VERSION "created by canmatrix"

NS_ :

BS_:

BU_: IMU_MMP2 MAP DMS VIC GWS MGW ADAS FVC CR_RL CR_RR CR_FL CR_FR FR_FC AVAP

BO_ 1141 EPS_0x475: 8 MGW
 SG_ EPS_ModSts : 10|2@0+ (1,0) [0|3] ""  ADAS

BO_ 453 EPS2ADAS_0x1C5: 12 MGW
 SG_ ADAS_1C5_CheckSum : 7|8@0+ (1,0) [0|255] ""  ADAS
 SG_ ADAS_1C5_AliveCounter : 11|4@0+ (1,0) [0|15] ""  ADAS
 SG_ EPS_ActRoadWheelAngValue : 23|16@0+ (0.005,-45) [-45|45] "degree"  ADAS
 SG_ EPS_ActRPCTrq : 39|11@0+ (0.02,-20.48) [-20.48|20.46] "Nm"  ADAS
 SG_ EPS_LatDrvLvl12SrvAvl : 44|2@0+ (1,0) [0|3] ""  ADAS
 SG_ EPS_IntRPCMaxTrq : 42|11@0+ (0.02,-20.48) [-20.48|20.46] "Nm"  ADAS
 SG_ EPS_IntRPCMinTrq : 63|11@0+ (0.02,-20.48) [-20.48|20.46] "Nm"  ADAS
 SG_ EPS_LatMCHptcWrnSrvAvl : 68|2@0+ (1,0) [0|3] ""  ADAS
 SG_ EPS_ActRoadWheelAngState : 66|2@0+ (1,0) [0|3] ""  ADAS
 SG_ EPS_LatMCRoadWheelAngActive : 64|1@0+ (1,0) [0|1] ""  ADAS

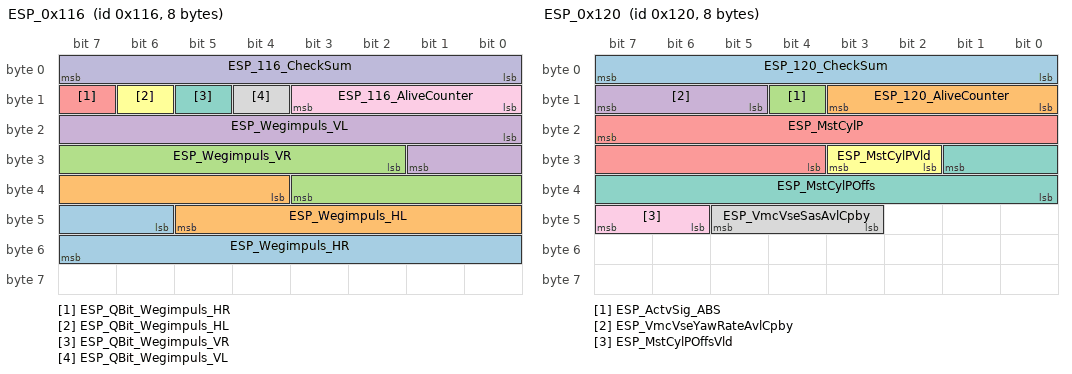
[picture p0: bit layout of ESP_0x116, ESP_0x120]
BO_ 278 ESP_0x116: 8 MGW
 SG_ ESP_Wegimpuls_HR : 46|10@1+ (1,0) [0|1000] ""  ADAS
 SG_ ESP_Wegimpuls_HL : 36|10@1+ (1,0) [0|1000] ""  ADAS
 SG_ ESP_Wegimpuls_VR : 26|10@1+ (1,0) [0|1000] ""  ADAS
 SG_ ESP_Wegimpuls_VL : 16|10@1+ (1,0) [0|1000] ""  ADAS
 SG_ ESP_QBit_Wegimpuls_HR : 15|1@1+ (1,0) [0|1] ""  ADAS
 SG_ ESP_QBit_Wegimpuls_HL : 14|1@1+ (1,0) [0|1] ""  ADAS
 SG_ ESP_QBit_Wegimpuls_VR : 13|1@1+ (1,0) [0|1] ""  ADAS
 SG_ ESP_QBit_Wegimpuls_VL : 12|1@1+ (1,0) [0|1] ""  ADAS
 SG_ ESP_116_AliveCounter : 8|4@1+ (1,0) [0|15] ""  ADAS
 SG_ ESP_116_CheckSum : 0|8@1+ (1,0) [0|255] ""  ADAS

BO_ 288 ESP_0x120: 8 MGW
 SG_ ESP_120_CheckSum : 7|8@0+ (1,0) [0|255] ""  ADAS,FVC,CR_RL,CR_RR,CR_FL,CR_FR,FR_FC
 SG_ ESP_120_AliveCounter : 11|4@0+ (1,0) [0|15] ""  ADAS,FVC,CR_RL,CR_RR,CR_FL,CR_FR,FR_FC
 SG_ ESP_ActvSig_ABS : 12|1@0+ (1,0) [0|1] ""  ADAS,FVC,CR_RL,CR_RR,CR_FL,CR_FR,FR_FC
 SG_ ESP_VmcVseYawRateAvlCpby : 15|3@0+ (1,0) [0|7] ""  ADAS,FR_FC
 SG_ ESP_MstCylP : 23|12@0+ (0.1,-30) [-30|276.6] "bar"  ADAS,FVC,CR_RL,CR_RR,CR_FL,CR_FR,FR_FC
 SG_ ESP_MstCylPVld : 27|2@0+ (1,0) [0|3] ""  ADAS,FVC,CR_RL,CR_RR,CR_FL,CR_FR,FR_FC
 SG_ ESP_MstCylPOffs : 25|10@0+ (0.1,-15) [-15|15] "bar"  ADAS,FVC,CR_RL,CR_RR,CR_FL,CR_FR,FR_FC
 SG_ ESP_VmcVseSasAvlCpby : 45|3@0+ (1,0) [0|7] ""  ADAS,FR_FC
 SG_ ESP_MstCylPOffsVld : 47|2@0+ (1,0) [0|3] ""  ADAS,FVC,CR_RL,CR_RR,CR_FL,CR_FR,FR_FC

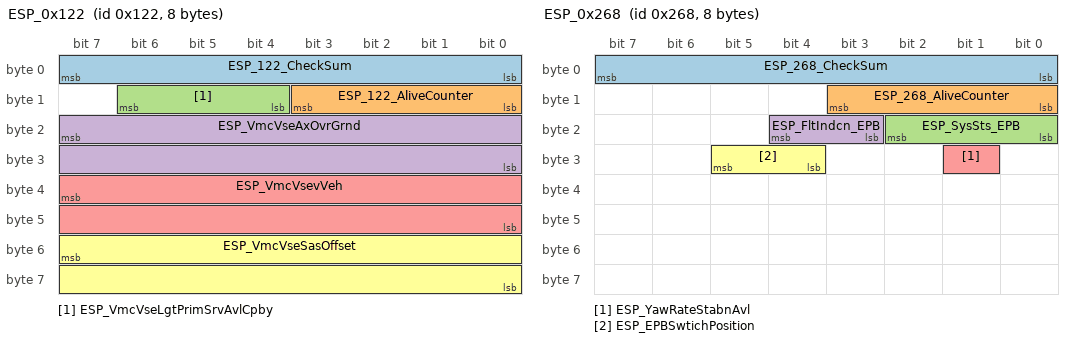
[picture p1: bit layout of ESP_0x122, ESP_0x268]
BO_ 290 ESP_0x122: 8 MGW
 SG_ ESP_122_CheckSum : 7|8@0+ (1,0) [0|255] ""  ADAS,FR_FC
 SG_ ESP_122_AliveCounter : 11|4@0+ (1,0) [0|15] ""  ADAS,FR_FC
 SG_ ESP_VmcVseLgtPrimSrvAvlCpby : 14|3@0+ (1,0) [0|7] ""  ADAS,FR_FC
 SG_ ESP_VmcVseAxOvrGrnd : 23|16@0+ (0.00125,-40.96) [-40.96|40.9575] "m/s2"  ADAS,FR_FC
 SG_ ESP_VmcVsevVeh : 39|16@0+ (0.01,-100) [-100|400] "kph"  ADAS,FR_FC
 SG_ ESP_VmcVseSasOffset : 55|16@0+ (0.1,-780) [-780|780] "°"  ADAS,FR_FC

BO_ 440 ESP_0x1B8: 8 MGW
 SG_ ESP_RoadSlop : 50|11@0+ (0.01,-10) [-10|10] "m/s2"  ADAS,FR_FC

BO_ 609 ESP_0x261: 8 MGW
 SG_ ESP_261_CheckSum : 7|8@0+ (1,0) [0|255] ""  ADAS,FVC,CR_RL,CR_RR,CR_FL,CR_FR,FR_FC
 SG_ ESP_261_AliveCounter : 11|4@0+ (1,0) [0|15] ""  ADAS,FVC,CR_RL,CR_RR,CR_FL,CR_FR,FR_FC
 SG_ ESP_ActvSig : 16|1@0+ (1,0) [0|1] ""  ADAS,FVC,CR_RL,CR_RR,CR_FL,CR_FR,FR_FC
 SG_ ESP_ActvSig_TCS : 17|1@0+ (1,0) [0|1] ""  ADAS,CR_RL,CR_RR,CR_FL,CR_FR,FR_FC
 SG_ ESP_ActvSig_EBD : 19|1@0+ (1,0) [0|1] ""  ADAS,CR_RL,CR_RR,CR_FL,CR_FR,FR_FC
 SG_ ESP_ActvSig_DTC : 20|1@0+ (1,0) [0|1] ""  ADAS,CR_RL,CR_RR,CR_FL,CR_FR,FR_FC
 SG_ ESP_Actvndcn_CDD : 24|1@0+ (1,0) [0|1] ""  ADAS
 SG_ ESP_FltIndcn_CDD : 25|1@0+ (1,0) [0|1] ""  ADAS
 SG_ ESP_ActvIndcn_ABA : 26|1@0+ (1,0) [0|1] ""  ADAS,FR_FC
 SG_ ESP_FltIndcn_ABA : 27|1@0+ (1,0) [0|1] ""  ADAS,FR_FC
 SG_ ESP_ActvIndcn_ABP : 28|1@0+ (1,0) [0|1] ""  ADAS,FR_FC
 SG_ ESP_FltIndcn_ABP : 29|1@0+ (1,0) [0|1] ""  ADAS,FR_FC
 SG_ ESP_ActvIndcn_AEB : 30|1@0+ (1,0) [0|1] ""  ADAS,CR_RL,CR_RR,FR_FC
 SG_ ESP_FltIndcn_AEB : 31|1@0+ (1,0) [0|1] ""  ADAS,CR_RL,CR_RR,FR_FC
 SG_ ESP_ActvIndcn_AWB : 32|1@0+ (1,0) [0|1] ""  ADAS,FR_FC
 SG_ ESP_FltIndcn_AWB : 33|1@0+ (1,0) [0|1] ""  ADAS,FR_FC
 SG_ ESP_VehStandstillIndcn : 35|2@0+ (1,0) [0|3] ""  ADAS,CR_RL,CR_RR,CR_FL,CR_FR,FR_FC
 SG_ ESP_BrkOverTIndcn : 36|1@0+ (1,0) [0|1] ""  ADAS,FR_FC

BO_ 616 ESP_0x268: 8 MGW
 SG_ ESP_268_CheckSum : 7|8@0+ (1,0) [0|255] ""  ADAS,FR_FC
 SG_ ESP_268_AliveCounter : 11|4@0+ (1,0) [0|15] ""  ADAS,FR_FC
 SG_ ESP_SysSts_EPB : 18|3@0+ (1,0) [0|7] ""  ADAS
 SG_ ESP_FltIndcn_EPB : 20|2@0+ (1,0) [0|3] ""  ADAS
 SG_ ESP_YawRateStabnAvl : 25|1@0+ (1,0) [0|1] ""  ADAS,FR_FC
 SG_ ESP_EPBSwtichPosition : 29|2@0+ (1,0) [0|3] ""  ADAS

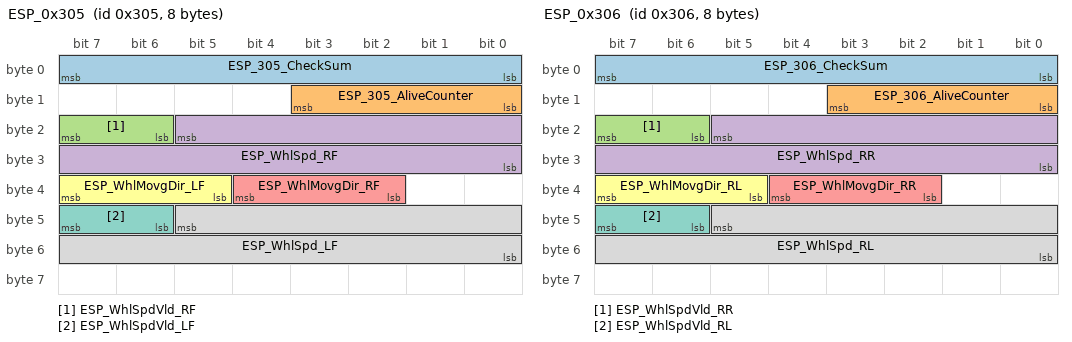
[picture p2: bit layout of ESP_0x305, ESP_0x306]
BO_ 773 ESP_0x305: 8 MGW
 SG_ ESP_305_CheckSum : 7|8@0+ (1,0) [0|255] ""  ADAS,FVC,CR_RL,CR_RR,CR_FL,CR_FR,FR_FC
 SG_ ESP_305_AliveCounter : 11|4@0+ (1,0) [0|15] ""  ADAS,FVC,CR_RL,CR_RR,CR_FL,CR_FR,FR_FC
 SG_ ESP_WhlSpdVld_RF : 23|2@0+ (1,0) [0|3] ""  ADAS,FVC,CR_RL,CR_RR,CR_FL,CR_FR,FR_FC
 SG_ ESP_WhlSpd_RF : 21|14@0+ (0.0625,0) [0|300] "km/h"  ADAS,FVC,CR_RL,CR_RR,CR_FL,CR_FR,FR_FC
 SG_ ESP_WhlMovgDir_RF : 36|3@0+ (1,0) [0|7] ""  ADAS,FVC,CR_RL,CR_RR,CR_FL,CR_FR,FR_FC
 SG_ ESP_WhlMovgDir_LF : 39|3@0+ (1,0) [0|7] ""  ADAS,FVC,CR_RL,CR_RR,CR_FL,CR_FR,FR_FC
 SG_ ESP_WhlSpdVld_LF : 47|2@0+ (1,0) [0|3] ""  ADAS,FVC,CR_RL,CR_RR,CR_FL,CR_FR,FR_FC
 SG_ ESP_WhlSpd_LF : 45|14@0+ (0.0625,0) [0|300] "km/h"  ADAS,FVC,CR_RL,CR_RR,CR_FL,CR_FR,FR_FC

BO_ 774 ESP_0x306: 8 MGW
 SG_ ESP_306_CheckSum : 7|8@0+ (1,0) [0|255] ""  ADAS,FVC,CR_RL,CR_RR,CR_FL,CR_FR,FR_FC
 SG_ ESP_306_AliveCounter : 11|4@0+ (1,0) [0|15] ""  ADAS,FVC,CR_RL,CR_RR,CR_FL,CR_FR,FR_FC
 SG_ ESP_WhlSpdVld_RR : 23|2@0+ (1,0) [0|3] ""  ADAS,FVC,CR_RL,CR_RR,CR_FL,CR_FR,FR_FC
 SG_ ESP_WhlSpd_RR : 21|14@0+ (0.0625,0) [0|300] "km/h"  ADAS,FVC,CR_RL,CR_RR,CR_FL,CR_FR,FR_FC
 SG_ ESP_WhlMovgDir_RR : 36|3@0+ (1,0) [0|7] ""  ADAS,FVC,CR_RL,CR_RR,CR_FL,CR_FR,FR_FC
 SG_ ESP_WhlMovgDir_RL : 39|3@0+ (1,0) [0|7] ""  ADAS,FVC,CR_RL,CR_RR,CR_FL,CR_FR,FR_FC
 SG_ ESP_WhlSpdVld_RL : 47|2@0+ (1,0) [0|3] ""  ADAS,FVC,CR_RL,CR_RR,CR_FL,CR_FR,FR_FC
 SG_ ESP_WhlSpd_RL : 45|14@0+ (0.0625,0) [0|300] "km/h"  ADAS,FVC,CR_RL,CR_RR,CR_FL,CR_FR,FR_FC

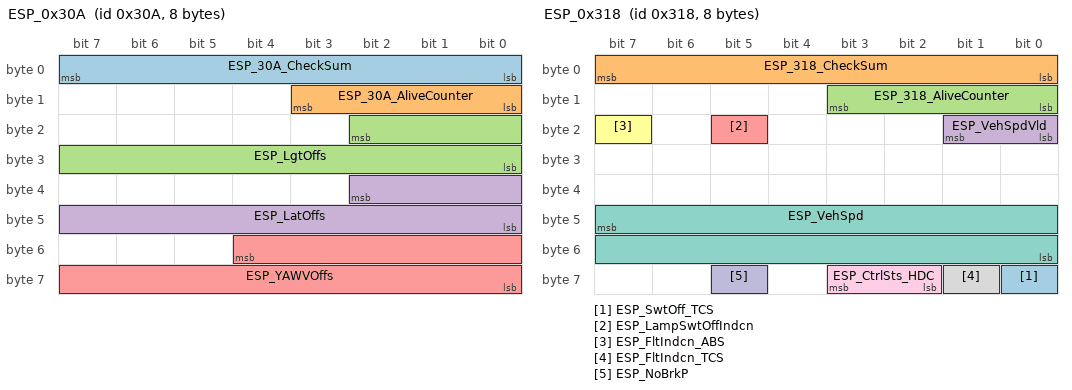
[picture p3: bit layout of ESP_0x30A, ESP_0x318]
BO_ 778 ESP_0x30A: 8 MGW
 SG_ ESP_30A_CheckSum : 7|8@0+ (1,0) [0|255] ""  ADAS,FVC,CR_RL,CR_RR,CR_FL,CR_FR,FR_FC
 SG_ ESP_30A_AliveCounter : 11|4@0+ (1,0) [0|15] ""  ADAS,FVC,CR_RL,CR_RR,CR_FL,CR_FR,FR_FC
 SG_ ESP_LgtOffs : 18|11@0+ (0.0027127,-2.15928) [-2.15928|2.15928] "g"  ADAS,FVC,FR_FC
 SG_ ESP_LatOffs : 34|11@0+ (0.0027127,-2.15928) [-2.15928|2.15928] "g"  ADAS,FVC,FR_FC
 SG_ ESP_YAWVOffs : 52|13@0+ (0.056,-120) [-120|120] "°/s"  ADAS,FVC,FR_FC

BO_ 792 ESP_0x318: 8 MGW
 SG_ ESP_SwtOff_TCS : 56|1@0+ (1,0) [0|1] "" Vector__XXX
 SG_ ESP_318_CheckSum : 7|8@0+ (1,0) [0|255] ""  ADAS,FVC,CR_RL,CR_RR,CR_FL,CR_FR,FR_FC
 SG_ ESP_318_AliveCounter : 11|4@0+ (1,0) [0|15] ""  ADAS,FVC,CR_RL,CR_RR,CR_FL,CR_FR,FR_FC
 SG_ ESP_VehSpdVld : 17|2@0+ (1,0) [0|3] ""  ADAS,FVC,CR_RL,CR_RR,CR_FL,CR_FR,FR_FC
 SG_ ESP_LampSwtOffIndcn : 21|1@0+ (1,0) [0|1] ""  ADAS,CR_RL,CR_RR,CR_FL,CR_FR,FR_FC
 SG_ ESP_FltIndcn_ABS : 23|1@0+ (1,0) [0|1] ""  ADAS,FVC,CR_RL,CR_RR,CR_FL,CR_FR,FR_FC
 SG_ ESP_VehSpd : 47|16@0+ (0.1,0) [0|300] "km/h"  ADAS,FVC,CR_RL,CR_RR,CR_FL,CR_FR,FR_FC
 SG_ ESP_FltIndcn_TCS : 57|1@0+ (1,0) [0|1] ""  ADAS,FVC,CR_RL,CR_RR,CR_FL,CR_FR,FR_FC
 SG_ ESP_CtrlSts_HDC : 59|2@0+ (1,0) [0|3] ""  ADAS,CR_RL,CR_RR,CR_FL,CR_FR,FR_FC
 SG_ ESP_NoBrkP : 61|1@0+ (1,0) [0|1] ""  ADAS,CR_RL,CR_RR,CR_FL,CR_FR,FR_FC

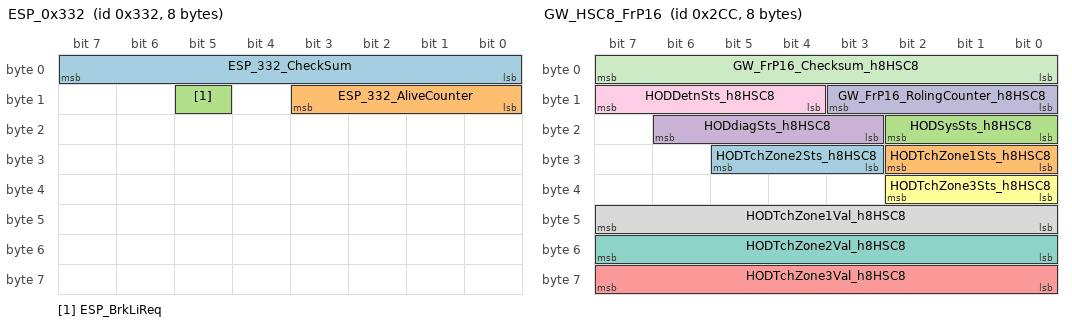
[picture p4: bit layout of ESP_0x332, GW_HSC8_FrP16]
BO_ 818 ESP_0x332: 8 MGW
 SG_ ESP_332_CheckSum : 7|8@0+ (1,0) [0|255] ""  ADAS,FR_FC
 SG_ ESP_332_AliveCounter : 11|4@0+ (1,0) [0|15] ""  ADAS,FR_FC
 SG_ ESP_BrkLiReq : 13|1@0+ (1,0) [0|1] ""  ADAS,FR_FC

BO_ 716 GW_HSC8_FrP16: 8 MGW
 SG_ HODTchZone2Sts_h8HSC8 : 27|3@1+ (1,0) [0|7] ""  ADAS
 SG_ HODTchZone1Sts_h8HSC8 : 24|3@1+ (1,0) [0|7] ""  ADAS
 SG_ HODSysSts_h8HSC8 : 16|3@1+ (1,0) [0|7] ""  ADAS
 SG_ HODdiagSts_h8HSC8 : 19|4@1+ (1,0) [0|15] ""  ADAS
 SG_ HODTchZone3Val_h8HSC8 : 56|8@1+ (1,0) [0|255] ""  ADAS
 SG_ HODTchZone3Sts_h8HSC8 : 32|3@1+ (1,0) [0|7] ""  ADAS
 SG_ HODTchZone2Val_h8HSC8 : 48|8@1+ (1,0) [0|255] ""  ADAS
 SG_ HODTchZone1Val_h8HSC8 : 40|8@1+ (1,0) [0|255] ""  ADAS
 SG_ HODDetnSts_h8HSC8 : 12|4@1+ (1,0) [0|15] ""  ADAS
 SG_ GW_FrP16_RolingCounter_h8HSC8 : 8|4@1+ (1,0) [0|15] ""  ADAS
 SG_ GW_FrP16_Checksum_h8HSC8 : 0|8@1+ (1,0) [0|255] ""  ADAS

BO_ 1554 HandoverIndication: 1 MGW
 SG_ HandoverIndication : 0|2@1+ (1,0) [0|3] ""  ADAS

BO_ 1218 HDM_Centerline_1: 64 MAP
 SG_ centerline_1_CRC : 0|16@1+ (1,0) [0|65535] ""  ADAS
 SG_ centerline_1_AliveCtr : 16|8@1+ (1,0) [0|255] ""  ADAS
 SG_ CenterPoint_dx_00 : 24|12@1+ (0.05,0) [0|204.75] "m"  ADAS
 SG_ CenterPoint_dy_00 : 36|12@1+ (0.05,-102.4) [-102.4|102.35] "m"  ADAS
 SG_ CenterPoint_dx_01 : 48|12@1+ (0.05,0) [0|204.75] "m"  ADAS
 SG_ CenterPoint_dy_01 : 60|12@1+ (0.05,-102.4) [-102.4|102.35] "m"  ADAS
 SG_ CenterPoint_dx_02 : 72|12@1+ (0.05,0) [0|204.75] "m"  ADAS
 SG_ CenterPoint_dy_02 : 84|12@1+ (0.05,-102.4) [-102.4|102.35] "m"  ADAS
 SG_ CenterPoint_dx_03 : 96|12@1+ (0.05,0) [0|204.75] "m"  ADAS
 SG_ CenterPoint_dy_03 : 108|12@1+ (0.05,-102.4) [-102.4|102.35] "m"  ADAS
 SG_ CenterPoint_dx_04 : 120|12@1+ (0.05,0) [0|204.75] "m"  ADAS
 SG_ CenterPoint_dy_04 : 132|12@1+ (0.05,-102.4) [-102.4|102.35] "m"  ADAS
 SG_ CenterPoint_dx_05 : 144|12@1+ (0.05,0) [0|204.75] "m"  ADAS
 SG_ CenterPoint_dy_05 : 156|12@1+ (0.05,-102.4) [-102.4|102.35] "m"  ADAS
 SG_ CenterPoint_dx_06 : 168|12@1+ (0.05,0) [0|204.75] "m"  ADAS
 SG_ CenterPoint_dy_06 : 180|12@1+ (0.05,-102.4) [-102.4|102.35] "m"  ADAS
 SG_ CenterPoint_dx_07 : 192|12@1+ (0.05,0) [0|204.75] "m"  ADAS
 SG_ CenterPoint_dy_07 : 204|12@1+ (0.05,-102.4) [-102.4|102.35] "m"  ADAS
 SG_ CenterPoint_dx_08 : 216|12@1+ (0.05,0) [0|204.75] "m"  ADAS
 SG_ CenterPoint_dy_08 : 228|12@1+ (0.05,-102.4) [-102.4|102.35] "m"  ADAS
 SG_ CenterPoint_dx_09 : 240|12@1+ (0.05,0) [0|204.75] "m"  ADAS
 SG_ CenterPoint_dy_09 : 252|12@1+ (0.05,-102.4) [-102.4|102.35] "m"  ADAS
 SG_ CenterPoint_dx_10 : 264|12@1+ (0.05,0) [0|204.75] "m"  ADAS
 SG_ CenterPoint_dy_10 : 276|12@1+ (0.05,-102.4) [-102.4|102.35] "m"  ADAS
 SG_ CenterPoint_dx_11 : 288|12@1+ (0.05,0) [0|204.75] "m"  ADAS
 SG_ CenterPoint_dy_11 : 300|12@1+ (0.05,-102.4) [-102.4|102.35] "m"  ADAS
 SG_ CenterPoint_dx_12 : 312|12@1+ (0.05,0) [0|204.75] "m"  ADAS
 SG_ CenterPoint_dy_12 : 324|12@1+ (0.05,-102.4) [-102.4|102.35] "m"  ADAS
 SG_ CenterPoint_dx_13 : 336|12@1+ (0.05,0) [0|204.75] "m"  ADAS
 SG_ CenterPoint_dy_13 : 348|12@1+ (0.05,-102.4) [-102.4|102.35] "m"  ADAS
 SG_ CenterPoint_dx_14 : 360|12@1+ (0.05,0) [0|204.75] "m"  ADAS
 SG_ CenterPoint_dy_14 : 372|12@1+ (0.05,-102.4) [-102.4|102.35] "m"  ADAS
 SG_ CenterPoint_dx_15 : 384|12@1+ (0.05,0) [0|204.75] "m"  ADAS
 SG_ CenterPoint_dy_15 : 396|12@1+ (0.05,-102.4) [-102.4|102.35] "m"  ADAS
 SG_ CenterPoint_dx_16 : 408|12@1+ (0.05,0) [0|204.75] "m"  ADAS
 SG_ CenterPoint_dy_16 : 420|12@1+ (0.05,-102.4) [-102.4|102.35] "m"  ADAS
 SG_ CenterPoint_dx_17 : 432|12@1+ (0.05,0) [0|204.75] "m"  ADAS
 SG_ CenterPoint_dy_17 : 444|12@1+ (0.05,-102.4) [-102.4|102.35] "m"  ADAS
 SG_ CenterPoint_dx_18 : 456|12@1+ (0.05,0) [0|204.75] "m"  ADAS
 SG_ CenterPoint_dy_18 : 468|12@1+ (0.05,-102.4) [-102.4|102.35] "m"  ADAS
 SG_ CenterPoint_dx_19 : 480|12@1+ (0.05,0) [0|204.75] "m"  ADAS
 SG_ CenterPoint_dy_19 : 492|12@1+ (0.05,-102.4) [-102.4|102.35] "m"  ADAS
 SG_ centerline_1_BlockCtr : 504|4@1+ (1,0) [0|15] ""  ADAS

BO_ 1219 HDM_Centerline_2: 64 MAP
 SG_ centerline_2_CRC : 0|16@1+ (1,0) [0|65535] ""  ADAS
 SG_ centerline_2_AliveCtr : 16|8@1+ (1,0) [0|255] ""  ADAS
 SG_ CenterPoint_dx_20 : 24|12@1+ (0.05,0) [0|204.75] "m"  ADAS
 SG_ CenterPoint_dy_20 : 36|12@1+ (0.05,-102.4) [-102.4|102.35] "m"  ADAS
 SG_ CenterPoint_dx_21 : 48|12@1+ (0.05,0) [0|204.75] "m"  ADAS
 SG_ CenterPoint_dy_21 : 60|12@1+ (0.05,-102.4) [-102.4|102.35] "m"  ADAS
 SG_ CenterPoint_dx_22 : 72|12@1+ (0.05,0) [0|204.75] "m"  ADAS
 SG_ CenterPoint_dy_22 : 84|12@1+ (0.05,-102.4) [-102.4|102.35] "m"  ADAS
 SG_ CenterPoint_dx_23 : 96|12@1+ (0.05,0) [0|204.75] "m"  ADAS
 SG_ CenterPoint_dy_23 : 108|12@1+ (0.05,-102.4) [-102.4|102.35] "m"  ADAS
 SG_ CenterPoint_dx_24 : 120|12@1+ (0.05,0) [0|204.75] "m"  ADAS
 SG_ CenterPoint_dy_24 : 132|12@1+ (0.05,-102.4) [-102.4|102.35] "m"  ADAS
 SG_ CenterPoint_dx_25 : 144|12@1+ (0.05,0) [0|204.75] "m"  ADAS
 SG_ CenterPoint_dy_25 : 156|12@1+ (0.05,-102.4) [-102.4|102.35] "m"  ADAS
 SG_ CenterPoint_dx_26 : 168|12@1+ (0.05,0) [0|204.75] "m"  ADAS
 SG_ CenterPoint_dy_26 : 180|12@1+ (0.05,-102.4) [-102.4|102.35] "m"  ADAS
 SG_ CenterPoint_dx_27 : 192|12@1+ (0.05,0) [0|204.75] "m"  ADAS
 SG_ CenterPoint_dy_27 : 204|12@1+ (0.05,-102.4) [-102.4|102.35] "m"  ADAS
 SG_ CenterPoint_dx_28 : 216|12@1+ (0.05,0) [0|204.75] "m"  ADAS
 SG_ CenterPoint_dy_28 : 228|12@1+ (0.05,-102.4) [-102.4|102.35] "m"  ADAS
 SG_ CenterPoint_dx_29 : 240|12@1+ (0.05,0) [0|204.75] "m"  ADAS
 SG_ CenterPoint_dy_29 : 252|12@1+ (0.05,-102.4) [-102.4|102.35] "m"  ADAS
 SG_ CenterPoint_dx_30 : 264|12@1+ (0.05,0) [0|204.75] "m"  ADAS
 SG_ CenterPoint_dy_30 : 276|12@1+ (0.05,-102.4) [-102.4|102.35] "m"  ADAS
 SG_ CenterPoint_dx_31 : 288|12@1+ (0.05,0) [0|204.75] "m"  ADAS
 SG_ CenterPoint_dy_31 : 300|12@1+ (0.05,-102.4) [-102.4|102.35] "m"  ADAS
 SG_ CenterPoint_dx_32 : 312|12@1+ (0.05,0) [0|204.75] "m"  ADAS
 SG_ CenterPoint_dy_32 : 324|12@1+ (0.05,-102.4) [-102.4|102.35] "m"  ADAS
 SG_ CenterPoint_dx_33 : 336|12@1+ (0.05,0) [0|204.75] "m"  ADAS
 SG_ CenterPoint_dy_33 : 348|12@1+ (0.05,-102.4) [-102.4|102.35] "m"  ADAS
 SG_ CenterPoint_dx_34 : 360|12@1+ (0.05,0) [0|204.75] "m"  ADAS
 SG_ CenterPoint_dy_34 : 372|12@1+ (0.05,-102.4) [-102.4|102.35] "m"  ADAS
 SG_ centerline_LaneWidth : 384|9@1+ (1,0) [0|511] "cm"  ADAS
 SG_ localization_lat_StdDev : 393|12@1+ (0.01,0) [0|40.95] "m"  ADAS
 SG_ localization_long_StdDev : 405|12@1+ (0.01,0) [0|40.95] "m"  ADAS
 SG_ localization_heading_StdDev : 417|11@1+ (0.1,0) [0|204.7] "degree"  ADAS
 SG_ map_position_deviation : 428|12@1+ (1,0) [0|4095] "cm"  ADAS
 SG_ map_position_accuracy : 440|12@1+ (1,0) [0|4095] "cm"  ADAS
 SG_ Timestamp : 452|20@1+ (0.00065536,0) [0|687.194112] "s"  ADAS
 SG_ centerline_2_BlockCtr : 472|4@1+ (1,0) [0|15] ""  ADAS

BO_ 1221 HDM_Central_Line_HighR: 64 MAP
 SG_ centerline_HR_CRC : 0|16@1+ (1,0) [0|65535] ""  ADAS
 SG_ centerline_HR_AliveCtr : 16|8@1+ (1,0) [0|255] ""  ADAS
 SG_ centerline_HR_BlockCtr : 24|4@1+ (1,0) [0|15] ""  ADAS
 SG_ CenterPoint_dx_m01_HighR : 28|6@1+ (0.001,0) [0|0.049] "m"  ADAS
 SG_ CenterPoint_dy_m01_HighR : 34|6@1+ (0.001,0) [0|0.049] "m"  ADAS
 SG_ CenterPoint_dy_m02_HighR : 40|6@1+ (0.001,0) [0|0.049] "m"  ADAS
 SG_ CenterPoint_dx_m02_HighR : 46|6@1+ (0.001,0) [0|0.049] "m"  ADAS
 SG_ CenterPoint_dy_m03_HighR : 52|6@1+ (0.001,0) [0|0.049] "m"  ADAS
 SG_ CenterPoint_dx_m03_HighR : 58|6@1+ (0.001,0) [0|0.049] "m"  ADAS
 SG_ CenterPoint_dy_m04_HighR : 64|6@1+ (0.001,0) [0|0.049] "m"  ADAS
 SG_ CenterPoint_dx_m04_HighR : 70|6@1+ (0.001,0) [0|0.049] "m"  ADAS
 SG_ CenterPoint_dy_00_HighR : 76|6@1+ (0.001,0) [0|0.049] "m"  ADAS
 SG_ CenterPoint_dx_00_HighR : 82|6@1+ (0.001,0) [0|0.049] "m"  ADAS
 SG_ CenterPoint_dy_01_HighR : 88|6@1+ (0.001,0) [0|0.049] "m"  ADAS
 SG_ CenterPoint_dx_01_HighR : 94|6@1+ (0.001,0) [0|0.049] "m"  ADAS
 SG_ CenterPoint_dy_02_HighR : 100|6@1+ (0.001,0) [0|0.049] "m"  ADAS
 SG_ CenterPoint_dx_02_HighR : 106|6@1+ (0.001,0) [0|0.049] "m"  ADAS
 SG_ CenterPoint_dy_03_HighR : 112|6@1+ (0.001,0) [0|0.049] "m"  ADAS
 SG_ CenterPoint_dx_03_HighR : 118|6@1+ (0.001,0) [0|0.049] "m"  ADAS
 SG_ CenterPoint_dy_04_HighR : 124|6@1+ (0.001,0) [0|0.049] "m"  ADAS
 SG_ CenterPoint_dx_04_HighR : 130|6@1+ (0.001,0) [0|0.049] "m"  ADAS
 SG_ CenterPoint_dy_05_HighR : 136|6@1+ (0.001,0) [0|0.049] "m"  ADAS
 SG_ CenterPoint_dx_05_HighR : 142|6@1+ (0.001,0) [0|0.049] "m"  ADAS
 SG_ CenterPoint_dy_06_HighR : 148|6@1+ (0.001,0) [0|0.049] "m"  ADAS
 SG_ CenterPoint_dx_06_HighR : 154|6@1+ (0.001,0) [0|0.049] "m"  ADAS
 SG_ CenterPoint_dy_07_HighR : 160|6@1+ (0.001,0) [0|0.049] "m"  ADAS
 SG_ CenterPoint_dx_07_HighR : 166|6@1+ (0.001,0) [0|0.049] "m"  ADAS
 SG_ CenterPoint_dy_08_HighR : 172|6@1+ (0.001,0) [0|0.049] "m"  ADAS
 SG_ CenterPoint_dx_08_HighR : 178|6@1+ (0.001,0) [0|0.049] "m"  ADAS
 SG_ CenterPoint_dy_09_HighR : 184|6@1+ (0.001,0) [0|0.049] "m"  ADAS
 SG_ CenterPoint_dx_09_HighR : 190|6@1+ (0.001,0) [0|0.049] "m"  ADAS
 SG_ CenterPoint_dy_10_HighR : 196|6@1+ (0.001,0) [0|0.049] "m"  ADAS
 SG_ CenterPoint_dx_10_HighR : 202|6@1+ (0.001,0) [0|0.049] "m"  ADAS
 SG_ CenterPoint_dy_11_HighR : 208|6@1+ (0.001,0) [0|0.049] "m"  ADAS
 SG_ CenterPoint_dx_11_HighR : 214|6@1+ (0.001,0) [0|0.049] "m"  ADAS
 SG_ CenterPoint_dy_12_HighR : 220|6@1+ (0.001,0) [0|0.049] "m"  ADAS
 SG_ CenterPoint_dx_12_HighR : 226|6@1+ (0.001,0) [0|0.049] "m"  ADAS
 SG_ CenterPoint_dy_13_HighR : 232|6@1+ (0.001,0) [0|0.049] "m"  ADAS
 SG_ CenterPoint_dx_13_HighR : 238|6@1+ (0.001,0) [0|0.049] "m"  ADAS
 SG_ CenterPoint_dy_14_HighR : 244|6@1+ (0.001,0) [0|0.049] "m"  ADAS
 SG_ CenterPoint_dx_14_HighR : 250|6@1+ (0.001,0) [0|0.049] "m"  ADAS
 SG_ CenterPoint_dy_15_HighR : 256|6@1+ (0.001,0) [0|0.049] "m"  ADAS
 SG_ CenterPoint_dx_15_HighR : 262|6@1+ (0.001,0) [0|0.049] "m"  ADAS
 SG_ CenterPoint_dy_16_HighR : 268|6@1+ (0.001,0) [0|0.049] "m"  ADAS
 SG_ CenterPoint_dx_16_HighR : 274|6@1+ (0.001,0) [0|0.049] "m"  ADAS
 SG_ CenterPoint_dy_17_HighR : 280|6@1+ (0.001,0) [0|0.049] "m"  ADAS
 SG_ CenterPoint_dx_17_HighR : 286|6@1+ (0.001,0) [0|0.049] "m"  ADAS
 SG_ CenterPoint_dy_18_HighR : 292|6@1+ (0.001,0) [0|0.049] "m"  ADAS
 SG_ CenterPoint_dx_18_HighR : 298|6@1+ (0.001,0) [0|0.049] "m"  ADAS
 SG_ CenterPoint_dy_19_HighR : 304|6@1+ (0.001,0) [0|0.049] "m"  ADAS
 SG_ CenterPoint_dx_19_HighR : 310|6@1+ (0.001,0) [0|0.049] "m"  ADAS
 SG_ CenterPoint_dy_20_HighR : 316|6@1+ (0.001,0) [0|0.049] "m"  ADAS
 SG_ CenterPoint_dx_20_HighR : 322|6@1+ (0.001,0) [0|0.049] "m"  ADAS
 SG_ CenterPoint_dy_21_HighR : 328|6@1+ (0.001,0) [0|0.049] "m"  ADAS
 SG_ CenterPoint_dx_21_HighR : 334|6@1+ (0.001,0) [0|0.049] "m"  ADAS
 SG_ CenterPoint_dy_22_HighR : 340|6@1+ (0.001,0) [0|0.049] "m"  ADAS
 SG_ CenterPoint_dx_22_HighR : 346|6@1+ (0.001,0) [0|0.049] "m"  ADAS
 SG_ CenterPoint_dy_23_HighR : 352|6@1+ (0.001,0) [0|0.049] "m"  ADAS
 SG_ CenterPoint_dx_23_HighR : 358|6@1+ (0.001,0) [0|0.049] "m"  ADAS
 SG_ CenterPoint_dy_24_HighR : 364|6@1+ (0.001,0) [0|0.049] "m"  ADAS
 SG_ CenterPoint_dx_24_HighR : 370|6@1+ (0.001,0) [0|0.049] "m"  ADAS
 SG_ CenterPoint_dy_25_HighR : 376|6@1+ (0.001,0) [0|0.049] "m"  ADAS
 SG_ CenterPoint_dx_25_HighR : 382|6@1+ (0.001,0) [0|0.049] "m"  ADAS
 SG_ CenterPoint_dy_26_HighR : 388|6@1+ (0.001,0) [0|0.049] "m"  ADAS
 SG_ CenterPoint_dx_26_HighR : 394|6@1+ (0.001,0) [0|0.049] "m"  ADAS
 SG_ CenterPoint_dy_27_HighR : 400|6@1+ (0.001,0) [0|0.049] "m"  ADAS
 SG_ CenterPoint_dx_27_HighR : 406|6@1+ (0.001,0) [0|0.049] "m"  ADAS
 SG_ CenterPoint_dy_28_HighR : 412|6@1+ (0.001,0) [0|0.049] "m"  ADAS
 SG_ CenterPoint_dx_28_HighR : 418|6@1+ (0.001,0) [0|0.049] "m"  ADAS
 SG_ CenterPoint_dy_29_HighR : 424|6@1+ (0.001,0) [0|0.049] "m"  ADAS
 SG_ CenterPoint_dx_29_HighR : 430|6@1+ (0.001,0) [0|0.049] "m"  ADAS
 SG_ CenterPoint_dy_30_HighR : 436|6@1+ (0.001,0) [0|0.049] "m"  ADAS
 SG_ CenterPoint_dx_30_HighR : 442|6@1+ (0.001,0) [0|0.049] "m"  ADAS
 SG_ CenterPoint_dy_31_HighR : 448|6@1+ (0.001,0) [0|0.049] "m"  ADAS
 SG_ CenterPoint_dx_31_HighR : 454|6@1+ (0.001,0) [0|0.049] "m"  ADAS
 SG_ CenterPoint_dy_32_HighR : 460|6@1+ (0.001,0) [0|0.049] "m"  ADAS
 SG_ CenterPoint_dx_32_HighR : 466|6@1+ (0.001,0) [0|0.049] "m"  ADAS
 SG_ CenterPoint_dy_33_HighR : 472|6@1+ (0.001,0) [0|0.049] "m"  ADAS
 SG_ CenterPoint_dx_33_HighR : 478|6@1+ (0.001,0) [0|0.049] "m"  ADAS
 SG_ CenterPoint_dy_34_HighR : 484|6@1+ (0.001,0) [0|0.049] "m"  ADAS
 SG_ CenterPoint_dx_34_HighR : 490|6@1+ (0.001,0) [0|0.049] "m"  ADAS

BO_ 1220 HDM_Central_Line_M: 24 MAP
 SG_ centerline_m_CRC : 0|16@1+ (1,0) [0|65535] ""  ADAS
 SG_ centerline_m_AliveCtr : 16|8@1+ (1,0) [0|255] ""  ADAS
 SG_ centerline_m_BlockCtr : 24|4@1+ (1,0) [0|15] ""  ADAS
 SG_ CenterPoint_dx_m01 : 28|10@1+ (0.05,-50) [-50|0] "m"  ADAS
 SG_ CenterPoint_dy_m01 : 38|12@1+ (0.05,-102.4) [-102.4|102.35] "m"  ADAS
 SG_ CenterPoint_dx_m02 : 50|10@1+ (0.05,-50) [-50|0] "m"  ADAS
 SG_ CenterPoint_dy_m02 : 60|12@1+ (0.05,-102.4) [-102.4|102.35] "m"  ADAS
 SG_ CenterPoint_dx_m03 : 72|10@1+ (0.05,-50) [-50|0] "m"  ADAS
 SG_ CenterPoint_dy_m03 : 82|12@1+ (0.05,-102.4) [-102.4|102.35] "m"  ADAS
 SG_ CenterPoint_dx_m04 : 94|10@1+ (0.05,-50) [-50|0] "m"  ADAS
 SG_ CenterPoint_dy_m04 : 104|12@1+ (0.05,-102.4) [-102.4|102.35] "m"  ADAS
 SG_ MAP_TimeSync : 116|48@1+ (1,0) [0|39636172800000] "ms"  ADAS

BO_ 1217 HDM_Curv: 64 MAP
 SG_ Cv_CRC : 0|16@1+ (1,0) [0|65535] ""  ADAS
 SG_ Cv_AliveCtr : 16|8@1+ (1,0) [0|255] ""  ADAS
 SG_ Cv_Value_Seg00 : 32|10@1+ (0.0001,0) [0|0.1] "1/m"  ADAS
 SG_ Cv_Value_Seg01 : 42|10@1+ (0.0001,0) [0|0.1] "1/m"  ADAS
 SG_ Cv_Value_Seg02 : 52|10@1+ (0.0001,0) [0|0.1] "1/m"  ADAS
 SG_ Cv_Value_Seg03 : 62|10@1+ (0.0001,0) [0|0.1] "1/m"  ADAS
 SG_ Cv_Value_Seg04 : 72|10@1+ (0.0001,0) [0|0.1] "1/m"  ADAS
 SG_ Cv_Value_Seg05 : 82|10@1+ (0.0001,0) [0|0.1] "1/m"  ADAS
 SG_ Cv_Value_Seg06 : 92|10@1+ (0.0001,0) [0|0.1] "1/m"  ADAS
 SG_ Cv_Value_Seg07 : 102|10@1+ (0.0001,0) [0|0.1] "1/m"  ADAS
 SG_ Cv_Value_Seg08 : 112|10@1+ (0.0001,0) [0|0.1] "1/m"  ADAS
 SG_ Cv_Value_Seg09 : 122|10@1+ (0.0001,0) [0|0.1] "1/m"  ADAS
 SG_ Cv_Value_Seg10 : 132|10@1+ (0.0001,0) [0|0.1] "1/m"  ADAS
 SG_ Cv_Value_Seg11 : 142|10@1+ (0.0001,0) [0|0.1] "1/m"  ADAS
 SG_ Cv_Value_Seg12 : 152|10@1+ (0.0001,0) [0|0.1] "1/m"  ADAS
 SG_ Cv_Value_Seg13 : 162|10@1+ (0.0001,0) [0|0.1] "1/m"  ADAS
 SG_ Cv_Value_Seg14 : 172|10@1+ (0.0001,0) [0|0.1] "1/m"  ADAS
 SG_ Cv_Value_Seg15 : 182|10@1+ (0.0001,0) [0|0.1] "1/m"  ADAS
 SG_ Cv_Value_Seg16 : 192|10@1+ (0.0001,0) [0|0.1] "1/m"  ADAS
 SG_ Cv_Value_Seg17 : 202|10@1+ (0.0001,0) [0|0.1] "1/m"  ADAS
 SG_ Cv_Value_Seg18 : 212|10@1+ (0.0001,0) [0|0.1] "1/m"  ADAS
 SG_ Cv_Value_Seg19 : 222|10@1+ (0.0001,0) [0|0.1] "1/m"  ADAS
 SG_ Cv_Offset_Seg00 : 232|10@1+ (1,0) [0|1023] "m"  ADAS
 SG_ Cv_Offset_Seg01 : 242|10@1+ (1,0) [0|1023] "m"  ADAS
 SG_ Cv_Offset_Seg02 : 252|10@1+ (1,0) [0|1023] "m"  ADAS
 SG_ Cv_Offset_Seg03 : 262|10@1+ (1,0) [0|1023] "m"  ADAS
 SG_ Cv_Offset_Seg04 : 272|10@1+ (1,0) [0|1023] "m"  ADAS
 SG_ Cv_Offset_Seg05 : 282|10@1+ (1,0) [0|1023] "m"  ADAS
 SG_ Cv_Offset_Seg06 : 292|10@1+ (1,0) [0|1023] "m"  ADAS
 SG_ Cv_Offset_Seg07 : 302|10@1+ (1,0) [0|1023] "m"  ADAS
 SG_ Cv_Offset_Seg08 : 312|10@1+ (1,0) [0|1023] "m"  ADAS
 SG_ Cv_Offset_Seg09 : 322|10@1+ (1,0) [0|1023] "m"  ADAS
 SG_ Cv_Offset_Seg10 : 332|10@1+ (1,0) [0|1023] "m"  ADAS
 SG_ Cv_Offset_Seg11 : 342|10@1+ (1,0) [0|1023] "m"  ADAS
 SG_ Cv_Offset_Seg12 : 352|10@1+ (1,0) [0|1023] "m"  ADAS
 SG_ Cv_Offset_Seg13 : 362|10@1+ (1,0) [0|1023] "m"  ADAS
 SG_ Cv_Offset_Seg14 : 372|10@1+ (1,0) [0|1023] "m"  ADAS
 SG_ Cv_Offset_Seg15 : 382|10@1+ (1,0) [0|1023] "m"  ADAS
 SG_ Cv_Offset_Seg16 : 392|10@1+ (1,0) [0|1023] "m"  ADAS
 SG_ Cv_Offset_Seg17 : 402|10@1+ (1,0) [0|1023] "m"  ADAS
 SG_ Cv_Offset_Seg18 : 412|10@1+ (1,0) [0|1023] "m"  ADAS
 SG_ Cv_Offset_Seg19 : 422|10@1+ (1,0) [0|1023] "m"  ADAS

BO_ 1216 HDM_GF: 32 MAP
 SG_ GF_map_position_accuracy : 200|12@1+ (1,0) [0|4095] "cm"  ADAS
 SG_ GF_map_position_deviation : 188|12@1+ (1,0) [0|4095] "cm"  ADAS
 SG_ GF_CRC : 0|16@1+ (1,0) [0|65535] ""  ADAS
 SG_ GF_AliveCtr : 16|8@1+ (1,0) [0|255] ""  ADAS
 SG_ GF_Currentlane_Index : 176|8@1+ (1,0) [0|255] ""  ADAS
 SG_ GF_NumberOfLanes : 184|4@1+ (1,0) [0|15] ""  ADAS
 SG_ GF_Region_outOfODD_offset : 24|10@1+ (1,0) [0|1023] "m"  ADAS
 SG_ GF_Country_outOfODD_offset : 34|10@1+ (1,0) [0|1023] "m"  ADAS
 SG_ GF_LaneTrans_outOfODD_offset : 44|10@1+ (1,0) [0|1023] "m"  ADAS
 SG_ GF_Curvature_outOfODD_offset : 54|10@1+ (1,0) [0|1023] "m"  ADAS
 SG_ GF_LaneType_outOfODD_offset : 64|10@1+ (1,0) [0|1023] "m"  ADAS
 SG_ GF_RoadSlope_outOfODD_offset : 74|10@1+ (1,0) [0|1023] "m"  ADAS
 SG_ GF_LaneWidth_outOfODD_offset : 84|10@1+ (1,0) [0|1023] "m"  ADAS
 SG_ GF_FormOfWay_outOfODD_offset : 94|10@1+ (1,0) [0|1023] "m"  ADAS
 SG_ GF_MapExpired : 224|1@1+ (1,0) [0|1] "boolean"  ADAS
 SG_ GF_BlackListedSegment_offset : 114|10@1+ (1,0) [0|1023] "m"  ADAS
 SG_ GF_Intersection_offset : 104|10@1+ (1,0) [0|1023] "m"  ADAS
 SG_ GF_SideWind_offset : 124|10@1+ (1,0) [0|1023] "m"  ADAS
 SG_ GF_ActiveSpeedLimit : 168|8@1+ (1,0) [0|255] "km/h"  ADAS
 SG_ GF_TollGate_offset : 134|10@1+ (1,0) [0|1023] "m"  ADAS
 SG_ GF_TrafficLight_offset : 144|10@1+ (1,0) [0|1023] "m"  ADAS
 SG_ GF_Tunnel_Offset : 154|10@1+ (1,0) [0|1023] "m"  ADAS
 SG_ GF_MapStatus : 212|10@1+ (1,0) [0|1023] ""  ADAS

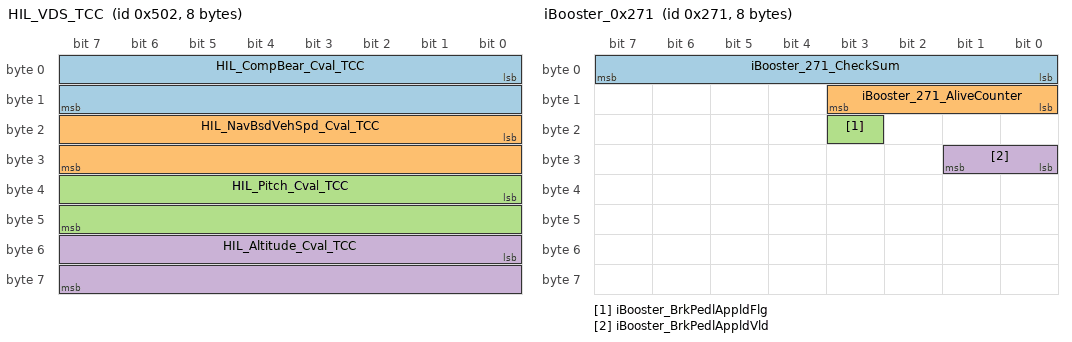
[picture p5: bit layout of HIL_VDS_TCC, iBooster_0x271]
BO_ 1282 HIL_VDS_TCC: 8 MGW
 SG_ HIL_CompBear_Cval_TCC : 0|16@1+ (0.0078125,0) [0|501.9921875] "?"  ADAS
 SG_ HIL_NavBsdVehSpd_Cval_TCC : 16|16@1+ (0.00390625,0) [0|250.99609375] "km/h"  ADAS
 SG_ HIL_Pitch_Cval_TCC : 32|16@1+ (0.0078125,-200) [-200|301.9921875] "?"  ADAS
 SG_ HIL_Altitude_Cval_TCC : 48|16@1+ (0.125,-2500) [-2500|5531.875] "m"  ADAS

BO_ 1283 HIL_VP_TCC: 8 MGW
 SG_ HIL_Latitude_Cval_TCC : 0|32@1+ (1E-007,-210) [-210|211.1081215] "?"  ADAS
 SG_ HIL_Longitude_Cval_TCC : 32|32@1+ (1E-007,-210) [-210|211.1081215] "?"  ADAS

BO_ 625 iBooster_0x271: 8 MGW
 SG_ iBooster_271_CheckSum : 7|8@0+ (1,0) [0|255] ""  ADAS,FVC,CR_RL,CR_RR,CR_FL,CR_FR,FR_FC
 SG_ iBooster_271_AliveCounter : 11|4@0+ (1,0) [0|15] ""  ADAS,FVC,CR_RL,CR_RR,CR_FL,CR_FR,FR_FC
 SG_ iBooster_BrkPedlAppldFlg : 19|1@0+ (1,0) [0|1] ""  ADAS,FVC,CR_RL,CR_RR,CR_FL,CR_FR,FR_FC
 SG_ iBooster_BrkPedlAppldVld : 25|2@0+ (1,0) [0|3] ""  ADAS,FVC,CR_RL,CR_RR,CR_FL,CR_FR,FR_FC

BO_ 592 ICC_0x250: 8 MGW
 SG_ EHU_SegFuncRoadClass : 34|3@0+ (1,0) [0|7] ""  ADAS,FVC
 SG_ EHU_SegEffSpdLmtType : 50|3@0+ (1,0) [0|7] ""  ADAS,FVC

BO_ 593 ICC_0x251: 8 MGW
 SG_ EHU_StubFuncRoadClass : 34|3@0+ (1,0) [0|7] ""  ADAS,FVC
 SG_ EHU_StubTurnAngl : 55|8@0+ (1.417,0) [0|358] "degrees"  ADAS,FVC

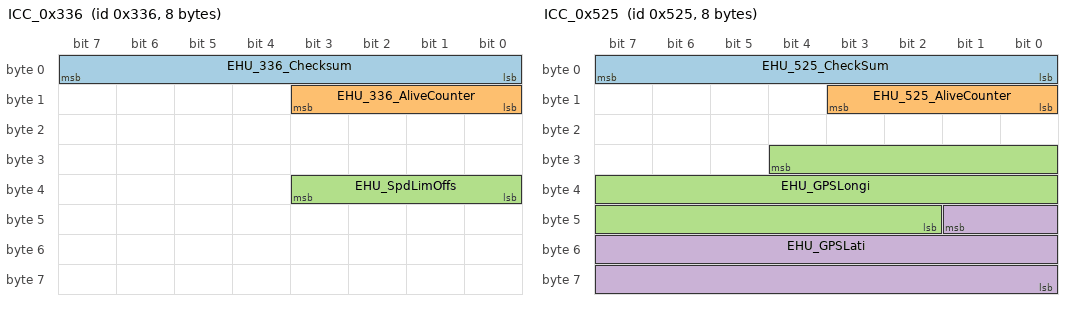
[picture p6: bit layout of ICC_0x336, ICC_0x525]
BO_ 822 ICC_0x336: 8 MGW
 SG_ EHU_336_Checksum : 7|8@0+ (1,0) [0|255] ""  ADAS,FVC
 SG_ EHU_336_AliveCounter : 11|4@0+ (1,0) [0|15] ""  ADAS,FVC
 SG_ EHU_SpdLimOffs : 35|4@0+ (1,0) [0|15] ""  ADAS,FVC

BO_ 1317 ICC_0x525: 8 MGW
 SG_ EHU_525_CheckSum : 7|8@0+ (1,0) [0|255] ""  ADAS,FR_FC
 SG_ EHU_525_AliveCounter : 11|4@0+ (1,0) [0|15] ""  ADAS,FR_FC
 SG_ EHU_GPSLongi : 28|19@0+ (0.001,-180) [-180|179.99] "°"  ADAS,FR_FC
 SG_ EHU_GPSLati : 41|18@0+ (0.001,-90) [-90|90] "°"  ADAS,FR_FC

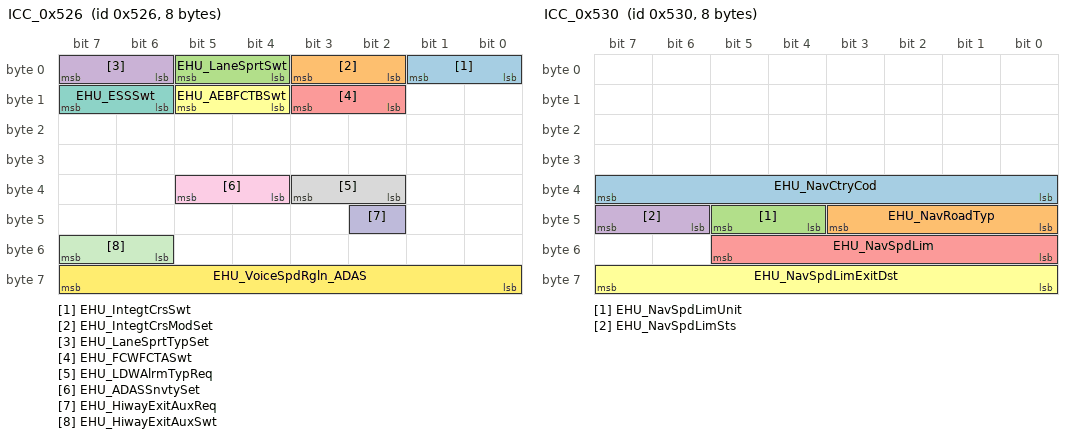
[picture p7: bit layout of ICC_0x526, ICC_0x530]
BO_ 1318 ICC_0x526: 8 MGW
 SG_ EHU_IntegtCrsSwt : 1|2@0+ (1,0) [0|3] ""  ADAS
 SG_ EHU_IntegtCrsModSet : 3|2@0+ (1,0) [0|3] ""  ADAS
 SG_ EHU_LaneSprtSwt : 5|2@0+ (1,0) [0|3] ""  ADAS
 SG_ EHU_LaneSprtTypSet : 7|2@0+ (1,0) [0|3] ""  ADAS
 SG_ EHU_FCWFCTASwt : 11|2@0+ (1,0) [0|3] ""  ADAS,CR_FL,CR_FR,FR_FC
 SG_ EHU_AEBFCTBSwt : 13|2@0+ (1,0) [0|3] ""  ADAS,CR_FL,CR_FR,FR_FC
 SG_ EHU_ESSSwt : 15|2@0+ (1,0) [0|3] ""  ADAS
 SG_ EHU_LDWAlrmTypReq : 35|2@0+ (1,0) [0|3] ""  ADAS
 SG_ EHU_ADASSnvtySet : 37|2@0+ (1,0) [0|3] ""  ADAS,FVC
 SG_ EHU_HiwayExitAuxReq : 42|1@0+ (1,0) [0|1] ""  ADAS
 SG_ EHU_HiwayExitAuxSwt : 55|2@0+ (1,0) [0|3] ""  ADAS
 SG_ EHU_VoiceSpdRgln_ADAS : 63|8@0+ (1,20) [20|275] ""  ADAS

BO_ 1319 ICC_0x527: 8 MGW
 SG_ EHU_DrvrSts : 42|3@0+ (1,0) [0|7] ""  ADAS
 SG_ EHU_DrvrOccpy : 47|2@0+ (1,0) [0|3] ""  ADAS

BO_ 1328 ICC_0x530: 8 MGW
 SG_ EHU_NavCtryCod : 39|8@0+ (1,0) [0|255] ""  ADAS,FVC
 SG_ EHU_NavRoadTyp : 43|4@0+ (1,0) [0|15] ""  ADAS,FVC
 SG_ EHU_NavSpdLimUnit : 45|2@0+ (1,0) [0|3] ""  ADAS,FVC
 SG_ EHU_NavSpdLimSts : 47|2@0+ (1,0) [0|3] ""  ADAS,FVC
 SG_ EHU_NavSpdLim : 53|6@0+ (1,0) [0|63] ""  ADAS,FVC
 SG_ EHU_NavSpdLimExitDst : 63|8@0+ (10,0) [0|2550] "m"  ADAS

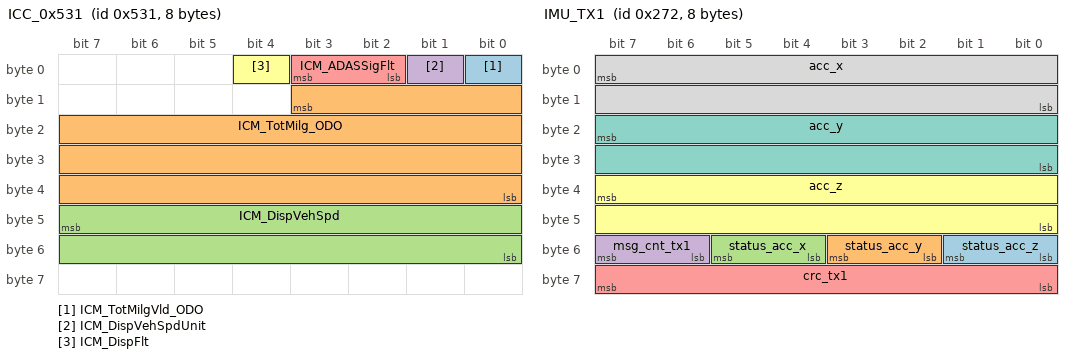
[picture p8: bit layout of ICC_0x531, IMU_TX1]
BO_ 1329 ICC_0x531: 8 MGW
 SG_ ICM_TotMilgVld_ODO : 0|1@0+ (1,0) [0|1] ""  ADAS,FVC,CR_RL,CR_RR,CR_FL,CR_FR,FR_FC
 SG_ ICM_TotMilg_ODO : 11|28@0+ (0.01,0) [0|2000000] "km"  ADAS,FVC,CR_RL,CR_RR,CR_FL,CR_FR,FR_FC
 SG_ ICM_DispVehSpd : 47|16@0+ (0.01,0) [0|655.35] "km/h"  ADAS,FVC,CR_RL,CR_RR,CR_FL,CR_FR
 SG_ ICM_DispVehSpdUnit : 1|1@0+ (1,0) [0|1] ""  ADAS,FVC,CR_RL,CR_RR,CR_FL,CR_FR
 SG_ ICM_ADASSigFlt : 3|2@0+ (1,0) [0|3] ""  ADAS,FVC,CR_RL,CR_RR,CR_FL,CR_FR,FR_FC
 SG_ ICM_DispFlt : 4|1@0+ (1,0) [0|1] ""  ADAS,FVC,CR_RL,CR_RR,CR_FL,CR_FR,FR_FC

BO_ 626 IMU_TX1: 8 IMU_MMP2
 SG_ status_acc_z : 49|2@0+ (1,0) [0|3] ""  ADAS
 SG_ status_acc_y : 51|2@0+ (1,0) [0|3] ""  ADAS
 SG_ status_acc_x : 53|2@0+ (1,0) [0|3] ""  ADAS
 SG_ msg_cnt_tx1 : 55|2@0+ (1,0) [0|3] ""  ADAS
 SG_ crc_tx1 : 63|8@0+ (1,0) [0|255] ""  ADAS
 SG_ acc_z : 39|16@0- (0.0002,0) [-6.5536|6.5536] "g"  ADAS
 SG_ acc_y : 23|16@0- (0.0002,0) [-6.5536|6.5536] "g"  ADAS
 SG_ acc_x : 7|16@0- (0.0002,0) [-6.5536|6.5534] "g"  ADAS

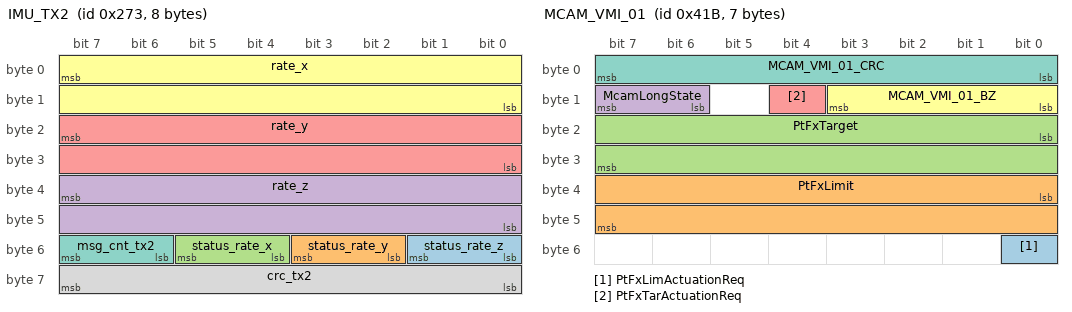
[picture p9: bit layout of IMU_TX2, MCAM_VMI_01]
BO_ 627 IMU_TX2: 8 IMU_MMP2
 SG_ status_rate_z : 49|2@0+ (1,0) [0|3] ""  ADAS
 SG_ status_rate_y : 51|2@0+ (1,0) [0|3] ""  ADAS
 SG_ status_rate_x : 53|2@0+ (1,0) [0|3] ""  ADAS
 SG_ rate_z : 39|16@0- (0.01,0) [-327.68|327.68] "°/s"  ADAS
 SG_ rate_y : 23|16@0- (0.01,0) [-327.68|327.68] "°/s"  ADAS
 SG_ rate_x : 7|16@0- (0.01,0) [-327.68|327.68] "°/s"  ADAS
 SG_ msg_cnt_tx2 : 55|2@0+ (1,0) [0|3] ""  ADAS
 SG_ crc_tx2 : 63|8@0+ (1,0) [0|255] ""  ADAS

BO_ 1051 MCAM_VMI_01: 7 ADAS
 SG_ PtFxLimActuationReq : 48|1@1+ (1,0) [0|1] ""  MGW
 SG_ PtFxLimit : 32|16@1+ (4,-125000) [-125000|125000] "N"  MGW
 SG_ PtFxTarget : 16|16@1+ (4,-125000) [-125000|125000] "N"  MGW
 SG_ McamLongState : 14|2@1+ (1,0) [0|3] "-"  MGW
 SG_ PtFxTarActuationReq : 12|1@1+ (1,0) [0|1] ""  MGW
 SG_ MCAM_VMI_01_BZ : 8|4@1+ (1,0) [0|15] ""  MGW
 SG_ MCAM_VMI_01_CRC : 0|8@1+ (1,0) [0|255] ""  MGW

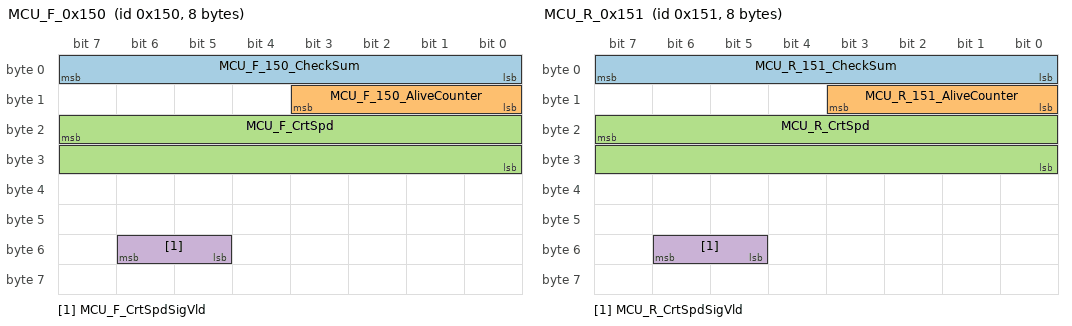
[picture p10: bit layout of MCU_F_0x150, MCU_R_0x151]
BO_ 336 MCU_F_0x150: 8 MGW
 SG_ MCU_F_150_CheckSum : 7|8@0+ (1,0) [0|255] ""  ADAS
 SG_ MCU_F_150_AliveCounter : 11|4@0+ (1,0) [0|15] ""  ADAS
 SG_ MCU_F_CrtSpd : 23|16@0+ (1,-32768) [-32768|32767] "rpm"  ADAS
 SG_ MCU_F_CrtSpdSigVld : 54|2@0+ (1,0) [0|3] ""  ADAS

BO_ 337 MCU_R_0x151: 8 MGW
 SG_ MCU_R_151_CheckSum : 7|8@0+ (1,0) [0|255] ""  ADAS
 SG_ MCU_R_151_AliveCounter : 11|4@0+ (1,0) [0|15] ""  ADAS
 SG_ MCU_R_CrtSpd : 23|16@0+ (1,-32768) [-32768|32767] "rpm"  ADAS
 SG_ MCU_R_CrtSpdSigVld : 54|2@0+ (1,0) [0|3] ""  ADAS

BO_ 1300 MFS_0x514: 8 MGW
 SG_ MFS_LeRollPress : 15|2@0+ (1,0) [0|3] ""  ADAS
 SG_ MFS_RiRollPress : 31|2@0+ (1,0) [0|3] ""  ADAS

BO_ 820 MPC_0x334: 8 MGW
 SG_ MPC_FrntCamBli : 23|2@0+ (1,0) [0|3] ""  ADAS
 SG_ MPC_FrntCamFlt : 31|2@0+ (1,0) [0|3] ""  ADAS

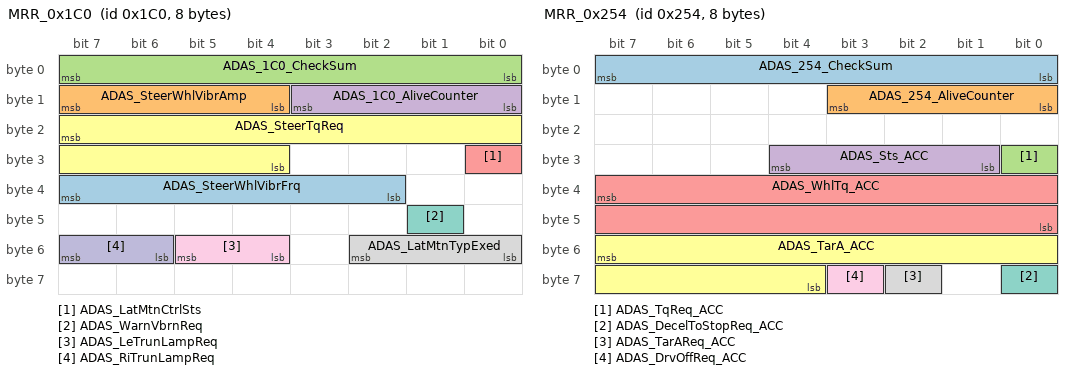
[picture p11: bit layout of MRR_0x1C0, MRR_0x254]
BO_ 448 MRR_0x1C0: 8 ADAS
 SG_ ADAS_SteerWhlVibrFrq : 39|6@0+ (0.5,0) [0|31.5] ""  MGW
 SG_ ADAS_SteerWhlVibrAmp : 15|4@0+ (0.2,0) [0|3] ""  MGW
 SG_ ADAS_1C0_CheckSum : 7|8@0+ (1,0) [0|255] ""  MGW
 SG_ ADAS_1C0_AliveCounter : 11|4@0+ (1,0) [0|14] ""  MGW
 SG_ ADAS_LatMtnCtrlSts : 24|1@0+ (1,0) [0|1] ""  MGW
 SG_ ADAS_SteerTqReq : 23|12@0+ (0.01,-8) [-8|8] "Nm"  MGW
 SG_ ADAS_WarnVbrnReq : 41|1@0+ (1,0) [0|1] ""  MGW
 SG_ ADAS_LatMtnTypExed : 50|3@0+ (1,0) [0|7] ""  MGW
 SG_ ADAS_LeTrunLampReq : 53|2@0+ (1,0) [0|3] ""  MGW
 SG_ ADAS_RiTrunLampReq : 55|2@0+ (1,0) [0|3] ""  MGW

BO_ 596 MRR_0x254: 8 ADAS
 SG_ ADAS_254_CheckSum : 7|8@0+ (1,0) [0|255] ""  MGW
 SG_ ADAS_254_AliveCounter : 11|4@0+ (1,0) [0|14] ""  MGW
 SG_ ADAS_TqReq_ACC : 24|1@0+ (1,0) [0|1] ""  MGW
 SG_ ADAS_Sts_ACC : 28|4@0+ (1,0) [0|15] ""  MGW
 SG_ ADAS_WhlTq_ACC : 39|16@0+ (1,-32768) [-32768|32767] "Nm"  MGW
 SG_ ADAS_TarA_ACC : 55|12@0+ (0.005,-7.22) [-7.22|3.015] "m/s2"  MGW
 SG_ ADAS_DecelToStopReq_ACC : 56|1@0+ (1,0) [0|1] ""  MGW
 SG_ ADAS_TarAReq_ACC : 58|1@0+ (1,0) [0|1] ""  MGW
 SG_ ADAS_DrvOffReq_ACC : 59|1@0+ (1,0) [0|1] ""  MGW

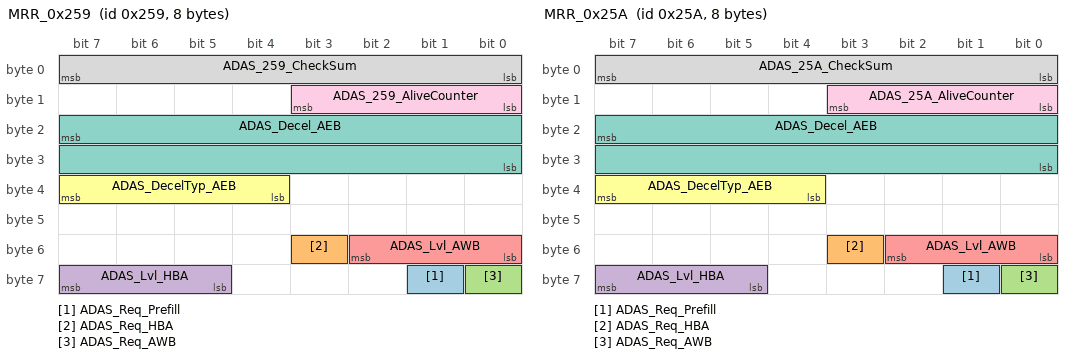
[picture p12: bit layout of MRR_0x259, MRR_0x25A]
BO_ 601 MRR_0x259: 8 ADAS
 SG_ ADAS_Req_Prefill : 57|1@0+ (1,0) [0|1] ""  MGW
 SG_ ADAS_Req_HBA : 51|1@0+ (1,0) [0|1] ""  MGW
 SG_ ADAS_Req_AWB : 56|1@0+ (1,0) [0|1] ""  MGW
 SG_ ADAS_Lvl_HBA : 63|3@0+ (1,0) [0|7] ""  MGW
 SG_ ADAS_Lvl_AWB : 50|3@0+ (1,0) [0|7] ""  MGW
 SG_ ADAS_DecelTyp_AEB : 39|4@0+ (1,0) [0|15] ""  MGW
 SG_ ADAS_Decel_AEB : 23|16@0+ (0.0004882,-16) [-16|15.994187] "m/s²"  MGW
 SG_ ADAS_259_CheckSum : 7|8@0+ (1,0) [0|255] ""  MGW
 SG_ ADAS_259_AliveCounter : 11|4@0+ (1,0) [0|15] ""  MGW

BO_ 602 MRR_0x25A: 8 ADAS
 SG_ ADAS_Req_Prefill : 57|1@0+ (1,0) [0|1] ""  GWS
 SG_ ADAS_Req_HBA : 51|1@0+ (1,0) [0|1] ""  GWS
 SG_ ADAS_Req_AWB : 56|1@0+ (1,0) [0|1] ""  GWS
 SG_ ADAS_Lvl_HBA : 63|3@0+ (1,0) [0|7] ""  GWS
 SG_ ADAS_Lvl_AWB : 50|3@0+ (1,0) [0|7] ""  GWS
 SG_ ADAS_DecelTyp_AEB : 39|4@0+ (1,0) [0|15] ""  GWS
 SG_ ADAS_Decel_AEB : 23|16@0+ (0.0004882,-16) [-16|15.994187] "m/s²"  GWS
 SG_ ADAS_25A_CheckSum : 7|8@0+ (1,0) [0|255] ""  GWS
 SG_ ADAS_25A_AliveCounter : 11|4@0+ (1,0) [0|15] ""  GWS

BO_ 603 MRR_0x25B: 2 ADAS
 SG_ ADAS_Fwd_Safety_Func : 7|16@0+ (1,0) [0|65535] ""  GWS

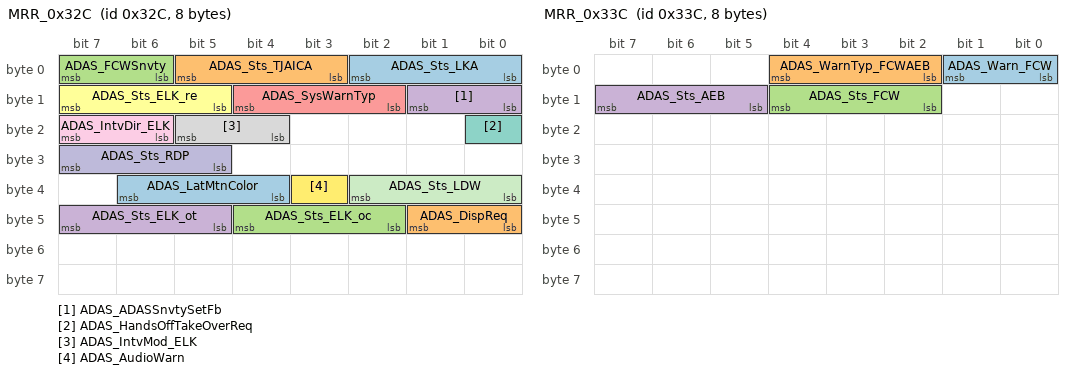
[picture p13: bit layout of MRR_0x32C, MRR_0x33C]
BO_ 812 MRR_0x32C: 8 ADAS
 SG_ ADAS_Sts_LKA : 2|3@0+ (1,0) [0|7] ""  MGW
 SG_ ADAS_Sts_TJAICA : 5|3@0+ (1,0) [0|7] ""  MGW
 SG_ ADAS_FCWSnvty : 7|2@0+ (1,0) [0|3] ""  MGW
 SG_ ADAS_ADASSnvtySetFb : 9|2@0+ (1,0) [0|3] ""  MGW
 SG_ ADAS_SysWarnTyp : 12|3@0+ (1,0) [0|7] ""  MGW
 SG_ ADAS_Sts_ELK_re : 15|3@0+ (1,0) [0|7] ""  MGW
 SG_ ADAS_HandsOffTakeOverReq : 16|1@0+ (1,0) [0|1] ""  MGW
 SG_ ADAS_IntvMod_ELK : 21|2@0+ (1,0) [0|3] ""  MGW
 SG_ ADAS_IntvDir_ELK : 23|2@0+ (1,0) [0|3] ""  MGW
 SG_ ADAS_Sts_RDP : 31|3@0+ (1,0) [0|7] ""  MGW
 SG_ ADAS_Sts_LDW : 34|3@0+ (1,0) [0|7] ""  MGW
 SG_ ADAS_AudioWarn : 35|1@0+ (1,0) [0|1] ""  MGW
 SG_ ADAS_LatMtnColor : 38|3@0+ (1,0) [0|7] ""  MGW
 SG_ ADAS_DispReq : 41|2@0+ (1,0) [0|3] ""  MGW
 SG_ ADAS_Sts_ELK_oc : 44|3@0+ (1,0) [0|7] ""  MGW
 SG_ ADAS_Sts_ELK_ot : 47|3@0+ (1,0) [0|7] ""  MGW

BO_ 828 MRR_0x33C: 8 ADAS
 SG_ ADAS_Warn_FCW : 1|2@0+ (1,0) [0|3] ""  MGW
 SG_ ADAS_WarnTyp_FCWAEB : 4|3@0+ (1,0) [0|7] ""  MGW
 SG_ ADAS_Sts_FCW : 12|3@0+ (1,0) [0|7] ""  MGW
 SG_ ADAS_Sts_AEB : 15|3@0+ (1,0) [0|7] ""  MGW

BO_ 830 MRR_0x33E: 8 FR_FC
 SG_ MRR_FrntSnsrFlt : 1|2@0+ (1,0) [0|3] ""  ADAS
 SG_ MRR_FrntSnsrBli : 3|2@0+ (1,0) [0|3] ""  ADAS

BO_ 832 MRR_0x340: 8 ADAS
 SG_ ADAS_LaneCrvt : 7|8@0+ (50,-3150) [-3150|3200] "m"  MGW
 SG_ ADAS_LeLineTyp : 9|2@0+ (1,0) [0|3] ""  MGW
 SG_ ADAS_RiLineTyp : 11|2@0+ (1,0) [0|3] ""  MGW
 SG_ ADAS_LeLineColor : 13|2@0+ (1,0) [0|3] ""  MGW
 SG_ ADAS_RiLineColor : 15|2@0+ (1,0) [0|3] ""  MGW
 SG_ ADAS_LeLineDst : 22|7@0+ (0.1,-6.2) [-6.2|6.2] "m"  MGW
 SG_ ADAS_RiLineDst : 30|7@0+ (0.1,-6.2) [-6.2|6.2] "m"  MGW
 SG_ ADAS_LeLineFlash : 33|2@0+ (1,0) [0|3] ""  MGW
 SG_ ADAS_RiLineFlash : 35|2@0+ (1,0) [0|3] ""  MGW
 SG_ ADAS_ESSSwtFb : 39|2@0+ (1,0) [0|3] ""  MGW
 SG_ ADAS_IntegtCrsSwtFb : 41|2@0+ (1,0) [0|3] ""  MGW
 SG_ ADAS_IntegtCrsModSetFb : 43|2@0+ (1,0) [0|3] ""  MGW
 SG_ ADAS_LaneSprtSwtFb : 45|2@0+ (1,0) [0|3] ""  MGW
 SG_ ADAS_LaneSprtTypSetFb : 47|2@0+ (1,0) [0|3] ""  MGW
 SG_ ADAS_FCWFCTASwtFb : 49|2@0+ (1,0) [0|3] ""  MGW
 SG_ ADAS_AEBFCTBSwtFb : 51|2@0+ (1,0) [0|3] ""  MGW
 SG_ ADAS_FltIndcr : 53|2@0+ (1,0) [0|3] ""  MGW
 SG_ ADAS_VoiceSpdRglnFb : 55|2@0+ (1,0) [0|3] ""  MGW
 SG_ ADAS_IntegtCrsFltTxt : 56|1@0+ (1,0) [0|1] ""  MGW
 SG_ ADAS_LaneSprtFltTxt : 57|1@0+ (1,0) [0|1] ""  MGW
 SG_ ADAS_FwdWarnFltTxt : 58|1@0+ (1,0) [0|1] ""  MGW
 SG_ ADAS_IntecnFltTxt : 59|1@0+ (1,0) [0|1] ""  MGW
 SG_ ADAS_ACCIconDisp : 62|3@0+ (1,0) [0|7] ""  MGW

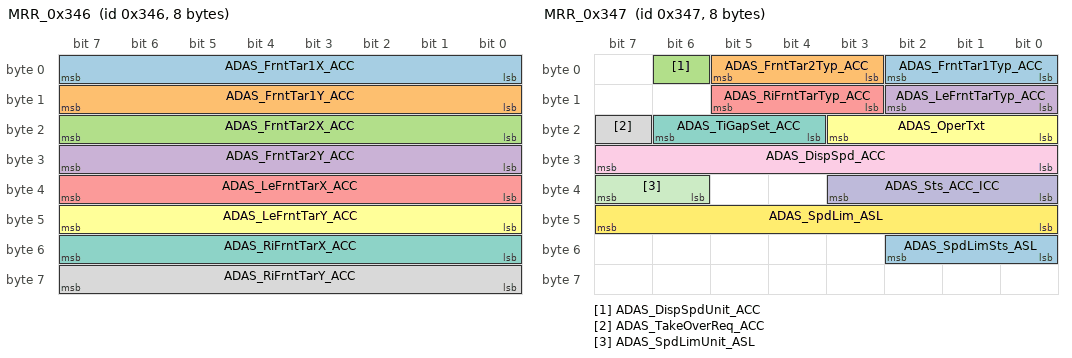
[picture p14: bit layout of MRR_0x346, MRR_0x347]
BO_ 838 MRR_0x346: 8 ADAS
 SG_ ADAS_FrntTar1X_ACC : 7|8@0+ (1,0) [0|255] ""  MGW
 SG_ ADAS_FrntTar1Y_ACC : 15|8@0+ (0.1,-12.7) [-12.7|12.8] ""  MGW
 SG_ ADAS_FrntTar2X_ACC : 23|8@0+ (1,0) [0|255] ""  MGW
 SG_ ADAS_FrntTar2Y_ACC : 31|8@0+ (0.1,-12.7) [-12.7|12.8] ""  MGW
 SG_ ADAS_LeFrntTarX_ACC : 39|8@0+ (1,0) [0|255] ""  MGW
 SG_ ADAS_LeFrntTarY_ACC : 47|8@0+ (0.1,-12.7) [-12.7|12.8] ""  MGW
 SG_ ADAS_RiFrntTarX_ACC : 55|8@0+ (1,0) [0|255] ""  MGW
 SG_ ADAS_RiFrntTarY_ACC : 63|8@0+ (0.1,-12.7) [-12.7|12.8] ""  MGW

BO_ 839 MRR_0x347: 8 ADAS
 SG_ ADAS_FrntTar1Typ_ACC : 2|3@0+ (1,0) [0|7] ""  MGW
 SG_ ADAS_FrntTar2Typ_ACC : 5|3@0+ (1,0) [0|7] ""  MGW
 SG_ ADAS_DispSpdUnit_ACC : 6|1@0+ (1,0) [0|1] ""  MGW
 SG_ ADAS_LeFrntTarTyp_ACC : 10|3@0+ (1,0) [0|7] ""  MGW
 SG_ ADAS_RiFrntTarTyp_ACC : 13|3@0+ (1,0) [0|7] ""  MGW
 SG_ ADAS_OperTxt : 19|4@0+ (1,0) [0|15] ""  MGW
 SG_ ADAS_TiGapSet_ACC : 22|3@0+ (1,0) [0|7] ""  MGW
 SG_ ADAS_TakeOverReq_ACC : 23|1@0+ (1,0) [0|1] ""  MGW
 SG_ ADAS_DispSpd_ACC : 31|8@0+ (1,0) [0|255] "km/h"  MGW
 SG_ ADAS_Sts_ACC_ICC : 35|4@0+ (1,0) [0|15] ""  MGW
 SG_ ADAS_SpdLimUnit_ASL : 39|2@0+ (1,0) [0|3] ""  MGW
 SG_ ADAS_SpdLim_ASL : 47|8@0+ (1,0) [0|255] ""  MGW
 SG_ ADAS_SpdLimSts_ASL : 50|3@0+ (1,0) [0|7] ""  MGW,FVC

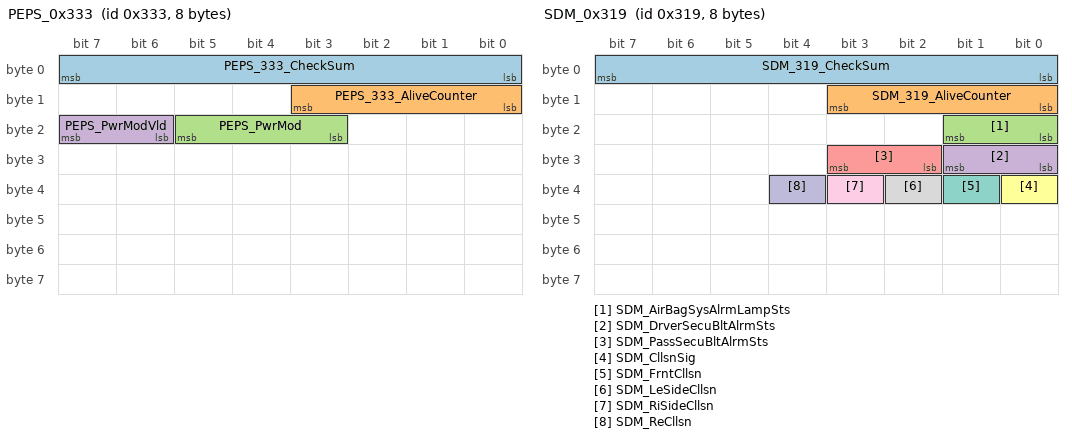
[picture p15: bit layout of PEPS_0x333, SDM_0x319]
BO_ 819 PEPS_0x333: 8 MGW
 SG_ PEPS_333_CheckSum : 7|8@0+ (1,0) [0|255] ""  ADAS,FVC,CR_RL,CR_RR,CR_FL,CR_FR,FR_FC
 SG_ PEPS_333_AliveCounter : 11|4@0+ (1,0) [0|15] ""  ADAS,FVC,CR_RL,CR_RR,CR_FL,CR_FR,FR_FC
 SG_ PEPS_PwrMod : 21|3@0+ (1,0) [0|7] ""  ADAS,FVC,CR_RL,CR_RR,CR_FL,CR_FR,FR_FC
 SG_ PEPS_PwrModVld : 23|2@0+ (1,0) [0|3] ""  ADAS,FVC,CR_RL,CR_RR,CR_FL,CR_FR,FR_FC

BO_ 1137 PLG_0x471: 8 MGW
 SG_ PLG_TrSwtStsIndcn : 36|3@0+ (1,0) [0|7] ""  ADAS

BO_ 1052 PT_VMI_01: 12 MGW
 SG_ DriverRqPtFxDominant : 12|1@1+ (1,0) [0|1] ""  ADAS
 SG_ PtFxRequested : 64|16@1+ (4,-125000) [-125000|125000] "N"  ADAS
 SG_ PtFxActual : 32|16@1+ (4,-125000) [-125000|125000] "N"  ADAS
 SG_ PtFxMax : 48|16@1+ (4,-125000) [-125000|125000] "N"  ADAS
 SG_ PtFxMin : 16|16@1+ (4,-125000) [-125000|125000] "N"  ADAS
 SG_ PT_VMI_01_BZ : 8|4@1+ (1,0) [0|15] ""  ADAS
 SG_ PT_VMI_01_CRC : 0|8@1+ (1,0) [0|255] ""  ADAS

BO_ 1764 RBFMain11: 8 MGW
 SG_ RBFMain11_isBrkFctReqPrkBrkDom : 57|1@1+ (1,0) [0|1] ""  ADAS
 SG_ RBFMain11_ParkBrakeSupportReq : 56|1@1+ (1,0) [0|1] ""  ADAS
 SG_ RBFMain11_ParkBrakeState : 53|3@1+ (1,0) [0|4] ""  ADAS
 SG_ RBFMain11_ParkBrakeAvl : 51|2@1+ (1,0) [0|2] ""  ADAS
 SG_ RBFMain11_ParkBrakeCapability : 49|2@1+ (1,0) [0|2] ""  ADAS
 SG_ RBFMain11_YawRateStabActivity : 48|1@1+ (1,0) [0|1] ""  ADAS
 SG_ RBFMain11_YawRateStabAvl : 46|2@1+ (1,0) [0|2] ""  ADAS
 SG_ RBFMain11_AccStabActivity : 45|1@1+ (1,0) [0|1] ""  ADAS
 SG_ RBFMain11_AccStabAvail : 43|2@1+ (1,0) [0|2] ""  ADAS
 SG_ RBFMain11_DecStabActivity : 41|2@1+ (1,0) [0|2] ""  ADAS
 SG_ RBFMain11_DecStabCpbltyForDrvr : 39|2@1+ (1,0) [0|3] ""  ADAS
 SG_ RBFMain11_DecStabAvlForDriver : 37|2@1+ (1,0) [0|2] ""  ADAS
 SG_ RBFMain11_DecStabCpblty : 35|2@1+ (1,0) [0|3] ""  ADAS
 SG_ RBFMain11_DecStabAvail : 33|2@1+ (1,0) [0|2] ""  ADAS
 SG_ RBFMain11_isBrkFctReqFxBrkDom : 32|1@1+ (1,0) [0|1] ""  ADAS
 SG_ RBFMain11_BrakeFxActual : 18|14@1+ (8,-125000) [-125000|0] ""  ADAS
 SG_ RBFMain11_BrakeFxAvailability : 16|2@1+ (1,0) [0|2] ""  ADAS
 SG_ RBFMain11_BrakeFxCapability : 14|2@1+ (1,0) [0|2] ""  ADAS
 SG_ RBFMain11_usedChannel : 12|2@1+ (1,0) [0|3] ""  ADAS
 SG_ RBFMain11_AliveCounter : 8|4@1+ (1,0) [0|15] ""  ADAS
 SG_ RBFMain11_Checksum : 0|8@1+ (1,0) [0|255] ""  ADAS

BO_ 1765 RBFMain12: 8 MGW
 SG_ RBFMain12_CurrentPumpRev : 51|9@1+ (20,0) [0|10000] ""  ADAS
 SG_ RBFMain12_BrkBckStgyVehStopAvl : 48|3@1+ (1,0) [0|4] ""  ADAS
 SG_ RBFMain12_BrkBckStratFxCtrlAvl : 45|3@1+ (1,0) [0|4] ""  ADAS
 SG_ RBFMain12_BrakeBckpStratState : 43|2@1+ (1,0) [0|2] ""  ADAS
 SG_ RBFMain12_BrkDiscTempStatusAvl : 41|2@1+ (1,0) [0|2] ""  ADAS
 SG_ RBFMain12_BrkDiscTempStatus : 39|2@1+ (1,0) [0|3] ""  ADAS
 SG_ RBFMain12_isDrvReqParkBrkDom : 38|1@1+ (1,0) [0|1] ""  ADAS
 SG_ RBFMain12_DriverReqParkBrake : 36|2@1+ (1,0) [0|2] ""  ADAS
 SG_ RBFMain12_DrvReqParkBrakeAvail : 34|2@1+ (1,0) [0|2] ""  ADAS
 SG_ RBFMain12_isDrvReqFxBrakeDom : 33|1@1+ (1,0) [0|1] ""  ADAS
 SG_ RBFMain12_DrvReqFxBrkDomAvail : 31|2@1+ (1,0) [0|2] ""  ADAS
 SG_ RBFMain12_isDrvPressBrkPedal : 30|1@1+ (1,0) [0|1] ""  ADAS
 SG_ RBFMain12_DrvPressBrkPedalAvl : 28|2@1+ (1,0) [0|2] ""  ADAS
 SG_ RBFMain12_DrvReqTarFxBrake : 14|14@1+ (8,-125000) [-125000|0] ""  ADAS
 SG_ RBFMain12_DrvReqTarFxBrakeAvl : 12|2@1+ (1,0) [0|2] ""  ADAS
 SG_ RBFMain12_AliveCounter : 8|4@1+ (1,0) [0|15] ""  ADAS
 SG_ RBFMain12_Checksum : 0|8@1+ (1,0) [0|255] ""  ADAS

BO_ 793 SDM_0x319: 8 MGW
 SG_ SDM_319_CheckSum : 7|8@0+ (1,0) [0|255] ""  ADAS,FR_FC
 SG_ SDM_319_AliveCounter : 11|4@0+ (1,0) [0|15] ""  ADAS,FR_FC
 SG_ SDM_AirBagSysAlrmLampSts : 17|2@0+ (1,0) [0|3] ""  ADAS
 SG_ SDM_DrverSecuBltAlrmSts : 25|2@0+ (1,0) [0|3] ""  ADAS,FR_FC
 SG_ SDM_PassSecuBltAlrmSts : 27|2@0+ (1,0) [0|3] ""  ADAS
 SG_ SDM_CllsnSig : 32|1@0+ (1,0) [0|1] ""  ADAS
 SG_ SDM_FrntCllsn : 33|1@0+ (1,0) [0|1] ""  ADAS
 SG_ SDM_LeSideCllsn : 34|1@0+ (1,0) [0|1] ""  ADAS
 SG_ SDM_RiSideCllsn : 35|1@0+ (1,0) [0|1] ""  ADAS
 SG_ SDM_ReCllsn : 36|1@0+ (1,0) [0|1] ""  ADAS

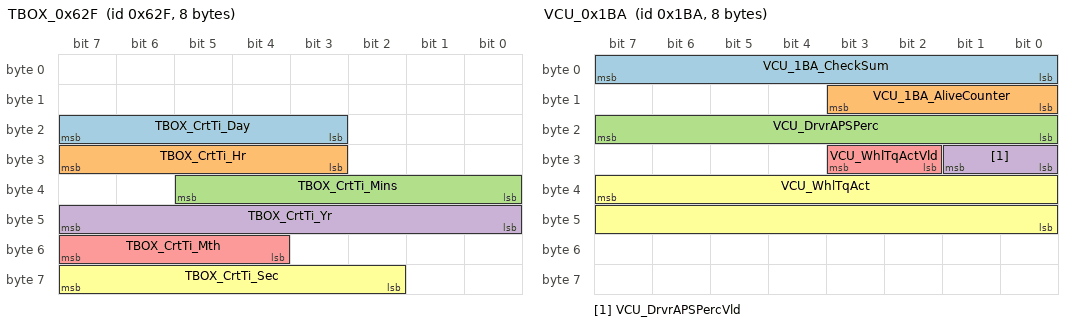
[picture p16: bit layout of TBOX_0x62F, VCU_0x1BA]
BO_ 1583 TBOX_0x62F: 8 MGW
 SG_ TBOX_CrtTi_Day : 23|5@0+ (1,1) [1|31] "day"  ADAS,FVC,CR_RL,CR_RR,CR_FL,CR_FR,FR_FC
 SG_ TBOX_CrtTi_Hr : 31|5@0+ (1,0) [0|23] "hour"  ADAS,FVC,CR_RL,CR_RR,CR_FL,CR_FR,FR_FC
 SG_ TBOX_CrtTi_Mins : 37|6@0+ (1,0) [0|59] "mintue"  ADAS,FVC,CR_RL,CR_RR,CR_FL,CR_FR,FR_FC
 SG_ TBOX_CrtTi_Yr : 47|8@0+ (1,2015) [2015|2270] "year"  ADAS,FVC,CR_RL,CR_RR,CR_FL,CR_FR,FR_FC
 SG_ TBOX_CrtTi_Mth : 55|4@0+ (1,1) [1|12] "month"  ADAS,FVC,CR_RL,CR_RR,CR_FL,CR_FR,FR_FC
 SG_ TBOX_CrtTi_Sec : 63|6@0+ (1,0) [0|59] "second"  ADAS,FVC,CR_RL,CR_RR,CR_FL,CR_FR,FR_FC

BO_ 1417 TPMS_0x589: 8 MGW
 SG_ TPMS_TirePosn : 2|3@0+ (1,0) [0|7] ""  ADAS
 SG_ TPMS_SngTirePSts : 11|2@0+ (1,0) [0|3] ""  ADAS

BO_ 442 VCU_0x1BA: 8 MGW
 SG_ VCU_1BA_CheckSum : 7|8@0+ (1,0) [0|255] ""  ADAS,CR_RL,CR_RR,CR_FL,CR_FR,FR_FC
 SG_ VCU_1BA_AliveCounter : 11|4@0+ (1,0) [0|15] ""  ADAS,CR_RL,CR_RR,CR_FL,CR_FR,FR_FC
 SG_ VCU_DrvrAPSPerc : 23|8@0+ (0.4,0) [0|100] "%"  ADAS,CR_RL,CR_RR,CR_FL,CR_FR,FR_FC
 SG_ VCU_DrvrAPSPercVld : 25|2@0+ (1,0) [0|3] ""  ADAS,CR_RL,CR_RR,CR_FL,CR_FR,FR_FC
 SG_ VCU_WhlTqActVld : 27|2@0+ (1,0) [0|3] ""  ADAS
 SG_ VCU_WhlTqAct : 39|16@0+ (1,-32768) [-32768|32767] "Nm"  ADAS

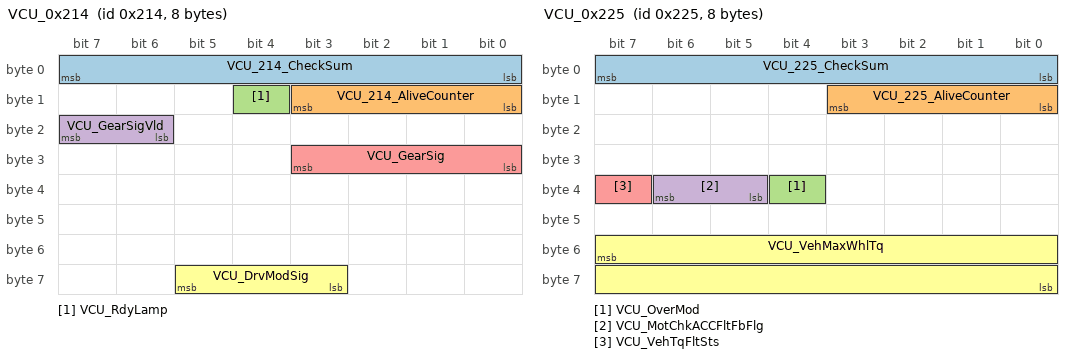
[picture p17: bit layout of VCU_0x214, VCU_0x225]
BO_ 532 VCU_0x214: 8 MGW
 SG_ VCU_214_CheckSum : 7|8@0+ (1,0) [0|255] ""  ADAS,CR_RL,CR_RR,CR_FL,CR_FR,FR_FC
 SG_ VCU_214_AliveCounter : 11|4@0+ (1,0) [0|15] ""  ADAS,CR_RL,CR_RR,CR_FL,CR_FR,FR_FC
 SG_ VCU_RdyLamp : 12|1@0+ (1,0) [0|1] ""  ADAS,CR_RL,CR_RR,CR_FL,CR_FR,FR_FC
 SG_ VCU_GearSigVld : 23|2@0+ (1,0) [0|3] ""  ADAS,CR_RL,CR_RR,CR_FL,CR_FR,FR_FC
 SG_ VCU_GearSig : 27|4@0+ (1,0) [0|15] ""  ADAS,CR_RL,CR_RR,CR_FL,CR_FR,FR_FC
 SG_ VCU_DrvModSig : 61|3@0+ (1,0) [0|7] ""  ADAS

BO_ 549 VCU_0x225: 8 MGW
 SG_ VCU_225_CheckSum : 7|8@0+ (1,0) [0|255] ""  ADAS,FR_FC
 SG_ VCU_225_AliveCounter : 11|4@0+ (1,0) [0|15] ""  ADAS,FR_FC
 SG_ VCU_OverMod : 36|1@0+ (1,0) [0|1] ""  ADAS,FR_FC
 SG_ VCU_MotChkACCFltFbFlg : 38|2@0+ (1,0) [0|3] ""  ADAS
 SG_ VCU_VehTqFltSts : 39|1@0+ (1,0) [0|1] ""  ADAS
 SG_ VCU_VehMaxWhlTq : 55|16@0+ (1,-32768) [-32768|32767] "Nm"  ADAS

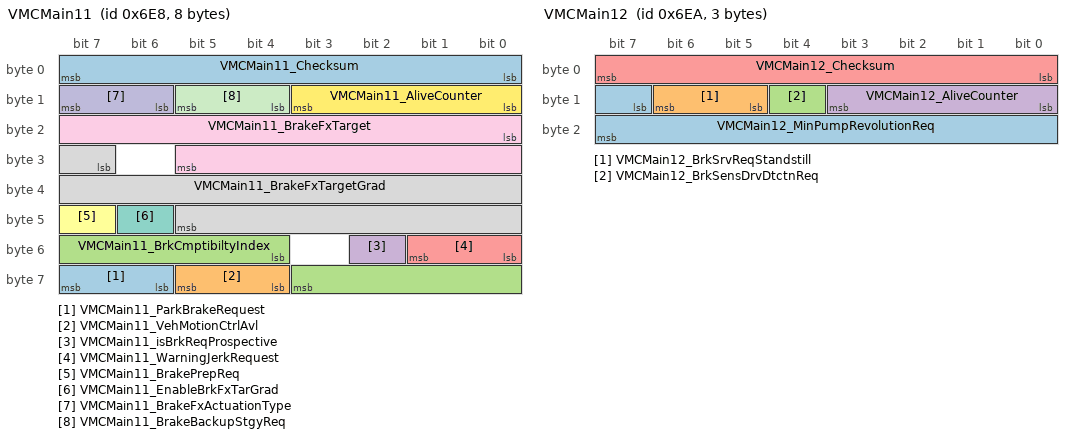
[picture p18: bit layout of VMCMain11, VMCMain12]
BO_ 1768 VMCMain11: 8 ADAS
 SG_ VMCMain11_ParkBrakeRequest : 62|2@1+ (1,0) [0|2] ""  MGW
 SG_ VMCMain11_VehMotionCtrlAvl : 60|2@1+ (1,0) [0|2] ""  MGW
 SG_ VMCMain11_BrkCmptibiltyIndex : 52|8@1+ (1,0) [0|255] ""  MGW
 SG_ VMCMain11_isBrkReqProspective : 50|1@1+ (1,0) [0|1] ""  MGW
 SG_ VMCMain11_WarningJerkRequest : 48|2@1+ (1,0) [0|3] ""  MGW
 SG_ VMCMain11_BrakePrepReq : 47|1@1+ (1,0) [0|1] ""  MGW
 SG_ VMCMain11_EnableBrkFxTarGrad : 46|1@1+ (1,0) [0|1] ""  MGW
 SG_ VMCMain11_BrakeFxTargetGrad : 31|15@1+ (12.5,-204800) [-204800|204787.5] ""  MGW
 SG_ VMCMain11_BrakeFxTarget : 16|14@1+ (8,-125000) [-125000|0] ""  MGW
 SG_ VMCMain11_BrakeFxActuationType : 14|2@1+ (1,0) [0|3] ""  MGW
 SG_ VMCMain11_BrakeBackupStgyReq : 12|2@1+ (1,0) [0|2] ""  MGW
 SG_ VMCMain11_AliveCounter : 8|4@1+ (1,0) [0|15] ""  MGW
 SG_ VMCMain11_Checksum : 0|8@1+ (1,0) [0|255] ""  MGW

BO_ 1770 VMCMain12: 3 ADAS
 SG_ VMCMain12_MinPumpRevolutionReq : 15|9@1+ (20,0) [0|10000] ""  MGW
 SG_ VMCMain12_BrkSrvReqStandstill : 13|2@1+ (1,0) [0|3] ""  MGW
 SG_ VMCMain12_BrkSensDrvDtctnReq : 12|1@1+ (1,0) [0|1] ""  MGW
 SG_ VMCMain12_AliveCounter : 8|4@1+ (1,0) [0|15] ""  MGW
 SG_ VMCMain12_Checksum : 0|8@1+ (1,0) [0|255] ""  MGW

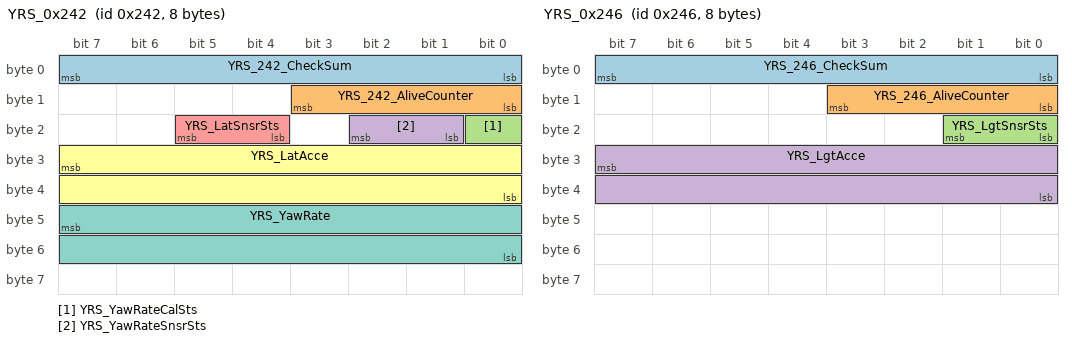
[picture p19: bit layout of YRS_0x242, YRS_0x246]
BO_ 578 YRS_0x242: 8 MGW
 SG_ YRS_242_CheckSum : 7|8@0+ (1,0) [0|255] ""  ADAS,FVC,CR_RL,CR_RR,CR_FL,CR_FR,FR_FC
 SG_ YRS_242_AliveCounter : 11|4@0+ (1,0) [0|15] ""  ADAS,FVC,CR_RL,CR_RR,CR_FL,CR_FR,FR_FC
 SG_ YRS_YawRateCalSts : 16|1@0+ (1,0) [0|1] ""  ADAS,CR_RL,CR_RR,CR_FL,CR_FR,FR_FC
 SG_ YRS_YawRateSnsrSts : 18|2@0+ (1,0) [0|3] ""  ADAS,FVC,CR_RL,CR_RR,CR_FL,CR_FR,FR_FC
 SG_ YRS_LatSnsrSts : 21|2@0+ (1,0) [0|3] ""  ADAS,FVC,CR_RL,CR_RR,CR_FL,CR_FR,FR_FC
 SG_ YRS_LatAcce : 31|16@0+ (0.001,-2) [-2|2] "g"  ADAS,FVC,CR_RL,CR_RR,CR_FL,CR_FR,FR_FC
 SG_ YRS_YawRate : 47|16@0+ (0.01,-180) [-180|180] "°/s"  ADAS,FVC,CR_RL,CR_RR,CR_FL,CR_FR,FR_FC

BO_ 582 YRS_0x246: 8 MGW
 SG_ YRS_246_CheckSum : 7|8@0+ (1,0) [0|255] ""  ADAS,FVC,CR_RL,CR_RR,CR_FL,CR_FR,FR_FC
 SG_ YRS_246_AliveCounter : 11|4@0+ (1,0) [0|15] ""  ADAS,FVC,CR_RL,CR_RR,CR_FL,CR_FR,FR_FC
 SG_ YRS_LgtSnsrSts : 17|2@0+ (1,0) [0|3] ""  ADAS,FVC,CR_RL,CR_RR,CR_FL,CR_FR,FR_FC
 SG_ YRS_LgtAcce : 31|16@0+ (0.001,-2) [-2|2] "g"  ADAS,FVC,CR_RL,CR_RR,CR_FL,CR_FR,FR_FC

CM_ SG_ 453 ADAS_1C5_CheckSum "CheckSum ADAS_1C1 - DataID 0";
CM_ SG_ 453 ADAS_1C5_AliveCounter "AliveCounter ADAS_1C5 - AUTOSAR E2E Profile 1";
CM_ SG_ 453 EPS_ActRoadWheelAngValue "Actual Road Wheel Angle";
CM_ SG_ 453 EPS_ActRPCTrq "Actual RPC torque request (TBT level)";
CM_ SG_ 453 EPS_LatDrvLvl12SrvAvl "Lateral level 12 driving service availability";
CM_ SG_ 453 EPS_IntRPCMaxTrq "Maximum internally allowed RPC torque for Level 2 (safety limit)(TBT level)";
CM_ SG_ 453 EPS_IntRPCMinTrq "Minimum internally allowed RPC torque for Level 2 (safety limit)(TBT level)";
CM_ SG_ 453 EPS_LatMCHptcWrnSrvAvl "Describes the availability of the Haptic Warning Service, availability to respond to a haptic request";
CM_ SG_ 453 EPS_ActRoadWheelAngState "State of signal ActRoadWheelAngleValue";
CM_ SG_ 453 EPS_LatMCRoadWheelAngActive "Lateral Motion Control feedback signal for the Road Wheel Angle service activation";
CM_ SG_ 288 ESP_120_CheckSum "ESP_120_CheckSum";
CM_ SG_ 288 ESP_120_AliveCounter "ESP_120_AliveCounter";
CM_ SG_ 288 ESP_ActvSig_ABS "ABS operating, When ABS is active shall the system send out a bus signal.";
CM_ SG_ 288 ESP_MstCylP "Ö÷¸×Ñ¹Á¦(Real value = raw value - offset)
Current pressure of the master cylinder pressure sensor in the ESP. Raw value without offset compensation.";
CM_ SG_ 288 ESP_MstCylPVld "Information about signal quality of pMC1.";
CM_ SG_ 288 ESP_MstCylPOffs "Master cylinder pressure offset.(Real value = raw value ¨C offset)";
CM_ SG_ 288 ESP_MstCylPOffsVld "Valid Information of the signal.";
CM_ SG_ 290 ESP_122_CheckSum "ESP_122_CheckSum";
CM_ SG_ 290 ESP_122_AliveCounter "ESP_122_AliveCounter";
CM_ SG_ 290 ESP_VmcVseLgtPrimSrvAvlCpby "(VmcVseAxOvrGrnd, VmcVsevVeh, VmcVseSlope, VmcVseStandstill)";
CM_ SG_ 609 ESP_261_CheckSum "(0x72) ESP_261_CheckSum";
CM_ SG_ 609 ESP_261_AliveCounter "ESP_261_AliveCounter";
CM_ SG_ 609 ESP_ActvSig "VDC operating, When ESP is active shall the system send out a bus signal. Not used for ABS.";
CM_ SG_ 609 ESP_ActvSig_TCS "TCS operating(including DTC operating). When TCS is active shall the system send out a bus signal. Not used for ABS.";
CM_ SG_ 609 ESP_ActvSig_EBD "indicating EBD in active control or not.";
CM_ SG_ 609 ESP_ActvSig_DTC "indicate DTC in active control or not.";
CM_ SG_ 609 ESP_Actvndcn_CDD "indicating CDD is working or not.";
CM_ SG_ 609 ESP_FltIndcn_CDD "indicating CDD is available or not.";
CM_ SG_ 609 ESP_ActvIndcn_ABA "ABA is active.";
CM_ SG_ 609 ESP_FltIndcn_ABA "the ABA function is available.";
CM_ SG_ 609 ESP_ActvIndcn_ABP "Prefill (ABP) is active.";
CM_ SG_ 609 ESP_FltIndcn_ABP "Prefill (ABP) is available.";
CM_ SG_ 609 ESP_ActvIndcn_AEB "ESP is excuting AEB  braking function.";
CM_ SG_ 609 ESP_FltIndcn_AEB "AEB is available.";
CM_ SG_ 609 ESP_ActvIndcn_AWB "AWB is active(brake jerk).";
CM_ SG_ 609 ESP_FltIndcn_AWB "AWB is available. Feedback of AWB activation for ACC.";
CM_ SG_ 609 ESP_VehStandstillIndcn "indicating whether the vehicle is standstill or not; must not be set until standstill is surely reached.";
CM_ SG_ 609 ESP_BrkOverTIndcn "indicating brake temperature too high or not.";
CM_ SG_ 616 ESP_268_CheckSum "ESP_268_CheckSum";
CM_ SG_ 616 ESP_268_AliveCounter "ESP_268_AliveCounter";
CM_ SG_ 616 ESP_SysSts_EPB "Status of EPB system.";
CM_ SG_ 616 ESP_FltIndcn_EPB "indicating EPB is available or not.";
CM_ SG_ 616 ESP_EPBSwtichPosition "EPB";
CM_ SG_ 773 ESP_305_CheckSum "(0x8A) ESP_305_CheckSum";
CM_ SG_ 773 ESP_305_AliveCounter "ESP_305_AliveCounter";
CM_ SG_ 773 ESP_WhlSpdVld_RF "Validty of signal 'WHEEL_SPEED_FRONT_RIGHT_ACC '";
CM_ SG_ 773 ESP_WhlSpd_RF "Wheel speed of the front right wheel.";
CM_ SG_ 773 ESP_WhlMovgDir_RF "Front Right wheel Moving direction.";
CM_ SG_ 773 ESP_WhlMovgDir_LF "Front left wheel Moving direction.";
CM_ SG_ 773 ESP_WhlSpdVld_LF "Validty of signal 'WHEEL_SPEED_FRONT_LEFT_ACC'";
CM_ SG_ 773 ESP_WhlSpd_LF "Wheel speed of the front left wheel.";
CM_ SG_ 774 ESP_306_CheckSum "(0x9F)ESP_306_CheckSum";
CM_ SG_ 774 ESP_306_AliveCounter "ESP_306_AliveCounter";
CM_ SG_ 774 ESP_WhlSpdVld_RR "Validty of signal 'WHEEL_SPEED_REAR_RIGHT_ACC'.";
CM_ SG_ 774 ESP_WhlSpd_RR "Wheel speed of the rear right wheel.";
CM_ SG_ 774 ESP_WhlMovgDir_RR "Rear Right wheel Moving direction.";
CM_ SG_ 774 ESP_WhlMovgDir_RL "Rear left wheel Moving direction.";
CM_ SG_ 774 ESP_WhlSpdVld_RL "Validty of signal 'WHEEL_SPEED_REAR_LEFT_ACC'.";
CM_ SG_ 774 ESP_WhlSpd_RL "Wheel speed of the rear left wheel.";
CM_ SG_ 778 ESP_30A_CheckSum "ESP_30A_CheckSum";
CM_ SG_ 778 ESP_30A_AliveCounter "ESP_30A_AliveCounter";
CM_ SG_ 778 ESP_LgtOffs "It is used with Longitudinal acceleration raw data (Real value = raw value ¨C offset).";
CM_ SG_ 778 ESP_LatOffs "It is used with Lateral acceleration raw data (Real value = raw value ¨C offset).";
CM_ SG_ 778 ESP_YAWVOffs "It is used with YAW veloctity raw data (Real value = raw value ¨C offset).";
CM_ SG_ 792 ESP_SwtOff_TCS "Indicates when the Traction and Yaw Control functions (DSC/TCS)  have been inhibited via the on/off switch by the driver. It is NOT set by a system malfunction.";
CM_ SG_ 792 ESP_318_CheckSum "ESP_318_CheckSum";
CM_ SG_ 792 ESP_318_AliveCounter "ESP_318_AliveCounter";
CM_ SG_ 792 ESP_VehSpdVld "When the diagnostic have set the failure code on this signal the value wil be 2.";
CM_ SG_ 792 ESP_LampSwtOffIndcn "Signal indicates to light up 'TCS/ESP off' lamp.
-manual switch off of ESP function (on/off switch).
Not used for ABS.";
CM_ SG_ 792 ESP_FltIndcn_ABS "Signal indicates to light up ABS lamp.";
CM_ SG_ 792 ESP_FltIndcn_TCS "Signal indicates failure monitoring of ESP function. Not used for ABS";
CM_ SG_ 792 ESP_CtrlSts_HDC "HDC control(Off/On, not active braking/On, active braking).";
CM_ SG_ 792 ESP_NoBrkP "no brake pressure applied; generally it regards wheel cylinder presure.";
CM_ SG_ 818 ESP_332_CheckSum "ESP_332_CheckSum";
CM_ SG_ 818 ESP_332_AliveCounter "ESP_332_AliveCounter";
CM_ SG_ 818 ESP_BrkLiReq "requires to illuminate brake light.";
CM_ SG_ 716 HODTchZone1Val_h8HSC8 "Hod Touch Zone 1 Value";
CM_ SG_ 1554 HandoverIndication "Signal used to request driving handover to the vehicle";
CM_ SG_ 1218 centerline_1_CRC "CRC - Autosar E2E Profile 5";
CM_ SG_ 1218 centerline_1_AliveCtr "Alive counter - Autosar E2E Profile 5";
CM_ SG_ 1218 CenterPoint_dx_00 "Longitudinal distance to the center line point. Invalid if CenterPoint_dx_XX = 0.0 AND CenterPoint_dy_XX = -102.4";
CM_ SG_ 1218 CenterPoint_dy_00 "Lateral distance to the center line point. Invalid if CenterPoint_dx_XX = 0.0 AND CenterPoint_dy_XX = -102.4";
CM_ SG_ 1218 CenterPoint_dx_01 "Longitudinal distance to the center line point. Invalid if CenterPoint_dx_XX = 0.0 AND CenterPoint_dy_XX = -102.4";
CM_ SG_ 1218 CenterPoint_dy_01 "Lateral distance to the center line point. Invalid if CenterPoint_dx_XX = 0.0 AND CenterPoint_dy_XX = -102.4";
CM_ SG_ 1218 CenterPoint_dx_02 "Longitudinal distance to the center line point. Invalid if CenterPoint_dx_XX = 0.0 AND CenterPoint_dy_XX = -102.4";
CM_ SG_ 1218 CenterPoint_dy_02 "Lateral distance to the center line point. Invalid if CenterPoint_dx_XX = 0.0 AND CenterPoint_dy_XX = -102.4";
CM_ SG_ 1218 CenterPoint_dx_03 "Longitudinal distance to the center line point. Invalid if CenterPoint_dx_XX = 0.0 AND CenterPoint_dy_XX = -102.4";
CM_ SG_ 1218 CenterPoint_dy_03 "Lateral distance to the center line point. Invalid if CenterPoint_dx_XX = 0.0 AND CenterPoint_dy_XX = -102.4";
CM_ SG_ 1218 CenterPoint_dx_04 "Longitudinal distance to the center line point. Invalid if CenterPoint_dx_XX = 0.0 AND CenterPoint_dy_XX = -102.4";
CM_ SG_ 1218 CenterPoint_dy_04 "Lateral distance to the center line point. Invalid if CenterPoint_dx_XX = 0.0 AND CenterPoint_dy_XX = -102.4";
CM_ SG_ 1218 CenterPoint_dx_05 "Longitudinal distance to the center line point. Invalid if CenterPoint_dx_XX = 0.0 AND CenterPoint_dy_XX = -102.4";
CM_ SG_ 1218 CenterPoint_dy_05 "Lateral distance to the center line point. Invalid if CenterPoint_dx_XX = 0.0 AND CenterPoint_dy_XX = -102.4";
CM_ SG_ 1218 CenterPoint_dx_06 "Longitudinal distance to the center line point. Invalid if CenterPoint_dx_XX = 0.0 AND CenterPoint_dy_XX = -102.4";
CM_ SG_ 1218 CenterPoint_dy_06 "Lateral distance to the center line point. Invalid if CenterPoint_dx_XX = 0.0 AND CenterPoint_dy_XX = -102.4";
CM_ SG_ 1218 CenterPoint_dx_07 "Longitudinal distance to the center line point. Invalid if CenterPoint_dx_XX = 0.0 AND CenterPoint_dy_XX = -102.4";
CM_ SG_ 1218 CenterPoint_dy_07 "Lateral distance to the center line point. Invalid if CenterPoint_dx_XX = 0.0 AND CenterPoint_dy_XX = -102.4";
CM_ SG_ 1218 CenterPoint_dx_08 "Longitudinal distance to the center line point. Invalid if CenterPoint_dx_XX = 0.0 AND CenterPoint_dy_XX = -102.4";
CM_ SG_ 1218 CenterPoint_dy_08 "Lateral distance to the center line point. Invalid if CenterPoint_dx_XX = 0.0 AND CenterPoint_dy_XX = -102.4";
CM_ SG_ 1218 CenterPoint_dx_09 "Longitudinal distance to the center line point. Invalid if CenterPoint_dx_XX = 0.0 AND CenterPoint_dy_XX = -102.4";
CM_ SG_ 1218 CenterPoint_dy_09 "Lateral distance to the center line point. Invalid if CenterPoint_dx_XX = 0.0 AND CenterPoint_dy_XX = -102.4";
CM_ SG_ 1218 CenterPoint_dx_10 "Longitudinal distance to the center line point. Invalid if CenterPoint_dx_XX = 0.0 AND CenterPoint_dy_XX = -102.4";
CM_ SG_ 1218 CenterPoint_dy_10 "Lateral distance to the center line point. Invalid if CenterPoint_dx_XX = 0.0 AND CenterPoint_dy_XX = -102.4";
CM_ SG_ 1218 CenterPoint_dx_11 "Longitudinal distance to the center line point. Invalid if CenterPoint_dx_XX = 0.0 AND CenterPoint_dy_XX = -102.4";
CM_ SG_ 1218 CenterPoint_dy_11 "Lateral distance to the center line point. Invalid if CenterPoint_dx_XX = 0.0 AND CenterPoint_dy_XX = -102.4";
CM_ SG_ 1218 CenterPoint_dx_12 "Longitudinal distance to the center line point. Invalid if CenterPoint_dx_XX = 0.0 AND CenterPoint_dy_XX = -102.4";
CM_ SG_ 1218 CenterPoint_dy_12 "Lateral distance to the center line point. Invalid if CenterPoint_dx_XX = 0.0 AND CenterPoint_dy_XX = -102.4";
CM_ SG_ 1218 CenterPoint_dx_13 "Longitudinal distance to the center line point. Invalid if CenterPoint_dx_XX = 0.0 AND CenterPoint_dy_XX = -102.4";
CM_ SG_ 1218 CenterPoint_dy_13 "Lateral distance to the center line point. Invalid if CenterPoint_dx_XX = 0.0 AND CenterPoint_dy_XX = -102.4";
CM_ SG_ 1218 CenterPoint_dx_14 "Longitudinal distance to the center line point. Invalid if CenterPoint_dx_XX = 0.0 AND CenterPoint_dy_XX = -102.4";
CM_ SG_ 1218 CenterPoint_dy_14 "Lateral distance to the center line point. Invalid if CenterPoint_dx_XX = 0.0 AND CenterPoint_dy_XX = -102.4";
CM_ SG_ 1218 CenterPoint_dx_15 "Longitudinal distance to the center line point. Invalid if CenterPoint_dx_XX = 0.0 AND CenterPoint_dy_XX = -102.4";
CM_ SG_ 1218 CenterPoint_dy_15 "Lateral distance to the center line point. Invalid if CenterPoint_dx_XX = 0.0 AND CenterPoint_dy_XX = -102.4";
CM_ SG_ 1218 CenterPoint_dx_16 "Longitudinal distance to the center line point. Invalid if CenterPoint_dx_XX = 0.0 AND CenterPoint_dy_XX = -102.4";
CM_ SG_ 1218 CenterPoint_dy_16 "Lateral distance to the center line point. Invalid if CenterPoint_dx_XX = 0.0 AND CenterPoint_dy_XX = -102.4";
CM_ SG_ 1218 CenterPoint_dx_17 "Longitudinal distance to the center line point. Invalid if CenterPoint_dx_XX = 0.0 AND CenterPoint_dy_XX = -102.4";
CM_ SG_ 1218 CenterPoint_dy_17 "Lateral distance to the center line point. Invalid if CenterPoint_dx_XX = 0.0 AND CenterPoint_dy_XX = -102.4";
CM_ SG_ 1218 CenterPoint_dx_18 "Longitudinal distance to the center line point. Invalid if CenterPoint_dx_XX = 0.0 AND CenterPoint_dy_XX = -102.4";
CM_ SG_ 1218 CenterPoint_dy_18 "Lateral distance to the center line point. Invalid if CenterPoint_dx_XX = 0.0 AND CenterPoint_dy_XX = -102.4";
CM_ SG_ 1218 CenterPoint_dx_19 "Longitudinal distance to the center line point. Invalid if CenterPoint_dx_XX = 0.0 AND CenterPoint_dy_XX = -102.4";
CM_ SG_ 1218 CenterPoint_dy_19 "Lateral distance to the center line point. Invalid if CenterPoint_dx_XX = 0.0 AND CenterPoint_dy_XX = -102.4";
CM_ SG_ 1219 CenterPoint_dx_20 "Longitudinal distance to the center line point. Invalid if CenterPoint_dx_XX = 0.0 AND CenterPoint_dy_XX = -102.4";
CM_ SG_ 1219 CenterPoint_dy_20 "Lateral distance to the center line point. Invalid if CenterPoint_dx_XX = 0.0 AND CenterPoint_dy_XX = -102.4";
CM_ SG_ 1219 CenterPoint_dx_21 "Longitudinal distance to the center line point. Invalid if CenterPoint_dx_XX = 0.0 AND CenterPoint_dy_XX = -102.4";
CM_ SG_ 1219 CenterPoint_dy_21 "Lateral distance to the center line point. Invalid if CenterPoint_dx_XX = 0.0 AND CenterPoint_dy_XX = -102.4";
CM_ SG_ 1219 CenterPoint_dx_22 "Longitudinal distance to the center line point. Invalid if CenterPoint_dx_XX = 0.0 AND CenterPoint_dy_XX = -102.4";
CM_ SG_ 1219 CenterPoint_dy_22 "Lateral distance to the center line point. Invalid if CenterPoint_dx_XX = 0.0 AND CenterPoint_dy_XX = -102.4";
CM_ SG_ 1219 CenterPoint_dx_23 "Longitudinal distance to the center line point. Invalid if CenterPoint_dx_XX = 0.0 AND CenterPoint_dy_XX = -102.4";
CM_ SG_ 1219 CenterPoint_dy_23 "Lateral distance to the center line point. Invalid if CenterPoint_dx_XX = 0.0 AND CenterPoint_dy_XX = -102.4";
CM_ SG_ 1219 CenterPoint_dx_24 "Longitudinal distance to the center line point. Invalid if CenterPoint_dx_XX = 0.0 AND CenterPoint_dy_XX = -102.4";
CM_ SG_ 1219 CenterPoint_dy_24 "Lateral distance to the center line point. Invalid if CenterPoint_dx_XX = 0.0 AND CenterPoint_dy_XX = -102.4";
CM_ SG_ 1219 CenterPoint_dx_25 "Longitudinal distance to the center line point. Invalid if CenterPoint_dx_XX = 0.0 AND CenterPoint_dy_XX = -102.4";
CM_ SG_ 1219 CenterPoint_dy_25 "Lateral distance to the center line point. Invalid if CenterPoint_dx_XX = 0.0 AND CenterPoint_dy_XX = -102.4";
CM_ SG_ 1219 CenterPoint_dx_26 "Longitudinal distance to the center line point. Invalid if CenterPoint_dx_XX = 0.0 AND CenterPoint_dy_XX = -102.4";
CM_ SG_ 1219 CenterPoint_dy_26 "Lateral distance to the center line point. Invalid if CenterPoint_dx_XX = 0.0 AND CenterPoint_dy_XX = -102.4";
CM_ SG_ 1219 CenterPoint_dx_27 "Longitudinal distance to the center line point. Invalid if CenterPoint_dx_XX = 0.0 AND CenterPoint_dy_XX = -102.4";
CM_ SG_ 1219 CenterPoint_dy_27 "Lateral distance to the center line point. Invalid if CenterPoint_dx_XX = 0.0 AND CenterPoint_dy_XX = -102.4";
CM_ SG_ 1219 CenterPoint_dx_28 "Longitudinal distance to the center line point. Invalid if CenterPoint_dx_XX = 0.0 AND CenterPoint_dy_XX = -102.4";
CM_ SG_ 1219 CenterPoint_dy_28 "Lateral distance to the center line point. Invalid if CenterPoint_dx_XX = 0.0 AND CenterPoint_dy_XX = -102.4";
CM_ SG_ 1219 CenterPoint_dx_29 "Longitudinal distance to the center line point. Invalid if CenterPoint_dx_XX = 0.0 AND CenterPoint_dy_XX = -102.4";
CM_ SG_ 1219 CenterPoint_dy_29 "Lateral distance to the center line point. Invalid if CenterPoint_dx_XX = 0.0 AND CenterPoint_dy_XX = -102.4";
CM_ SG_ 1219 CenterPoint_dx_30 "Longitudinal distance to the center line point. Invalid if CenterPoint_dx_XX = 0.0 AND CenterPoint_dy_XX = -102.4";
CM_ SG_ 1219 CenterPoint_dy_30 "Lateral distance to the center line point. Invalid if CenterPoint_dx_XX = 0.0 AND CenterPoint_dy_XX = -102.4";
CM_ SG_ 1219 CenterPoint_dx_31 "Longitudinal distance to the center line point. Invalid if CenterPoint_dx_XX = 0.0 AND CenterPoint_dy_XX = -102.4";
CM_ SG_ 1219 CenterPoint_dy_31 "Lateral distance to the center line point. Invalid if CenterPoint_dx_XX = 0.0 AND CenterPoint_dy_XX = -102.4";
CM_ SG_ 1219 CenterPoint_dx_32 "Longitudinal distance to the center line point. Invalid if CenterPoint_dx_XX = 0.0 AND CenterPoint_dy_XX = -102.4";
CM_ SG_ 1219 CenterPoint_dy_32 "Lateral distance to the center line point. Invalid if CenterPoint_dx_XX = 0.0 AND CenterPoint_dy_XX = -102.4";
CM_ SG_ 1219 CenterPoint_dx_33 "Longitudinal distance to the center line point. Invalid if CenterPoint_dx_XX = 0.0 AND CenterPoint_dy_XX = -102.4";
CM_ SG_ 1219 CenterPoint_dy_33 "Lateral distance to the center line point. Invalid if CenterPoint_dx_XX = 0.0 AND CenterPoint_dy_XX = -102.4";
CM_ SG_ 1219 CenterPoint_dx_34 "Longitudinal distance to the center line point. Invalid if CenterPoint_dx_XX = 0.0 AND CenterPoint_dy_XX = -102.4";
CM_ SG_ 1219 CenterPoint_dy_34 "Lateral distance to the center line point. Invalid if CenterPoint_dx_XX = 0.0 AND CenterPoint_dy_XX = -102.4";
CM_ SG_ 1219 centerline_LaneWidth "current lane width";
CM_ SG_ 1219 localization_lat_StdDev "Localizer standard deviation lateral wrt ego vehicle coordinates";
CM_ SG_ 1219 localization_long_StdDev "Localizer standard deviation longitudinal wrt ego vehicle coordinates";
CM_ SG_ 1219 localization_heading_StdDev "Localizer standard deviation in heading";
CM_ SG_ 1219 map_position_deviation "Distance between map matched position and estimated position";
CM_ SG_ 1219 map_position_accuracy "Standard deviation of the offset";
CM_ SG_ 1219 Timestamp "Map data timestamp for synchronization";
CM_ BO_ 1221 "central line with high resolution up to 0.001m";
CM_ BO_ 1220 "central line from 0 to  -20m";
CM_ SG_ 1217 Cv_CRC "CRC - Autosar E2E Profile 5";
CM_ SG_ 1217 Cv_AliveCtr "Alive counter - Autosar E2E Profile 5";
CM_ SG_ 1217 Cv_Value_Seg00 "Absolute value of curvature at the segment";
CM_ SG_ 1217 Cv_Value_Seg01 "Absolute value of curvature at the segment";
CM_ SG_ 1217 Cv_Value_Seg02 "Absolute value of curvature at the segment";
CM_ SG_ 1217 Cv_Value_Seg03 "Absolute value of curvature at the segment";
CM_ SG_ 1217 Cv_Value_Seg04 "Absolute value of curvature at the segment";
CM_ SG_ 1217 Cv_Value_Seg05 "Absolute value of curvature at the segment";
CM_ SG_ 1217 Cv_Value_Seg06 "Absolute value of curvature at the segment";
CM_ SG_ 1217 Cv_Value_Seg07 "Absolute value of curvature at the segment";
CM_ SG_ 1217 Cv_Value_Seg08 "Absolute value of curvature at the segment";
CM_ SG_ 1217 Cv_Value_Seg09 "Absolute value of curvature at the segment";
CM_ SG_ 1217 Cv_Value_Seg10 "Absolute value of curvature at the segment";
CM_ SG_ 1217 Cv_Value_Seg11 "Absolute value of curvature at the segment";
CM_ SG_ 1217 Cv_Value_Seg12 "Absolute value of curvature at the segment";
CM_ SG_ 1217 Cv_Value_Seg13 "Absolute value of curvature at the segment";
CM_ SG_ 1217 Cv_Value_Seg14 "Absolute value of curvature at the segment";
CM_ SG_ 1217 Cv_Value_Seg15 "Absolute value of curvature at the segment";
CM_ SG_ 1217 Cv_Value_Seg16 "Absolute value of curvature at the segment";
CM_ SG_ 1217 Cv_Value_Seg17 "Absolute value of curvature at the segment";
CM_ SG_ 1217 Cv_Value_Seg18 "Absolute value of curvature at the segment";
CM_ SG_ 1217 Cv_Value_Seg19 "Absolute value of curvature at the segment";
CM_ SG_ 1217 Cv_Offset_Seg00 "Offset of the curvature value at the segment";
CM_ SG_ 1217 Cv_Offset_Seg01 "Offset of the curvature value at the segment";
CM_ SG_ 1217 Cv_Offset_Seg02 "Offset of the curvature value at the segment";
CM_ SG_ 1217 Cv_Offset_Seg03 "Offset of the curvature value at the segment";
CM_ SG_ 1217 Cv_Offset_Seg04 "Offset of the curvature value at the segment";
CM_ SG_ 1217 Cv_Offset_Seg05 "Offset of the curvature value at the segment";
CM_ SG_ 1217 Cv_Offset_Seg06 "Offset of the curvature value at the segment";
CM_ SG_ 1217 Cv_Offset_Seg07 "Offset of the curvature value at the segment";
CM_ SG_ 1217 Cv_Offset_Seg08 "Offset of the curvature value at the segment";
CM_ SG_ 1217 Cv_Offset_Seg09 "Offset of the curvature value at the segment";
CM_ SG_ 1217 Cv_Offset_Seg10 "Offset of the curvature value at the segment";
CM_ SG_ 1217 Cv_Offset_Seg11 "Offset of the curvature value at the segment";
CM_ SG_ 1217 Cv_Offset_Seg12 "Offset of the curvature value at the segment";
CM_ SG_ 1217 Cv_Offset_Seg13 "Offset of the curvature value at the segment";
CM_ SG_ 1217 Cv_Offset_Seg14 "Offset of the curvature value at the segment";
CM_ SG_ 1217 Cv_Offset_Seg15 "Offset of the curvature value at the segment";
CM_ SG_ 1217 Cv_Offset_Seg16 "Offset of the curvature value at the segment";
CM_ SG_ 1217 Cv_Offset_Seg17 "Offset of the curvature value at the segment";
CM_ SG_ 1217 Cv_Offset_Seg18 "Offset of the curvature value at the segment";
CM_ SG_ 1217 Cv_Offset_Seg19 "Offset of the curvature value at the segment";
CM_ SG_ 1216 GF_map_position_accuracy "Standard deviation of the offset";
CM_ SG_ 1216 GF_map_position_deviation "Distance between map matched position and estimated position";
CM_ SG_ 1216 GF_CRC "CRC - Autosar E2E Profile 5";
CM_ SG_ 1216 GF_AliveCtr "Alive counter - Autosar E2E Profile 5";
CM_ SG_ 1216 GF_Currentlane_Index "Position-->currentlaneindex";
CM_ SG_ 1216 GF_NumberOfLanes "Position-->NumberOfLanePerDirection in current path";
CM_ SG_ 1216 GF_Region_outOfODD_offset "Offset to the nearest  upcoming out of ODD  region for the current path";
CM_ SG_ 1216 GF_Country_outOfODD_offset "Offset to the nearest  upcoming out of ODD  country for the current path";
CM_ SG_ 1216 GF_LaneTrans_outOfODD_offset "Offset to the nearest  upcoming out of ODD  lane transition for the current path";
CM_ SG_ 1216 GF_Curvature_outOfODD_offset "Offset to point in the lane at which the curve radius is below minViableRoadRadius";
CM_ SG_ 1216 GF_LaneType_outOfODD_offset "Offset to the nearest  upcoming  out of ODD lane type of the current path";
CM_ SG_ 1216 GF_RoadSlope_outOfODD_offset "Offset to point in the road at which the road slope is below minRoadSlope or above maxRoadSlope.";
CM_ SG_ 1216 GF_LaneWidth_outOfODD_offset "Offset to point in the lane at which the lane width is below the minLaneWidth threshold";
CM_ SG_ 1216 GF_FormOfWay_outOfODD_offset "Offset to the nearest  upcoming  out of ODD  form of way (road class) for the current path";
CM_ SG_ 1216 GF_MapExpired "True if the map data is older than maxMapAge. False otherwise.";
CM_ SG_ 1216 GF_BlackListedSegment_offset "Offset to the nearest  upcoming out black listed segment for the current path";
CM_ SG_ 1216 GF_Intersection_offset "Offset to the nearest  upcoming intersection for the current path";
CM_ SG_ 1216 GF_SideWind_offset "Offset to the nearest  upcoming side wind sign  for the current path";
CM_ SG_ 1216 GF_ActiveSpeedLimit "Current speed limit";
CM_ SG_ 1216 GF_TollGate_offset "Offset to the nearest  upcoming tollgate  for the current path";
CM_ SG_ 1216 GF_TrafficLight_offset "Offset to the nearest  upcoming traffic light  for the current path";
CM_ SG_ 1216 GF_Tunnel_Offset "Offset to the nearest  upcoming tunnel for the current path";
CM_ SG_ 1216 GF_MapStatus "This enumeration defines values for the Map Status. These values are not mutually exclusive and they are intended to be used as a bitmask obtained by an OR of all values.";
CM_ SG_ 625 iBooster_271_CheckSum "iBooster_271_CheckSum";
CM_ SG_ 625 iBooster_271_AliveCounter "iBooster_271_AliveCounter";
CM_ SG_ 625 iBooster_BrkPedlAppldFlg "information about the driver attendance.";
CM_ SG_ 625 iBooster_BrkPedlAppldVld "(dbc not readable)»
Qualifier for BrakePedalApplied.";
CM_ SG_ 592 EHU_SegFuncRoadClass "segment Functional Road Class indicates relative importance of the road in the routing network and lower values indicate higher priority. This information is usually map-provider specific.";
CM_ SG_ 592 EHU_SegEffSpdLmtType "segment";
CM_ SG_ 593 EHU_StubFuncRoadClass "Functional Road Class of new path indicates relative importance of the road in the routing network and lower values indicate higher priority. This information is usually map-provider specific. Regular values are 1-6; value 0 is unknown, value 7 indicates N/A.";
CM_ SG_ 593 EHU_StubTurnAngl "(dbc not readable)";
CM_ SG_ 822 EHU_336_Checksum "EHU_336_Checksum";
CM_ SG_ 822 EHU_336_AliveCounter "EHU_336_AliveCounter";
CM_ SG_ 822 EHU_SpdLimOffs "(dbc not readable)";
CM_ SG_ 1317 EHU_525_CheckSum "EHU_525_CheckSum";
CM_ SG_ 1317 EHU_525_AliveCounter "EHU_525_AliveCounterr";
CM_ SG_ 1317 EHU_GPSLongi "Longitude";
CM_ SG_ 1317 EHU_GPSLati "Latitude";
CM_ SG_ 1318 EHU_IntegtCrsSwt "(dbc not readable)";
CM_ SG_ 1318 EHU_IntegtCrsModSet "(dbc not readable)";
CM_ SG_ 1318 EHU_LaneSprtSwt "(dbc not readable)";
CM_ SG_ 1318 EHU_LaneSprtTypSet "(dbc not readable)";
CM_ SG_ 1318 EHU_FCWFCTASwt "(dbc not readable)";
CM_ SG_ 1318 EHU_AEBFCTBSwt "(dbc not readable)";
CM_ SG_ 1318 EHU_ESSSwt "(dbc not readable)";
CM_ SG_ 1328 EHU_NavRoadTyp "Road type from navigation.";
CM_ SG_ 1328 EHU_NavSpdLimUnit "Speed limit unit from naviation.";
CM_ SG_ 1328 EHU_NavSpdLimSts "Navigation state.";
CM_ SG_ 1328 EHU_NavSpdLim "Speed limit from navigation.";
CM_ SG_ 1328 EHU_NavSpdLimExitDst "(dbc not readable)";
CM_ SG_ 1329 ICM_TotMilgVld_ODO "(dbc not readable)";
CM_ SG_ 1329 ICM_TotMilg_ODO "(dbc not readable)";
CM_ SG_ 1329 ICM_DispVehSpd "Displayed vehicel speed on cluster instrument
Modified from original BJEV to match resolution of VW ECAN";
CM_ SG_ 1329 ICM_DispVehSpdUnit "Unit of displayed vehicle speed in cluster instrument";
CM_ SG_ 1329 ICM_ADASSigFlt "(dbc not readable)";
CM_ SG_ 1329 ICM_DispFlt "(dbc not readable)";
CM_ BO_ 626 "Inertial sensor Bosch MMP2, additional reference
Accelerations 3 DOF";
CM_ SG_ 626 acc_z "vertical acceleration from MMP2";
CM_ SG_ 626 acc_y "lateral acceleration from MMP2";
CM_ SG_ 626 acc_x "longitudinal acceleration from MMP2";
CM_ BO_ 627 "Inertial sensor Bosch MMP2, additional reference
Rates 3 DOF";
CM_ SG_ 336 MCU_F_150_CheckSum "MCU_F_150_CheckSum";
CM_ SG_ 336 MCU_F_150_AliveCounter "MCU_F_150_AliveCounter";
CM_ SG_ 336 MCU_F_CrtSpd "MotorFSpeed";
CM_ SG_ 336 MCU_F_CrtSpdSigVld "MotorFSpeedsignalvalidflag";
CM_ SG_ 337 MCU_R_151_CheckSum "MCU_R_151_CheckSum";
CM_ SG_ 337 MCU_R_151_AliveCounter "MCU_R_151_AliveCounter";
CM_ SG_ 337 MCU_R_CrtSpd "MotorRSpeed";
CM_ SG_ 337 MCU_R_CrtSpdSigVld "(dbc not readable)»
MotorRSpeedsignalvalidflag";
CM_ SG_ 1300 MFS_LeRollPress "(dbc not readable)";
CM_ SG_ 1300 MFS_RiRollPress "(dbc not readable)";
CM_ BO_ 820 "Used to be sent by BJEV camera to BJEV DASy.
Sent by HASy as static value (as PF camera does not send it anymore)
TBD if still needed";
CM_ SG_ 820 MPC_FrntCamBli "(dbc not readable)";
CM_ SG_ 820 MPC_FrntCamFlt "(dbc not readable)";
CM_ BO_ 448 "Lateral actuation request DASy to Steering
TBD if rename to ADAS2EPS?";
CM_ SG_ 448 ADAS_SteerWhlVibrFrq "Steering wheel haptic vibration frequency signal";
CM_ SG_ 448 ADAS_SteerWhlVibrAmp "Steering wheel haptic vibration amplitude signal";
CM_ SG_ 448 ADAS_1C0_CheckSum "Checksum ADAS_1C0";
CM_ SG_ 448 ADAS_1C0_AliveCounter "AliveCounter ADAS_1C0 - AUTOSAR E2E Profile 1";
CM_ SG_ 448 ADAS_LatMtnCtrlSts "(dbc not readable)";
CM_ SG_ 448 ADAS_SteerTqReq "(dbc not readable)";
CM_ SG_ 448 ADAS_WarnVbrnReq "(dbc not readable)";
CM_ SG_ 448 ADAS_LatMtnTypExed "(dbc not readable)(Reserved)";
CM_ SG_ 448 ADAS_LeTrunLampReq "(dbc not readable)";
CM_ SG_ 448 ADAS_RiTrunLampReq "(dbc not readable)";
CM_ SG_ 596 ADAS_254_CheckSum "CheckSum ADAS_254";
CM_ SG_ 596 ADAS_254_AliveCounter "AliveCounter ADAS_254 - AUTOSAR E2E Profile 1";
CM_ SG_ 596 ADAS_TqReq_ACC "(dbc not readable)";
CM_ SG_ 596 ADAS_Sts_ACC "(dbc not readable)";
CM_ SG_ 596 ADAS_WhlTq_ACC "(dbc not readable)";
CM_ SG_ 596 ADAS_TarA_ACC "(dbc not readable)";
CM_ SG_ 596 ADAS_DecelToStopReq_ACC "ACC request the VLC to decelerate to stop.";
CM_ SG_ 596 ADAS_TarAReq_ACC "(dbc not readable)";
CM_ SG_ 596 ADAS_DrvOffReq_ACC "(dbc not readable)ACC request the VLC to drive off.";
CM_ BO_ 601 "TBD if still in usage
Used to be send by Front Radar for the AEB feature (hosted on FR for BJEV).";
CM_ SG_ 601 ADAS_Req_Prefill "Prefill??";
CM_ SG_ 601 ADAS_Req_HBA "HBA??";
CM_ SG_ 601 ADAS_Req_AWB "AWB??";
CM_ SG_ 601 ADAS_Lvl_HBA "HBA??";
CM_ SG_ 601 ADAS_Lvl_AWB "AWB??";
CM_ SG_ 601 ADAS_DecelTyp_AEB "AEB?????";
CM_ SG_ 601 ADAS_Decel_AEB "AEB???";
CM_ SG_ 601 ADAS_259_CheckSum "CheckSum ADAS_259";
CM_ SG_ 601 ADAS_259_AliveCounter "AliveCounter ADAS_259";
CM_ BO_ 602 "new message for AEB interface (replaces MRR_0x259)";
CM_ SG_ 602 ADAS_Req_Prefill "Prefill??";
CM_ SG_ 602 ADAS_Req_HBA "HBA??";
CM_ SG_ 602 ADAS_Req_AWB "AWB??";
CM_ SG_ 602 ADAS_Lvl_HBA "HBA??";
CM_ SG_ 602 ADAS_Lvl_AWB "AWB??";
CM_ SG_ 602 ADAS_DecelTyp_AEB "AEB?????";
CM_ SG_ 602 ADAS_Decel_AEB "AEB???";
CM_ SG_ 602 ADAS_25A_CheckSum "CheckSum ADAS_259";
CM_ SG_ 602 ADAS_25A_AliveCounter "AliveCounter ADAS_259";
CM_ SG_ 603 ADAS_Fwd_Safety_Func "ADAS_Fwd_Safety_Func";
CM_ SG_ 812 ADAS_Sts_LKA "(dbc not readable)";
CM_ SG_ 812 ADAS_Sts_TJAICA "(dbc not readable)";
CM_ SG_ 812 ADAS_FCWSnvty "(dbc not readable)";
CM_ SG_ 812 ADAS_ADASSnvtySetFb "ADAS Feedback on sensitivity settings";
CM_ SG_ 812 ADAS_SysWarnTyp "(dbc not readable)";
CM_ SG_ 812 ADAS_Sts_ELK_re "(dbc not readable)";
CM_ SG_ 812 ADAS_HandsOffTakeOverReq "(dbc not readable)";
CM_ SG_ 812 ADAS_IntvMod_ELK "(dbc not readable)";
CM_ SG_ 812 ADAS_IntvDir_ELK "(dbc not readable)";
CM_ SG_ 812 ADAS_Sts_RDP "(dbc not readable)";
CM_ SG_ 812 ADAS_Sts_LDW "(dbc not readable)";
CM_ SG_ 812 ADAS_AudioWarn "(dbc not readable)";
CM_ SG_ 812 ADAS_LatMtnColor "(dbc not readable)";
CM_ SG_ 812 ADAS_DispReq "(dbc not readable)";
CM_ SG_ 812 ADAS_Sts_ELK_oc "(dbc not readable)";
CM_ SG_ 812 ADAS_Sts_ELK_ot "(dbc not readable)";
CM_ SG_ 828 ADAS_Warn_FCW "(dbc not readable)";
CM_ SG_ 828 ADAS_WarnTyp_FCWAEB "(dbc not readable)";
CM_ SG_ 828 ADAS_Sts_FCW "(dbc not readable)";
CM_ SG_ 828 ADAS_Sts_AEB "(dbc not readable)";
CM_ SG_ 830 MRR_FrntSnsrFlt "(dbc not readable))";
CM_ SG_ 830 MRR_FrntSnsrBli "(dbc not readable)";
CM_ SG_ 832 ADAS_LaneCrvt "The radium of the ego cars lane.";
CM_ SG_ 832 ADAS_LeLineTyp "The type of the left line.";
CM_ SG_ 832 ADAS_RiLineTyp "The type of the Right line.";
CM_ SG_ 832 ADAS_LeLineColor "The color of the left line.";
CM_ SG_ 832 ADAS_RiLineColor "The color of the Right line.";
CM_ SG_ 832 ADAS_LeLineDst "indicate the y distance between the leftline and the ego car center.";
CM_ SG_ 832 ADAS_RiLineDst "indicate the y distance between the Rightline and the ego car center.";
CM_ SG_ 832 ADAS_LeLineFlash "(dbc not readable)";
CM_ SG_ 832 ADAS_RiLineFlash "(dbc not readable)";
CM_ SG_ 832 ADAS_ESSSwtFb "(dbc not readable)";
CM_ SG_ 832 ADAS_IntegtCrsSwtFb "(dbc not readable)";
CM_ SG_ 832 ADAS_IntegtCrsModSetFb "(dbc not readable)";
CM_ SG_ 832 ADAS_LaneSprtSwtFb "(dbc not readable)";
CM_ SG_ 832 ADAS_LaneSprtTypSetFb "(dbc not readable)";
CM_ SG_ 832 ADAS_FCWFCTASwtFb "(dbc not readable)";
CM_ SG_ 832 ADAS_AEBFCTBSwtFb "TBD
Automatic emergency brake switch feedback";
CM_ SG_ 832 ADAS_FltIndcr "(dbc not readable)";
CM_ SG_ 832 ADAS_VoiceSpdRglnFb "(dbc not readable)";
CM_ SG_ 832 ADAS_IntegtCrsFltTxt "(dbc not readable)";
CM_ SG_ 832 ADAS_LaneSprtFltTxt "(dbc not readable)";
CM_ SG_ 832 ADAS_FwdWarnFltTxt "(dbc not readable)";
CM_ SG_ 832 ADAS_IntecnFltTxt "(dbc not readable)";
CM_ SG_ 832 ADAS_ACCIconDisp "TBD
ACC icon color on HMI";
CM_ SG_ 838 ADAS_FrntTar1X_ACC "A(dbc not readable)";
CM_ SG_ 838 ADAS_FrntTar1Y_ACC "(dbc not readable)";
CM_ SG_ 838 ADAS_FrntTar2X_ACC "(dbc not readable)";
CM_ SG_ 838 ADAS_FrntTar2Y_ACC "(dbc not readable)";
CM_ SG_ 838 ADAS_LeFrntTarX_ACC "(dbc not readable)";
CM_ SG_ 838 ADAS_LeFrntTarY_ACC "(dbc not readable)";
CM_ SG_ 838 ADAS_RiFrntTarX_ACC "(dbc not readable)";
CM_ SG_ 838 ADAS_RiFrntTarY_ACC "(dbc not readable)";
CM_ SG_ 839 ADAS_FrntTar1Typ_ACC "(dbc not readable)";
CM_ SG_ 839 ADAS_FrntTar2Typ_ACC "(dbc not readable)";
CM_ SG_ 839 ADAS_DispSpdUnit_ACC "(dbc not readable)";
CM_ SG_ 839 ADAS_LeFrntTarTyp_ACC "(dbc not readable)";
CM_ SG_ 839 ADAS_RiFrntTarTyp_ACC "(dbc not readable)";
CM_ SG_ 839 ADAS_OperTxt "(dbc not readable)";
CM_ SG_ 839 ADAS_TiGapSet_ACC "(dbc not readable)";
CM_ SG_ 839 ADAS_TakeOverReq_ACC "(dbc not readable)";
CM_ SG_ 839 ADAS_DispSpd_ACC "(dbc not readable)";
CM_ SG_ 839 ADAS_Sts_ACC_ICC "(dbc not readable)";
CM_ SG_ 839 ADAS_SpdLimUnit_ASL "(dbc not readable)";
CM_ SG_ 839 ADAS_SpdLim_ASL "(dbc not readable)";
CM_ SG_ 839 ADAS_SpdLimSts_ASL "(dbc not readable)";
CM_ BO_ 819 "Vehicle PowerMode";
CM_ SG_ 819 PEPS_333_CheckSum "PEPS_333_CheckSum";
CM_ SG_ 819 PEPS_333_AliveCounter "PEPS_333_AliveCounter";
CM_ SG_ 819 PEPS_PwrMod "indicates PowerMode";
CM_ SG_ 819 PEPS_PwrModVld "indicates validity of PowerMode";
CM_ BO_ 1137 "Trunk door open/close information";
CM_ SG_ 1137 PLG_TrSwtStsIndcn "Indicates trunk status";
CM_ BO_ 793 "TBD if still needed
Airbag information";
CM_ SG_ 793 SDM_319_CheckSum "SDM_319_±¨ÎÄ¼ìÑéºÍ(0x98)
SDM_319_CheckSum";
CM_ SG_ 793 SDM_319_AliveCounter "SDM_319_±¨ÎÄ¼ÆÊýÆ÷
SDM_319_AliveCounter";
CM_ SG_ 793 SDM_AirBagSysAlrmLampSts "(dbc not readable)";
CM_ SG_ 793 SDM_DrverSecuBltAlrmSts "(dbc not readable)";
CM_ SG_ 793 SDM_PassSecuBltAlrmSts "(dbc not readable)";
CM_ SG_ 793 SDM_CllsnSig "(dbc not readable)";
CM_ SG_ 793 SDM_FrntCllsn "(dbc not readable)";
CM_ SG_ 793 SDM_LeSideCllsn "(dbc not readable)";
CM_ SG_ 793 SDM_RiSideCllsn "(dbc not readable)";
CM_ SG_ 793 SDM_ReCllsn "(dbc not readable)";
CM_ SG_ 1583 TBOX_CrtTi_Day "(dbc not readable)";
CM_ SG_ 1583 TBOX_CrtTi_Hr "(dbc not readable)";
CM_ SG_ 1583 TBOX_CrtTi_Mins "(dbc not readable)";
CM_ SG_ 1583 TBOX_CrtTi_Yr "(dbc not readable)";
CM_ SG_ 1583 TBOX_CrtTi_Mth "(dbc not readable)";
CM_ SG_ 1583 TBOX_CrtTi_Sec "(dbc not readable)";
CM_ BO_ 1417 "TBD if still needed
tire pressure monitoring system?";
CM_ SG_ 1417 TPMS_TirePosn "(dbc not readable)";
CM_ SG_ 1417 TPMS_SngTirePSts "(dbc not readable)";
CM_ SG_ 442 VCU_1BA_CheckSum "(dbc not readable)VCU_1BA_CheckSum";
CM_ SG_ 442 VCU_1BA_AliveCounter "VCU_1BA_AliveCounter";
CM_ SG_ 442 VCU_DrvrAPSPerc "(dbc not readable)";
CM_ SG_ 442 VCU_DrvrAPSPercVld "(dbc not readable)";
CM_ SG_ 442 VCU_WhlTqActVld "(dbc not readable)";
CM_ SG_ 442 VCU_WhlTqAct "(dbc not readable)";
CM_ SG_ 532 VCU_214_CheckSum "VCU_214_CheckSum";
CM_ SG_ 532 VCU_214_AliveCounter "VCU_214_AliveCounter";
CM_ SG_ 532 VCU_RdyLamp "READY";
CM_ SG_ 532 VCU_GearSigVld "(dbc not readable)";
CM_ SG_ 532 VCU_GearSig "(dbc not readable)";
CM_ SG_ 532 VCU_DrvModSig "(dbc not readable)";
CM_ SG_ 549 VCU_225_CheckSum "VCU_225_±¨ÎÄÐ£ÑéºÍ(0x2A)
VCU_225_CheckSum";
CM_ SG_ 549 VCU_225_AliveCounter "VCU_225_±¨ÎÄ¼ÆÊýÆ÷
VCU_225_AliveCounter";
CM_ SG_ 549 VCU_OverMod "³¬Ô½Ä£Ê½";
CM_ SG_ 549 VCU_MotChkACCFltFbFlg "(dbc not readable)";
CM_ SG_ 549 VCU_VehTqFltSts "(dbc not readable)";
CM_ SG_ 549 VCU_VehMaxWhlTq "(dbc not readable)";
CM_ BO_ 578 "Intertial sensor series vehicle build-in , routed over MGW
Lateral Acceleration and YawRate";
CM_ SG_ 578 YRS_242_CheckSum "YRS_242_CheckSum";
CM_ SG_ 578 YRS_242_AliveCounter "YRS_242_AliveCounter";
CM_ SG_ 578 YRS_YawRateCalSts "Indicates YawRate Sensor Calibration State.";
CM_ SG_ 578 YRS_YawRateSnsrSts "Indicates YawRate Sensor State.";
CM_ SG_ 578 YRS_LatSnsrSts "Indicates Lateral Sensor State.";
CM_ SG_ 578 YRS_LatAcce "Real Value = raw value -offset, Indicates Lateral Acceleration.";
CM_ SG_ 578 YRS_YawRate "Real Value = raw value -offset, Indicates Yaw Rate.";
CM_ BO_ 582 "Intertial sensor series vehicle build-in , routed over MGW
Longitudinal Acceleration";
CM_ SG_ 582 YRS_246_CheckSum "(dbc not readable)";
CM_ SG_ 582 YRS_246_AliveCounter "(dbc not readable)";
CM_ SG_ 582 YRS_LgtSnsrSts "Indicates Longitudinal Sensor State";
CM_ SG_ 582 YRS_LgtAcce "Real Value = raw value -offset, Indicates Longitudinal Acceleration";
BA_DEF_ BO_  "GenMsgSendType" ENUM  "cyclic","NoMsgSendType","IfActive","Event","CA","CE";
BA_DEF_ BO_  "GenMsgCycleTime" INT 0 0;
BA_DEF_ SG_  "GenSigSendType" ENUM  "cyclic","OnChange","OnWrite","IfActive","OnChangeWithRepetition","OnWriteWithRepetition","IfActiveWithRepetition","CA","CE","Event";
BA_DEF_ SG_  "GenSigStartValue" INT 0 0;
BA_DEF_ BO_  "CANFD_BRS" ENUM  "0","1";
BA_DEF_ BO_  "VFrameFormat" ENUM  "StandardCAN","ExtendedCAN","reserved","reserved","reserved","reserved","reserved","reserved","reserved","reserved","reserved","reserved","reserved","reserved","StandardCAN_FD","ExtendedCAN_FD";
BA_DEF_ BO_  "GenMsgILSupport" ENUM  "No","Yes";
BA_DEF_DEF_  "GenMsgSendType" "cyclic";
BA_DEF_DEF_  "GenMsgCycleTime" 0;
BA_DEF_DEF_  "GenSigSendType" "cyclic";
BA_DEF_DEF_  "GenSigStartValue" 0;
BA_DEF_DEF_  "CANFD_BRS" "1";
BA_DEF_DEF_  "VFrameFormat" "StandardCAN";
BA_DEF_DEF_  "GenMsgILSupport" "Yes";
BA_ "GenMsgCycleTime" BO_ 1141 100;
BA_ "VFrameFormat" BO_ 1141 14;
BA_ "GenMsgCycleTime" BO_ 453 10;
BA_ "VFrameFormat" BO_ 453 14;
BA_ "GenMsgCycleTime" BO_ 278 10;
BA_ "VFrameFormat" BO_ 278 14;
BA_ "GenMsgCycleTime" BO_ 288 10;
BA_ "VFrameFormat" BO_ 288 14;
BA_ "GenMsgCycleTime" BO_ 290 10;
BA_ "VFrameFormat" BO_ 290 14;
BA_ "GenMsgCycleTime" BO_ 440 20;
BA_ "VFrameFormat" BO_ 440 14;
BA_ "GenMsgCycleTime" BO_ 609 20;
BA_ "VFrameFormat" BO_ 609 14;
BA_ "GenMsgCycleTime" BO_ 616 20;
BA_ "VFrameFormat" BO_ 616 14;
BA_ "GenMsgCycleTime" BO_ 773 20;
BA_ "VFrameFormat" BO_ 773 14;
BA_ "GenMsgCycleTime" BO_ 774 20;
BA_ "VFrameFormat" BO_ 774 14;
BA_ "GenMsgCycleTime" BO_ 778 20;
BA_ "VFrameFormat" BO_ 778 14;
BA_ "GenMsgCycleTime" BO_ 792 20;
BA_ "VFrameFormat" BO_ 792 14;
BA_ "GenMsgCycleTime" BO_ 818 50;
BA_ "VFrameFormat" BO_ 818 14;
BA_ "GenMsgCycleTime" BO_ 716 50;
BA_ "VFrameFormat" BO_ 716 14;
BA_ "GenMsgSendType" BO_ 1554 2;
BA_ "VFrameFormat" BO_ 1554 14;
BA_ "GenMsgCycleTime" BO_ 1218 100;
BA_ "VFrameFormat" BO_ 1218 14;
BA_ "GenMsgCycleTime" BO_ 1219 100;
BA_ "VFrameFormat" BO_ 1219 14;
BA_ "GenMsgCycleTime" BO_ 1221 100;
BA_ "VFrameFormat" BO_ 1221 14;
BA_ "GenMsgCycleTime" BO_ 1220 100;
BA_ "VFrameFormat" BO_ 1220 14;
BA_ "GenMsgCycleTime" BO_ 1217 100;
BA_ "VFrameFormat" BO_ 1217 14;
BA_ "GenMsgCycleTime" BO_ 1216 100;
BA_ "VFrameFormat" BO_ 1216 14;
BA_ "GenMsgCycleTime" BO_ 625 20;
BA_ "VFrameFormat" BO_ 625 14;
BA_ "GenMsgCycleTime" BO_ 592 20;
BA_ "VFrameFormat" BO_ 592 14;
BA_ "GenMsgCycleTime" BO_ 593 20;
BA_ "VFrameFormat" BO_ 593 14;
BA_ "GenMsgCycleTime" BO_ 822 100;
BA_ "VFrameFormat" BO_ 822 14;
BA_ "GenMsgCycleTime" BO_ 1317 100;
BA_ "VFrameFormat" BO_ 1317 14;
BA_ "GenMsgCycleTime" BO_ 1318 100;
BA_ "VFrameFormat" BO_ 1318 14;
BA_ "GenMsgCycleTime" BO_ 1319 100;
BA_ "VFrameFormat" BO_ 1319 14;
BA_ "GenMsgCycleTime" BO_ 1328 100;
BA_ "VFrameFormat" BO_ 1328 14;
BA_ "GenMsgCycleTime" BO_ 1329 100;
BA_ "VFrameFormat" BO_ 1329 14;
BA_ "GenMsgCycleTime" BO_ 626 10;
BA_ "VFrameFormat" BO_ 626 14;
BA_ "GenMsgCycleTime" BO_ 627 10;
BA_ "VFrameFormat" BO_ 627 14;
BA_ "GenMsgCycleTime" BO_ 1051 10;
BA_ "VFrameFormat" BO_ 1051 14;
BA_ "GenMsgCycleTime" BO_ 336 10;
BA_ "VFrameFormat" BO_ 336 14;
BA_ "GenMsgCycleTime" BO_ 337 10;
BA_ "VFrameFormat" BO_ 337 14;
BA_ "GenMsgCycleTime" BO_ 1300 100;
BA_ "VFrameFormat" BO_ 1300 14;
BA_ "GenMsgCycleTime" BO_ 820 50;
BA_ "VFrameFormat" BO_ 820 14;
BA_ "GenMsgCycleTime" BO_ 448 10;
BA_ "VFrameFormat" BO_ 448 14;
BA_ "GenMsgCycleTime" BO_ 596 20;
BA_ "VFrameFormat" BO_ 596 14;
BA_ "GenMsgCycleTime" BO_ 601 20;
BA_ "VFrameFormat" BO_ 601 14;
BA_ "GenMsgCycleTime" BO_ 602 20;
BA_ "VFrameFormat" BO_ 602 14;
BA_ "GenMsgCycleTime" BO_ 603 20;
BA_ "VFrameFormat" BO_ 603 14;
BA_ "GenMsgCycleTime" BO_ 812 50;
BA_ "VFrameFormat" BO_ 812 14;
BA_ "GenMsgCycleTime" BO_ 828 50;
BA_ "VFrameFormat" BO_ 828 14;
BA_ "GenMsgCycleTime" BO_ 830 50;
BA_ "VFrameFormat" BO_ 830 14;
BA_ "GenMsgCycleTime" BO_ 832 50;
BA_ "VFrameFormat" BO_ 832 14;
BA_ "GenMsgCycleTime" BO_ 838 50;
BA_ "VFrameFormat" BO_ 838 14;
BA_ "GenMsgCycleTime" BO_ 839 50;
BA_ "VFrameFormat" BO_ 839 14;
BA_ "GenMsgCycleTime" BO_ 819 50;
BA_ "VFrameFormat" BO_ 819 14;
BA_ "GenMsgCycleTime" BO_ 1137 100;
BA_ "VFrameFormat" BO_ 1137 14;
BA_ "GenMsgCycleTime" BO_ 1052 10;
BA_ "VFrameFormat" BO_ 1052 14;
BA_ "GenMsgCycleTime" BO_ 1764 10;
BA_ "VFrameFormat" BO_ 1764 14;
BA_ "GenMsgCycleTime" BO_ 1765 10;
BA_ "VFrameFormat" BO_ 1765 14;
BA_ "GenMsgCycleTime" BO_ 793 50;
BA_ "VFrameFormat" BO_ 793 14;
BA_ "GenMsgCycleTime" BO_ 1583 1000;
BA_ "VFrameFormat" BO_ 1583 14;
BA_ "GenMsgCycleTime" BO_ 1417 500;
BA_ "VFrameFormat" BO_ 1417 14;
BA_ "GenMsgCycleTime" BO_ 442 10;
BA_ "VFrameFormat" BO_ 442 14;
BA_ "GenMsgCycleTime" BO_ 532 10;
BA_ "VFrameFormat" BO_ 532 14;
BA_ "GenMsgCycleTime" BO_ 549 20;
BA_ "VFrameFormat" BO_ 549 14;
BA_ "GenMsgCycleTime" BO_ 1768 10;
BA_ "VFrameFormat" BO_ 1768 14;
BA_ "GenMsgCycleTime" BO_ 1770 10;
BA_ "VFrameFormat" BO_ 1770 14;
BA_ "GenMsgCycleTime" BO_ 578 10;
BA_ "VFrameFormat" BO_ 578 14;
BA_ "GenMsgCycleTime" BO_ 582 20;
BA_ "VFrameFormat" BO_ 582 14;
BA_ "GenSigStartValue" SG_ 453 EPS_ActRoadWheelAngValue 9000;
BA_ "GenSigStartValue" SG_ 453 EPS_ActRPCTrq 1024;
BA_ "GenSigStartValue" SG_ 453 EPS_IntRPCMaxTrq 1024;
BA_ "GenSigStartValue" SG_ 453 EPS_IntRPCMinTrq 1024;
BA_ "GenSigStartValue" SG_ 288 ESP_MstCylP 300;
BA_ "GenSigStartValue" SG_ 290 ESP_VmcVseAxOvrGrnd 32768;
BA_ "GenSigStartValue" SG_ 290 ESP_VmcVsevVeh 10000;
BA_ "GenSigStartValue" SG_ 290 ESP_VmcVseSasOffset 7800;
BA_ "GenSigStartValue" SG_ 440 ESP_RoadSlop 1000;
BA_ "GenSigStartValue" SG_ 778 ESP_LgtOffs 796;
BA_ "GenSigStartValue" SG_ 778 ESP_LatOffs 796;
BA_ "GenSigStartValue" SG_ 778 ESP_YAWVOffs 2143;
BA_ "GenSigStartValue" SG_ 1217 Cv_Offset_Seg00 1023;
BA_ "GenSigStartValue" SG_ 1217 Cv_Offset_Seg01 1023;
BA_ "GenSigStartValue" SG_ 1217 Cv_Offset_Seg02 1023;
BA_ "GenSigStartValue" SG_ 1217 Cv_Offset_Seg03 1023;
BA_ "GenSigStartValue" SG_ 1217 Cv_Offset_Seg04 1023;
BA_ "GenSigStartValue" SG_ 1217 Cv_Offset_Seg05 1023;
BA_ "GenSigStartValue" SG_ 1217 Cv_Offset_Seg06 1023;
BA_ "GenSigStartValue" SG_ 1217 Cv_Offset_Seg07 1023;
BA_ "GenSigStartValue" SG_ 1217 Cv_Offset_Seg08 1023;
BA_ "GenSigStartValue" SG_ 1217 Cv_Offset_Seg09 1023;
BA_ "GenSigStartValue" SG_ 1217 Cv_Offset_Seg10 1023;
BA_ "GenSigStartValue" SG_ 1217 Cv_Offset_Seg11 1023;
BA_ "GenSigStartValue" SG_ 1217 Cv_Offset_Seg12 1023;
BA_ "GenSigStartValue" SG_ 1217 Cv_Offset_Seg13 1023;
BA_ "GenSigStartValue" SG_ 1217 Cv_Offset_Seg14 1023;
BA_ "GenSigStartValue" SG_ 1217 Cv_Offset_Seg15 1023;
BA_ "GenSigStartValue" SG_ 1217 Cv_Offset_Seg16 1023;
BA_ "GenSigStartValue" SG_ 1217 Cv_Offset_Seg17 1023;
BA_ "GenSigStartValue" SG_ 1217 Cv_Offset_Seg18 1023;
BA_ "GenSigStartValue" SG_ 1217 Cv_Offset_Seg19 1023;
BA_ "GenSigStartValue" SG_ 592 EHU_SegFuncRoadClass 7;
BA_ "GenSigStartValue" SG_ 592 EHU_SegEffSpdLmtType 7;
BA_ "GenSigStartValue" SG_ 593 EHU_StubFuncRoadClass 7;
BA_ "GenSigStartValue" SG_ 593 EHU_StubTurnAngl 255;
BA_ "GenSigStartValue" SG_ 336 MCU_F_CrtSpd 32768;
BA_ "GenSigStartValue" SG_ 337 MCU_R_CrtSpd 32768;
BA_ "GenSigStartValue" SG_ 448 ADAS_SteerTqReq 800;
BA_ "GenSigStartValue" SG_ 596 ADAS_WhlTq_ACC 32768;
BA_ "GenSigStartValue" SG_ 832 ADAS_LaneCrvt 63;
BA_ "GenSigStartValue" SG_ 832 ADAS_LeLineDst 62;
BA_ "GenSigStartValue" SG_ 832 ADAS_RiLineDst 62;
BA_ "GenSigStartValue" SG_ 838 ADAS_FrntTar1Y_ACC 127;
BA_ "GenSigStartValue" SG_ 838 ADAS_FrntTar2Y_ACC 127;
BA_ "GenSigStartValue" SG_ 838 ADAS_LeFrntTarY_ACC 127;
BA_ "GenSigStartValue" SG_ 838 ADAS_RiFrntTarY_ACC 127;
BA_ "GenSigStartValue" SG_ 442 VCU_WhlTqAct 32768;
BA_ "GenSigStartValue" SG_ 549 VCU_VehMaxWhlTq 32768;
BA_ "GenSigStartValue" SG_ 578 YRS_LatAcce 2000;
BA_ "GenSigStartValue" SG_ 578 YRS_YawRate 18000;
BA_ "GenSigStartValue" SG_ 582 YRS_LgtAcce 2000;
VAL_ 1141 EPS_ModSts 0 "Reserved" 1 "Sport" 2 "Comfort" 3 "Reserved" ;
VAL_ 453 EPS_LatDrvLvl12SrvAvl 0 "NotAvailable" 1 "FailureDetected" 2 "Available" 3 "Reserved" ;
VAL_ 453 EPS_LatMCHptcWrnSrvAvl 0 "NotAvailable" 1 "FailureDetected" 2 "Available" 3 "Reserved" ;
VAL_ 453 EPS_ActRoadWheelAngState 0 "NotAvailable" 1 "FailureDetected" 2 "Available" 3 "Reserved" ;
VAL_ 453 EPS_LatMCRoadWheelAngActive 0 "RdWhlAgReq not active" 1 "RdWhlAgReq active" ;
VAL_ 278 ESP_Wegimpuls_HR 1021 "Init" 1022 "Unterspannung" 1023 "Fehler" ;
VAL_ 278 ESP_Wegimpuls_HL 1021 "Init" 1022 "Unterspannung" 1023 "Fehler" ;
VAL_ 278 ESP_Wegimpuls_VR 1021 "Init" 1022 "Unterspannung" 1023 "Fehler" ;
VAL_ 278 ESP_Wegimpuls_VL 1021 "Init" 1022 "Unterspannung" 1023 "Fehler" ;
VAL_ 278 ESP_QBit_Wegimpuls_HR 0 "gueltiger_Wert" 1 "Ersatz_Init_oder_Fehlerwert" ;
VAL_ 278 ESP_QBit_Wegimpuls_HL 0 "gueltiger_Wert" 1 "Ersatz_Init_oder_Fehlerwert" ;
VAL_ 278 ESP_QBit_Wegimpuls_VR 0 "gueltiger_Wert" 1 "Ersatz_Init_oder_Fehlerwert" ;
VAL_ 278 ESP_QBit_Wegimpuls_VL 0 "gueltiger_Wert" 1 "Ersatz_Init_oder_Fehlerwert" ;
VAL_ 288 ESP_ActvSig_ABS 0 "ABS Standby" 1 "ABS Actually Operating" ;
VAL_ 288 ESP_VmcVseYawRateAvlCpby 0 "NotAvl" 1 "Fault" 2 "AvlCpbyLo" 3 "AvlCpbyMid" 4 "AvlCpbyHi" 5 "Reserved" 6 "Reserved" 7 "Reserved" ;
VAL_ 288 ESP_MstCylPVld 0 "Initializing" 1 "Valid" 2 "Invalid" 3 "Reserved" ;
VAL_ 288 ESP_VmcVseSasAvlCpby 0 "NotAvl" 1 "Fault" 2 "AvlCpbyLo" 3 "AvlCpbyMid" 4 "AvlCpbyHi" 5 "Reserved" 6 "Reserved" 7 "Reserved" ;
VAL_ 288 ESP_MstCylPOffsVld 0 "Initializing" 1 "Valid" 2 "Invalid" 3 "Reserved" ;
VAL_ 290 ESP_VmcVseLgtPrimSrvAvlCpby 0 "NotAvl" 1 "Fault" 2 "AvlCpbyLo" 3 "AvlCpbyMid" 4 "AvlCpbyHi" 5 "Reserved" 6 "Reserved" 7 "Reserved" ;
VAL_ 290 ESP_VmcVseSasOffset 65535 "Invalid" ;
VAL_ 609 ESP_ActvSig 0 "ESP Standby" 1 "ESP Actually Operating" ;
VAL_ 609 ESP_ActvSig_TCS 0 "TCS Standby" 1 "TCS Actually Operating" ;
VAL_ 609 ESP_ActvSig_EBD 0 "EBD Not Active" 1 "EBD Active" ;
VAL_ 609 ESP_ActvSig_DTC 0 "DTC Not Active" 1 "DTC Active" ;
VAL_ 609 ESP_Actvndcn_CDD 0 "Not Active" 1 "Active" ;
VAL_ 609 ESP_FltIndcn_CDD 0 "Available" 1 "Not Available" ;
VAL_ 609 ESP_ActvIndcn_ABA 0 "Not Active" 1 "Active" ;
VAL_ 609 ESP_FltIndcn_ABA 0 "Available" 1 "Not Available" ;
VAL_ 609 ESP_ActvIndcn_ABP 0 "Not Active" 1 "Active" ;
VAL_ 609 ESP_FltIndcn_ABP 0 "Available" 1 "Not Available" ;
VAL_ 609 ESP_ActvIndcn_AEB 0 "Not Active" 1 "Active" ;
VAL_ 609 ESP_FltIndcn_AEB 0 "Available" 1 "Not Available" ;
VAL_ 609 ESP_ActvIndcn_AWB 0 "Not Active" 1 "Active" ;
VAL_ 609 ESP_FltIndcn_AWB 0 "Available" 1 "Not Available" ;
VAL_ 609 ESP_VehStandstillIndcn 0 "Not Standstill" 1 "Standstill" 2 "Invalid" 3 "Reserved" ;
VAL_ 609 ESP_BrkOverTIndcn 0 "Not High" 1 "Temp Too High" ;
VAL_ 616 ESP_SysSts_EPB 0 "Undefined" 1 "Released" 2 "Closed" 3 "Releasing" 4 "Locking" 5 "Reserved" 6 "Reserved" 7 "Reserved" ;
VAL_ 616 ESP_FltIndcn_EPB 0 "Available" 1 "Not Available" 2 "In Diagnosis" 3 "Reserved" ;
VAL_ 616 ESP_YawRateStabnAvl 0 "None" 1 "Full" ;
VAL_ 616 ESP_EPBSwtichPosition 0 "Neutral" 1 "Release" 2 "Apply" 3 "Reserved" ;
VAL_ 773 ESP_WhlSpdVld_RF 0 "Initializing" 1 "Valid" 2 "Invalid" 3 "Reserved" ;
VAL_ 773 ESP_WhlMovgDir_RF 0 "Init" 1 "Forward" 2 "Backward" 3 "Stop" 4 "Invalid" 5 "Reserved" 6 "Reserved" 7 "Reserved" ;
VAL_ 773 ESP_WhlMovgDir_LF 0 "Init" 1 "Forward" 2 "Backward" 3 "Stop" 4 "Invalid" 5 "Reserved" 6 "Reserved" 7 "Reserved" ;
VAL_ 773 ESP_WhlSpdVld_LF 0 "Initializing" 1 "Valid" 2 "Invalid" 3 "Reserved" ;
VAL_ 774 ESP_WhlSpdVld_RR 0 "Initializing" 1 "Valid" 2 "Invalid" 3 "Reserved" ;
VAL_ 774 ESP_WhlMovgDir_RR 0 "Init" 1 "Forward" 2 "Backward" 3 "Stop" 4 "Invalid" 5 "Reserved" 6 "Reserved" 7 "Reserved" ;
VAL_ 774 ESP_WhlMovgDir_RL 0 "Init" 1 "Forward" 2 "Backward" 3 "Stop" 4 "Invalid" 5 "Reserved" 6 "Reserved" 7 "Reserved" ;
VAL_ 774 ESP_WhlSpdVld_RL 0 "Initializing" 1 "Valid" 2 "Invalid" 3 "Reserved" ;
VAL_ 792 ESP_SwtOff_TCS 0 "DSC & TCS off/degraded" 1 "DSC & TCS on" ;
VAL_ 792 ESP_VehSpdVld 0 "Initializing" 1 "Valid" 2 "Invalid" 3 "Reserved" ;
VAL_ 792 ESP_LampSwtOffIndcn 0 "No Telltale Requested" 1 "Telltale Requested" ;
VAL_ 792 ESP_FltIndcn_ABS 0 "No Telltale Requested" 1 "Telltale Requested" ;
VAL_ 792 ESP_FltIndcn_TCS 0 "No Telltale Requested" 1 "Telltale Requested" ;
VAL_ 792 ESP_CtrlSts_HDC 0 "Off" 1 "On Active Braking" 2 "On Not Active Braking" 3 "Reserved" ;
VAL_ 792 ESP_NoBrkP 0 "Exist Brk Force" 1 "No Brk Force" ;
VAL_ 818 ESP_BrkLiReq 0 "Not Illuminate" 1 "Illuminate" ;
VAL_ 716 HODTchZone2Sts_h8HSC8 0 "No hand detected" 1 "Hand detected" 2 "Reserved" 3 "Reserved" 4 "Reserved" 5 "Reserved" 6 "Reserved" 7 "Reserved" ;
VAL_ 716 HODTchZone1Sts_h8HSC8 0 "No hand detected" 1 "Hand detected" 2 "Reserved" 3 "Reserved" 4 "Reserved" 5 "Reserved" 6 "Reserved" 7 "Reserved" ;
VAL_ 716 HODSysSts_h8HSC8 0 "Available" 1 "Initial Status" 2 "Fault" 3 "Shutdown" 4 "No Calibration" 5 "Reserved" 6 "Reserved" 7 "Reserved" ;
VAL_ 716 HODdiagSts_h8HSC8 0 "No Error" 1 "EEPROM" 2 "ROM Error" 3 "Watchdog Error" 4 "CPU Error" 5 "Guard Error" 6 "Sense Error" 7 "CPU Defect or Mat shortage" 8 "Undervoltage" 9 "Overvoltage" 10 "Coding Error" 11 "System Error" 12 "Reserved" 13 "Reserved" 14 "Reserved" 15 "Other state" ;
VAL_ 716 HODTchZone3Sts_h8HSC8 0 "No hand detected" 1 "Hand detected" 2 "Reserved" 3 "Reserved" 4 "Reserved" 5 "Reserved" 6 "Reserved" 7 "Reserved" ;
VAL_ 716 HODDetnSts_h8HSC8 0 "Unknown" 1 "No valid contact detected" 2 "Valid contact detected" 3 "Reserved" 4 "Reserved" 5 "Reserved" 6 "Reserved" 7 "Reserved" 8 "Reserved" 9 "Reserved" 10 "Reserved" 11 "Reserved" 12 "Reserved" 13 "Reserved" 14 "Reserved" 15 "Reserved" ;
VAL_ 1216 GF_NumberOfLanes 0 "wrong direction" 1 "1 lane" 2 "2 lanes" 3 "3 lanes" 4 "4 lanes" 5 "5 lanes" 6 "6 or more lanes" 7 "Unknown" ;
VAL_ 1216 GF_Region_outOfODD_offset 1023 "Not within horizon" ;
VAL_ 1216 GF_Country_outOfODD_offset 1023 "Not within horizon" ;
VAL_ 1216 GF_LaneTrans_outOfODD_offset 1023 "Not within horizon" ;
VAL_ 1216 GF_Curvature_outOfODD_offset 1023 "Not within horizon" ;
VAL_ 1216 GF_LaneType_outOfODD_offset 1023 "Not within horizon" ;
VAL_ 1216 GF_RoadSlope_outOfODD_offset 1023 "Not within horizon" ;
VAL_ 1216 GF_LaneWidth_outOfODD_offset 1023 "Not within horizon" ;
VAL_ 1216 GF_FormOfWay_outOfODD_offset 1023 "Not within horizon" ;
VAL_ 1216 GF_MapExpired 0 "0" 1 "1" ;
VAL_ 1216 GF_BlackListedSegment_offset 1023 "Not within horizon" ;
VAL_ 1216 GF_Intersection_offset 1023 "Not within horizon" ;
VAL_ 1216 GF_SideWind_offset 1023 "Not within horizon" ;
VAL_ 1216 GF_TollGate_offset 1023 "Not within ehorizon" ;
VAL_ 1216 GF_TrafficLight_offset 1023 "Not within ehorizon" ;
VAL_ 1216 GF_Tunnel_Offset 1023 "Not within ehorizon" ;
VAL_ 1216 GF_MapStatus 0 "Map Ready" 1 "Map not Ready" 2 "Traffic line missing" 4 "Local ECU not ready" 8 "Initialization" 16 "Map data expired" 32 "Hardware Error" 64 "Software Error" 128 "RTK not available" 256 "GNSS signal error" 512 "MapTimeSyncStatus" ;
VAL_ 625 iBooster_BrkPedlAppldFlg 0 "Brake Pedal Not Applied" 1 "Brake Pedal Applied" ;
VAL_ 625 iBooster_BrkPedlAppldVld 0 "Initializing" 1 "Valid" 2 "Invalid" 3 "Reserved" ;
VAL_ 592 EHU_SegFuncRoadClass 0 "Unknown" 7 "Invalid" ;
VAL_ 592 EHU_SegEffSpdLmtType 0 "Implicit(For Instance,Default Speed Limit In The Cities)" 1 "Explicit - On Traffic Sign" 2 "Explicit - By Night" 3 "Explicit - By Day" 4 "Explicit - Time Of Day" 5 "Expl+R[8]Cicit - Rain" 6 "Explicit - Snow" 7 "Invalid" ;
VAL_ 593 EHU_StubFuncRoadClass 7 "Invalid" ;
VAL_ 593 EHU_StubTurnAngl 0 "In Path Direction" 1 "1.417 Degrees Right" 2 "Right From Path Direction" 3 "Right From Path Direction" 4 "Right From Path Direction" 5 "Right From Path Direction" 6 "Right From Path Direction" 7 "Right From Path Direction" 8 "Right From Path Direction" 9 "Right From Path Direction" 10 "Right From Path Direction" 11 "Right From Path Direction" 12 "Right From Path Direction" 13 "Right From Path Direction" 14 "Right From Path Direction" 15 "Right From Path Direction" 16 "Right From Path Direction" 17 "Right From Path Direction" 18 "Right From Path Direction" 19 "Right From Path Direction" 20 "Right From Path Direction" 21 "Right From Path Direction" 22 "Right From Path Direction" 23 "Right From Path Direction" 24 "Right From Path Direction" 25 "Right From Path Direction" 26 "Right From Path Direction" 27 "Right From Path Direction" 28 "Right From Path Direction" 29 "Right From Path Direction" 30 "Right From Path Direction" 31 "Right From Path Direction" 32 "Right From Path Direction" 33 "Right From Path Direction" 34 "Right From Path Direction" 35 "Right From Path Direction" 36 "Right From Path Direction" 37 "Right From Path Direction" 38 "Right From Path Direction" 39 "Right From Path Direction" 40 "Right From Path Direction" 41 "Right From Path Direction" 42 "Right From Path Direction" 43 "Right From Path Direction" 44 "Right From Path Direction" 45 "Right From Path Direction" 46 "Right From Path Direction" 47 "Right From Path Direction" 48 "Right From Path Direction" 49 "Right From Path Direction" 50 "Right From Path Direction" 51 "Right From Path Direction" 52 "Right From Path Direction" 53 "Right From Path Direction" 54 "Right From Path Direction" 55 "Right From Path Direction" 56 "Right From Path Direction" 57 "Right From Path Direction" 58 "Right From Path Direction" 59 "Right From Path Direction" 60 "Right From Path Direction" 61 "Right From Path Direction" 62 "Right From Path Direction" 63 "Right From Path Direction" 64 "Right From Path Direction" 65 "Right From Path Direction" 66 "Right From Path Direction" 67 "Right From Path Direction" 68 "Right From Path Direction" 69 "Right From Path Direction" 70 "Right From Path Direction" 71 "Right From Path Direction" 72 "Right From Path Direction" 73 "Right From Path Direction" 74 "Right From Path Direction" 75 "Right From Path Direction" 76 "Right From Path Direction" 77 "Right From Path Direction" 78 "Right From Path Direction" 79 "Right From Path Direction" 80 "Right From Path Direction" 81 "Right From Path Direction" 82 "Right From Path Direction" 83 "Right From Path Direction" 84 "Right From Path Direction" 85 "Right From Path Direction" 86 "Right From Path Direction" 87 "Right From Path Direction" 88 "Right From Path Direction" 89 "Right From Path Direction" 90 "Right From Path Direction" 91 "Right From Path Direction" 92 "Right From Path Direction" 93 "Right From Path Direction" 94 "Right From Path Direction" 95 "Right From Path Direction" 96 "Right From Path Direction" 97 "Right From Path Direction" 98 "Right From Path Direction" 99 "Right From Path Direction" 100 "Right From Path Direction" 101 "Right From Path Direction" 102 "Right From Path Direction" 103 "Right From Path Direction" 104 "Right From Path Direction" 105 "Right From Path Direction" 106 "Right From Path Direction" 107 "Right From Path Direction" 108 "Right From Path Direction" 109 "Right From Path Direction" 110 "Right From Path Direction" 111 "Right From Path Direction" 112 "Right From Path Direction" 113 "Right From Path Direction" 114 "Right From Path Direction" 115 "Right From Path Direction" 116 "Right From Path Direction" 117 "Right From Path Direction" 118 "Right From Path Direction" 119 "Right From Path Direction" 120 "Right From Path Direction" 121 "Right From Path Direction" 122 "Right From Path Direction" 123 "Right From Path Direction" 124 "Right From Path Direction" 125 "Right From Path Direction" 126 "178.583 Degrees Right" 127 "Opposite Direction" 128 "178.583 Degrees Left (181.417 Degrees Right)+R[6]C" 129 "Left From Path Direction" 130 "Left From Path Direction" 131 "Left From Path Direction" 132 "Left From Path Direction" 133 "Left From Path Direction" 134 "Left From Path Direction" 135 "Left From Path Direction" 136 "Left From Path Direction" 137 "Left From Path Direction" 138 "Left From Path Direction" 139 "Left From Path Direction" 140 "Left From Path Direction" 141 "Left From Path Direction" 142 "Left From Path Direction" 143 "Left From Path Direction" 144 "Left From Path Direction" 145 "Left From Path Direction" 146 "Left From Path Direction" 147 "Left From Path Direction" 148 "Left From Path Direction" 149 "Left From Path Direction" 150 "Left From Path Direction" 151 "Left From Path Direction" 152 "Left From Path Direction" 153 "Left From Path Direction" 154 "Left From Path Direction" 155 "Left From Path Direction" 156 "Left From Path Direction" 157 "Left From Path Direction" 158 "Left From Path Direction" 159 "Left From Path Direction" 160 "Left From Path Direction" 161 "Left From Path Direction" 162 "Left From Path Direction" 163 "Left From Path Direction" 164 "Left From Path Direction" 165 "Left From Path Direction" 166 "Left From Path Direction" 167 "Left From Path Direction" 168 "Left From Path Direction" 169 "Left From Path Direction" 170 "Left From Path Direction" 171 "Left From Path Direction" 172 "Left From Path Direction" 173 "Left From Path Direction" 174 "Left From Path Direction" 175 "Left From Path Direction" 176 "Left From Path Direction" 177 "Left From Path Direction" 178 "Left From Path Direction" 179 "Left From Path Direction" 180 "Left From Path Direction" 181 "Left From Path Direction" 182 "Left From Path Direction" 183 "Left From Path Direction" 184 "Left From Path Direction" 185 "Left From Path Direction" 186 "Left From Path Direction" 187 "Left From Path Direction" 188 "Left From Path Direction" 189 "Left From Path Direction" 190 "Left From Path Direction" 191 "Left From Path Direction" 192 "Left From Path Direction" 193 "Left From Path Direction" 194 "Left From Path Direction" 195 "Left From Path Direction" 196 "Left From Path Direction" 197 "Left From Path Direction" 198 "Left From Path Direction" 199 "Left From Path Direction" 200 "Left From Path Direction" 201 "Left From Path Direction" 202 "Left From Path Direction" 203 "Left From Path Direction" 204 "Left From Path Direction" 205 "Left From Path Direction" 206 "Left From Path Direction" 207 "Left From Path Direction" 208 "Left From Path Direction" 209 "Left From Path Direction" 210 "Left From Path Direction" 211 "Left From Path Direction" 212 "Left From Path Direction" 213 "Left From Path Direction" 214 "Left From Path Direction" 215 "Left From Path Direction" 216 "Left From Path Direction" 217 "Left From Path Direction" 218 "Left From Path Direction" 219 "Left From Path Direction" 220 "Left From Path Direction" 221 "Left From Path Direction" 222 "Left From Path Direction" 223 "Left From Path Direction" 224 "Left From Path Direction" 225 "Left From Path Direction" 226 "Left From Path Direction" 227 "Left From Path Direction" 228 "Left From Path Direction" 229 "Left From Path Direction" 230 "Left From Path Direction" 231 "Left From Path Direction" 232 "Left From Path Direction" 233 "Left From Path Direction" 234 "Left From Path Direction" 235 "Left From Path Direction" 236 "Left From Path Direction" 237 "Left From Path Direction" 238 "Left From Path Direction" 239 "Left From Path Direction" 240 "Left From Path Direction" 241 "Left From Path Direction" 242 "Left From Path Direction" 243 "Left From Path Direction" 244 "Left From Path Direction" 245 "Left From Path Direction" 246 "Left From Path Direction" 247 "Left From Path Direction" 248 "Left From Path Direction" 249 "Left From Path Direction" 250 "Left From Path Direction" 251 "Left From Path Direction" 252 "Left From Path Direction" 253 "1.417 Degrees left (358.583 Degrees Right)" 254 "Unknown" 255 "Invalid" ;
VAL_ 1317 EHU_GPSLongi 359991 "Invalid" ;
VAL_ 1317 EHU_GPSLati 180000 "Invalid" ;
VAL_ 1318 EHU_IntegtCrsSwt 0 "Default" 1 "Switch Off" 2 "Switch On" 3 "Fault" ;
VAL_ 1318 EHU_IntegtCrsModSet 0 "Default" 1 "ACC" 2 "TJA-ICA" 3 "HWA" ;
VAL_ 1318 EHU_LaneSprtSwt 0 "Default" 1 "Switch Off" 2 "Switch On" 3 "Fault" ;
VAL_ 1318 EHU_LaneSprtTypSet 0 "Default" 1 "LDW" 2 "LDW RDP ELK" 3 "Reserved" ;
VAL_ 1318 EHU_FCWFCTASwt 0 "Default" 1 "Switch Off" 2 "Switch On" 3 "Fault" ;
VAL_ 1318 EHU_AEBFCTBSwt 0 "Default" 1 "Switch Off" 2 "Switch On" 3 "Fault" ;
VAL_ 1318 EHU_ESSSwt 0 "Default" 1 "Switch Off" 2 "Switch On" 3 "Fault" ;
VAL_ 1318 EHU_LDWAlrmTypReq 0 "Default" 1 "(dbc not readable)" 2 "(dbc not readable)" 3 "Reserved" ;
VAL_ 1318 EHU_ADASSnvtySet 0 "Default" 1 "Low" 2 "High" 3 "Fault" ;
VAL_ 1318 EHU_HiwayExitAuxReq 0 "Not Active" 1 "Active" ;
VAL_ 1318 EHU_HiwayExitAuxSwt 0 "Default" 1 "Switch Off" 2 "Switch On" 3 "Reserved" ;
VAL_ 1318 EHU_VoiceSpdRgln_ADAS 255 "Invalid" ;
VAL_ 1319 EHU_DrvrSts 0 "(dbc not readable)" 1 "(dbc not readable)" 2 "(dbc not readable)" 3 "(dbc not readable)" 4 "Reserved" 5 "Reserved" 6 "Reserved" 7 "Reserved" ;
VAL_ 1319 EHU_DrvrOccpy 0 "Driver In Seat" 1 "Drive Not In Seat" 2 "No Detection" 3 "Reserved" ;
VAL_ 1328 EHU_NavSpdLimUnit 0 "Unknown" 1 "MPH" 2 "KMH" 3 "Reserved" ;
VAL_ 1328 EHU_NavSpdLimSts 0 "SL_Unknown" 1 "SL_Exists" 2 "SL_Nolimit" 3 "SL_Plural" ;
VAL_ 1328 EHU_NavSpdLim 0 "No Display" 1 "SPL 5" 2 "SPL 10" 3 "SPL 15" 4 "SPL 20" 5 "SPL 25" 26 "SPL 130" 27 "Reserved" 28 "Reserved" 29 "Reserved" 30 "Reserved" 31 "Reserved" 32 "Reserved" 33 "Reserved" 34 "Reserved" 35 "Reserved" 36 "Reserved" 37 "Reserved" 38 "Reserved" 39 "Reserved" 40 "Reserved" 41 "Reserved" 42 "Reserved" 43 "Reserved" 44 "Reserved" 45 "Reserved" 46 "Reserved" 47 "Reserved" 48 "Reserved" 49 "Reserved" 50 "Reserved" 51 "Reserved" 52 "Reserved" 53 "Reserved" 54 "Reserved" 55 "Reserved" 56 "Reserved" 57 "Reserved" 58 "Reserved" 59 "Reserved" 60 "Reserved" 61 "Reserved" 62 "Reserved" 63 "Reserved" ;
VAL_ 1329 ICM_TotMilgVld_ODO 0 "Value OK" 1 "Value Unreliable" ;
VAL_ 1329 ICM_DispVehSpdUnit 0 "KMH" 1 "MPH" ;
VAL_ 1329 ICM_ADASSigFlt 0 "No Failure" 1 "Reversible Failure" 2 "Irrversible Failure" 3 "Reserved" ;
VAL_ 1329 ICM_DispFlt 0 "No Error" 1 "Error" ;
VAL_ 626 status_acc_z 0 "Init" 1 "Sporadic_Error" 2 "Permanent_Error" 3 "Valid" ;
VAL_ 626 status_acc_y 0 "Init" 1 "Sporadic_Error" 2 "Permanent_Error" 3 "Valid" ;
VAL_ 626 status_acc_x 0 "Init" 1 "Sporadic_Error" 2 "Permanent_Error" 3 "Valid" ;
VAL_ 627 status_rate_z 0 "Init" 1 "Sporadic_Error" 2 "Permanent_Error" 3 "Valid" ;
VAL_ 627 status_rate_y 0 "Init" 1 "Sporadic_Error" 2 "Permanent_Error" 3 "Valid" ;
VAL_ 627 status_rate_x 0 "Init" 1 "Sporadic_Error" 2 "Permanent_Error" 3 "Valid" ;
VAL_ 1051 PtFxLimit 65534 "Init" 65535 "Fehler" ;
VAL_ 1051 PtFxTarget 65534 "Init" 65535 "Fehler" ;
VAL_ 1051 McamLongState 0 "Off" 1 "Passive" 2 "Active" 3 "Failure" ;
VAL_ 336 MCU_F_CrtSpd 65535 "Invalid" ;
VAL_ 336 MCU_F_CrtSpdSigVld 0 "Initializing" 1 "Valid" 2 "Invalid" 3 "Reserved" ;
VAL_ 337 MCU_R_CrtSpd 65535 "Invalid" ;
VAL_ 337 MCU_R_CrtSpdSigVld 0 "Initializing" 1 "Valid" 2 "Invalid" 3 "Reserved" ;
VAL_ 1300 MFS_LeRollPress 0 "No Pressed" 1 "Pressed" 2 "Long Press" 3 "(dbc not readable)" ;
VAL_ 1300 MFS_RiRollPress 0 "No Pressed" 1 "Pressed" 2 "Long Press" 3 "Reserved" ;
VAL_ 820 MPC_FrntCamBli 0 "No Blind" 1 "Blind" 2 "Reserved" 3 "Reserved" ;
VAL_ 820 MPC_FrntCamFlt 0 "No Failure" 1 "Reversible Failure" 2 "Irrversible Failure" 3 "Reserved" ;
VAL_ 448 ADAS_LatMtnCtrlSts 0 "Inactive" 1 "Active" ;
VAL_ 448 ADAS_WarnVbrnReq 0 "Inactive" 1 "Active" ;
VAL_ 448 ADAS_LatMtnTypExed 0 "Off" 1 "Comfort" 2 "Emergency" 3 "Reserved" 4 "Reserved" 5 "Reserved" 6 "Reserved" 7 "Reserved" ;
VAL_ 448 ADAS_LeTrunLampReq 0 "No Request" 1 "Request On" 2 "Request Off" 3 "Reserved" ;
VAL_ 448 ADAS_RiTrunLampReq 0 "No Request" 1 "Request On" 2 "Request Off" 3 "Reserved" ;
VAL_ 596 ADAS_TqReq_ACC 0 "No Request" 1 "Request" ;
VAL_ 596 ADAS_Sts_ACC 0 "Off" 1 "Passive" 2 "Standby" 3 "Active_Control" 4 "Brake Only" 5 "Override" 6 "Stand Active" 7 "Stand Wait" 8 "Reversible_Failure" 9 "Irreversible_Failure" 10 "ACTIVE_INTERVAL" 11 "Reserved" 12 "Reserved" 13 "Reserved" 14 "Reserved" 15 "Reserved" ;
VAL_ 596 ADAS_DecelToStopReq_ACC 0 "No Request" 1 "Request" ;
VAL_ 596 ADAS_TarAReq_ACC 0 "No Request" 1 "Request" ;
VAL_ 596 ADAS_DrvOffReq_ACC 0 "No Request" 1 "Request" ;
VAL_ 601 ADAS_Req_Prefill 0 "Not Active" 1 "Active" ;
VAL_ 601 ADAS_Req_HBA 0 "Not active" 1 "Active" ;
VAL_ 601 ADAS_Req_AWB 0 "Not Active" 1 "Active" ;
VAL_ 601 ADAS_Lvl_HBA 0 "Level 0" 1 "Level 1" 2 "Level 2" 3 "Level 3" 4 "Reserved" 5 "Reserved" 6 "Reserved" 7 "Reserved" ;
VAL_ 601 ADAS_Lvl_AWB 0 "No Request" 1 "Profile 1 - AEB low brk jerk" 2 "Profile 2 - AEB med. brk jerk" 3 "Profile 3 - AEB strong brk. jerk" 4 "Profile 4 - TOR lvl 1 HF" 5 "Profile 5 - TOR lvl 2 HF" 6 "Profile 6 -" 7 "Profile 7 -" ;
VAL_ 601 ADAS_DecelTyp_AEB 0 "Default" 1 "AEB" 2 "AEB~VRU" 3 "AEB~CYCLIST" 4 "EBA" 5 "FCTB" 6 "Reserved" 7 "Reserved" 8 "Reserved" 9 "Reserved" 10 "Reserved" 11 "Reserved" 12 "Reserved" 13 "Reserved" 14 "Reserved" 15 "Reserved" ;
VAL_ 602 ADAS_Req_Prefill 0 "Not Active" 1 "Active" ;
VAL_ 602 ADAS_Req_HBA 0 "Not active" 1 "Active" ;
VAL_ 602 ADAS_Req_AWB 0 "Not Active" 1 "Active" ;
VAL_ 602 ADAS_Lvl_HBA 0 "Level 0" 1 "Level 1" 2 "Level 2" 3 "Level 3" 4 "Reserved" 5 "Reserved" 6 "Reserved" 7 "Reserved" ;
VAL_ 602 ADAS_Lvl_AWB 0 "No Request" 1 "Profile 1 - AEB low brk jerk" 2 "Profile 2 - AEB med. brk jerk" 3 "Profile 3 - AEB strong brk. jerk" 4 "Profile 4 - TOR lvl 1 HF" 5 "Profile 5 - TOR lvl 2 HF" 6 "Profile 6 -" 7 "Profile 7 -" ;
VAL_ 602 ADAS_DecelTyp_AEB 0 "Default" 1 "AEB" 2 "AEB~VRU" 3 "AEB~CYCLIST" 4 "EBA" 5 "FCTB" 6 "Reserved" 7 "Reserved" 8 "Reserved" 9 "Reserved" 10 "Reserved" 11 "Reserved" 12 "Reserved" 13 "Reserved" 14 "Reserved" 15 "Reserved" ;
VAL_ 603 ADAS_Fwd_Safety_Func 0 "NoSafetyFunctionRequest" 1 "BrakeKeepHolding" 4097 "Cfm_BrakeKeepHolding" 4098 "Cfm_StartPrevention" 4100 "Cfm_AutomaticEvasiveSteering" 4104 "Cfm_EvasiveSteeringSupport" 4112 "Cfm_Prefill" 4128 "Cfm_PartialBrake" 4160 "Cfm_FullBrake" 4224 "Cfm_EmergencyBrakeAssist" 4608 "Cfm_WarnOptic" 5120 "Cfm_WarnAcoustic" 6144 "Cfm_WarnHaptic" 8193 "Tixl_BrakeKeepHolding" 8194 "Tixl_StartPrevention" 8196 "Tixl_AutomaticEvasiveSteering" 8200 "Tixl_EvasiveSteeringSupport" 8208 "Tixl_Prefill" 8224 "Tixl_PartialBrake" 8256 "Tixl_FullBrake" 8320 "Tixl_EmergencyBrakeAssist" 8704 "Tixl_WarnOptic" 9216 "Tixl_WarnAcoustic" 10240 "Tixl_WarnHaptic" 16385 "TiplTurn_BrakeKeepHolding" 16386 "TiplTurn_StartPrevention" 16388 "TiplTurn_AutomaticEvasiveSteerin" 16392 "TiplTurn_EvasiveSteeringSupport" 16400 "TiplTurn_Prefill" 16416 "TiplTurn_PartialBrake" 16448 "TiplTurn_FullBrake" 16512 "TiplTurn_EmergencyBrakeAssist" 16896 "TiplTurn_WarnOptic" 17408 "TiplTurn_WarnAcoustic" 18432 "TiplTurn_WarnHaptic" 32769 "TiplLong_BrakeKeepHolding" 32770 "TiplLong_StartPrevention" 32772 "TiplLong_AutomaticEvasiveSteerin" 32776 "TiplLong_EvasiveSteeringSupport" 32784 "TiplLong_Prefill" 32800 "TiplLong_PartialBrake" 32832 "TiplLong_FullBrake" 32896 "TiplLong_EmergencyBrakeAssist" 33024 "TiplLong_LatentInfo" 33280 "TiplLong_WarnOptic" 33792 "TiplLong_WarnAcoustic" 34816 "TiplLong_WarnHaptic" 65535 "Invalid" ;
VAL_ 812 ADAS_Sts_LKA 0 "Off" 1 "Passive" 2 "Standby" 3 "Active" 4 "Fault" 5 "Reserved" 6 "Reserved" 7 "Reserved" ;
VAL_ 812 ADAS_Sts_TJAICA 0 "Off" 1 "Passive" 2 "Standby" 3 "Active" 4 "Fault" 5 "Reserved" 6 "Reserved" 7 "Reserved" ;
VAL_ 812 ADAS_FCWSnvty 0 "Default" 1 "Low Sensitivity" 2 "Medium Sensitivity" 3 "High Sensitivity" ;
VAL_ 812 ADAS_ADASSnvtySetFb 0 "Default" 1 "Low (newbie mode)" 2 "High (normal mode)" 3 "Reserved" ;
VAL_ 812 ADAS_SysWarnTyp 0 "(dbc not readable)" 1 "(dbc not readable)" 2 "Invalid" 3 "Reserved" 4 "Reserved" 5 "Reserved" 6 "Reserved" 7 "Reserved" ;
VAL_ 812 ADAS_Sts_ELK_re 0 "Off" 1 "Passive" 2 "Standby" 3 "Active" 4 "Fault" 5 "Reserved" 6 "Reserved" 7 "Reserved" ;
VAL_ 812 ADAS_HandsOffTakeOverReq 0 "Inactive" 1 "Active" ;
VAL_ 812 ADAS_IntvMod_ELK 0 "Off" 1 "Road Edge" 2 "Overtaking" 3 "Oncoming" ;
VAL_ 812 ADAS_IntvDir_ELK 0 "Undefined" 1 "Left" 2 "Right" 3 "Reserved" ;
VAL_ 812 ADAS_Sts_RDP 0 "Off" 1 "Passive" 2 "Standby" 3 "Active" 4 "Fault" 5 "Reserved" 6 "Reserved" 7 "Reserved" ;
VAL_ 812 ADAS_Sts_LDW 0 "Off" 1 "Passive" 2 "Standby" 3 "Active" 4 "Fault" 5 "Reserved" 6 "Reserved" 7 "Reserved" ;
VAL_ 812 ADAS_AudioWarn 0 "Inactive" 1 "Active" ;
VAL_ 812 ADAS_LatMtnColor 0 "Off(No Display)" 1 "Passive(No Display)" 2 "Standby(White)" 3 "Active(Blue)" 4 "Fault(No Display)" 5 "(dbc not readable)" 6 "Reserved" 7 "Reserved" ;
VAL_ 812 ADAS_DispReq 0 "Default" 1 "No Display" 2 "Display" 3 "Reserved" ;
VAL_ 812 ADAS_Sts_ELK_oc 0 "Off" 1 "Passive" 2 "Standby" 3 "Active" 4 "Fault" 5 "Reserved" 6 "Reserved" 7 "Reserved" ;
VAL_ 812 ADAS_Sts_ELK_ot 0 "Off" 1 "Passive" 2 "Standby" 3 "Active" 4 "Fault" 5 "Reserved" 6 "Reserved" 7 "Reserved" ;
VAL_ 828 ADAS_Warn_FCW 0 "No Warning" 1 "Latent Warning" 2 "Prewarning" 3 "Acutewarning" ;
VAL_ 828 ADAS_WarnTyp_FCWAEB 0 "Reserved" 1 "Unknown" 2 "Pedestrian" 3 "Car" 4 "Truck" 5 "Cyclist" 6 "Bus" 7 "Reserved" ;
VAL_ 828 ADAS_Sts_FCW 0 "Off" 1 "Reserved" 2 "Standby" 3 "Active" 4 "Fault" 5 "Reserved" 6 "Reserved" 7 "Reserved" ;
VAL_ 828 ADAS_Sts_AEB 0 "Off" 1 "Reserved" 2 "Standby" 3 "Active" 4 "Fault" 5 "Reserved" 6 "Reserved" 7 "Reserved" ;
VAL_ 830 MRR_FrntSnsrFlt 0 "No Failure" 1 "Reversible Failure" 2 "Irrversible Failure" 3 "Reserved" ;
VAL_ 830 MRR_FrntSnsrBli 0 "No Blind" 1 "Blind" 2 "Reserved" 3 "Reserved" ;
VAL_ 832 ADAS_LaneCrvt 63 "Straight Lane" 127 "No Display" ;
VAL_ 832 ADAS_LeLineTyp 0 "Default" 1 "Solid Lane" 2 "Dashed Lane(Alc)" 3 "Reserved" ;
VAL_ 832 ADAS_RiLineTyp 0 "Default" 1 "Solid Lane" 2 "Dashed Lane(Alc)" 3 "Reserved" ;
VAL_ 832 ADAS_LeLineColor 0 "Gray" 1 "White" 2 "Blue(Alc)" 3 "Red" ;
VAL_ 832 ADAS_RiLineColor 0 "Gray" 1 "White" 2 "Blue(Alc)" 3 "Red" ;
VAL_ 832 ADAS_LeLineDst 125 "Invalid" 126 "Invalid" 127 "Invalid" ;
VAL_ 832 ADAS_RiLineDst 125 "Invalid" 126 "Invalid" 127 "Invalid" ;
VAL_ 832 ADAS_LeLineFlash 0 "No Flash" 1 "Flash" 2 "Reserved" 3 "Reserved" ;
VAL_ 832 ADAS_RiLineFlash 0 "No Flash" 1 "Flash" 2 "Reserved" 3 "Reserved" ;
VAL_ 832 ADAS_ESSSwtFb 0 "Default" 1 "Switch Off" 2 "Switch On" 3 "Fault" ;
VAL_ 832 ADAS_IntegtCrsSwtFb 0 "Default" 1 "Switch Off" 2 "Switch On" 3 "Fault" ;
VAL_ 832 ADAS_IntegtCrsModSetFb 0 "Default" 1 "ACC" 2 "TJA-ICA" 3 "HWA" ;
VAL_ 832 ADAS_LaneSprtSwtFb 0 "Default" 1 "Switch Off" 2 "Switch On" 3 "Fault" ;
VAL_ 832 ADAS_LaneSprtTypSetFb 0 "Default" 1 "LDW" 2 "LDW RDP ELK" 3 "Reserved" ;
VAL_ 832 ADAS_FCWFCTASwtFb 0 "Default" 1 "Switch Off" 2 "Switch On" 3 "Fault" ;
VAL_ 832 ADAS_AEBFCTBSwtFb 0 "Default" 1 "Switch Off" 2 "Switch On" 3 "Fault" ;
VAL_ 832 ADAS_FltIndcr 0 "Default" 1 "No Fault" 2 "Fault" 3 "Dynamic Calibration Running" ;
VAL_ 832 ADAS_VoiceSpdRglnFb 0 "Default" 1 "Ok" 2 "Reject" 3 "Reserved" ;
VAL_ 832 ADAS_IntegtCrsFltTxt 0 "Default" 1 "(dbc not readable)" ;
VAL_ 832 ADAS_LaneSprtFltTxt 0 "Default" 1 "(dbc not readable)" ;
VAL_ 832 ADAS_FwdWarnFltTxt 0 "Default" 1 "(dbc not readable)" ;
VAL_ 832 ADAS_IntecnFltTxt 0 "Default" 1 "(dbc not readable)" ;
VAL_ 832 ADAS_ACCIconDisp 0 "No Display" 1 "White" 2 "Green" 3 "Fault" 4 "Reserved" 5 "Reserved" 6 "Reserved" 7 "Reserved" ;
VAL_ 838 ADAS_FrntTar1X_ACC 255 "Invalid" ;
VAL_ 838 ADAS_FrntTar1Y_ACC 255 "Invalid" ;
VAL_ 838 ADAS_FrntTar2X_ACC 255 "Invalid" ;
VAL_ 838 ADAS_FrntTar2Y_ACC 255 "Invalid" ;
VAL_ 838 ADAS_LeFrntTarX_ACC 255 "Invalid" ;
VAL_ 838 ADAS_LeFrntTarY_ACC 255 "Invalid" ;
VAL_ 838 ADAS_RiFrntTarX_ACC 255 "Invalid" ;
VAL_ 838 ADAS_RiFrntTarY_ACC 255 "Invalid" ;
VAL_ 839 ADAS_FrntTar1Typ_ACC 0 "No Display" 1 "Car" 2 "Truck" 3 "Motor/Bicycle" 4 "Reserved" 5 "Reserved" 6 "Reserved" 7 "Reserved" ;
VAL_ 839 ADAS_FrntTar2Typ_ACC 0 "No Display" 1 "Car" 2 "Truck" 3 "Motor/Bicycle" 4 "Reserved" 5 "Reserved" 6 "Reserved" 7 "Reserved" ;
VAL_ 839 ADAS_DispSpdUnit_ACC 0 "KMH" 1 "MPH" ;
VAL_ 839 ADAS_LeFrntTarTyp_ACC 0 "No Display" 1 "Car" 2 "Truck" 3 "Motor/Bicycle" 4 "Reserved" 5 "Reserved" 6 "Reserved" 7 "Reserved" ;
VAL_ 839 ADAS_RiFrntTarTyp_ACC 0 "No Display" 1 "Car" 2 "Truck" 3 "Motor/Bicycle" 4 "Reserved" 5 "Reserved" 6 "Reserved" 7 "Reserved" ;
VAL_ 839 ADAS_OperTxt 0 "Default" 1 "(dbc not readable)" 2 "(dbc not readable)" 3 "(dbc not readable)" 4 "(dbc not readable)" 5 "(dbc not readable)" 6 "(dbc not readable)" 7 "(dbc not readable)" 8 "(dbc not readable)" 9 "(dbc not readable)" 10 "(dbc not readable)" 11 "Reserved" 12 "Reserved" 13 "Reserved" 14 "Reserved" 15 "(dbc not readable)" ;
VAL_ 839 ADAS_TiGapSet_ACC 0 "Inactive/Default" 1 "1 gear 1" 2 "2 gear 2" 3 "3 gear 3" 4 "4 gear 4" 5 "5 gear 5" 6 "Reserved" 7 "Invalid" ;
VAL_ 839 ADAS_TakeOverReq_ACC 0 "No request" 1 "Request" ;
VAL_ 839 ADAS_DispSpd_ACC 0 "(dbc not readable)" 1 "(dbc not readable)" 2 "(dbc not readable)" 3 "(dbc not readable)" 4 "(dbc not readable)" 5 "(dbc not readable)" 6 "(dbc not readable)" 7 "(dbc not readable)" 8 "(dbc not readable)" 9 "(dbc not readable)" 10 "(dbc not readable)" 11 "(dbc not readable)" 12 "(dbc not readable)" 13 "(dbc not readable)" 14 "(dbc not readable)" 15 "(dbc not readable)" 16 "(dbc not readable)" 17 "(dbc not readable)" 18 "(dbc not readable)" 19 "(dbc not readable)" 20 "(dbc not readable)" 21 "(dbc not readable)" 22 "(dbc not readable)" 23 "(dbc not readable)" 24 "(dbc not readable)" 25 "(dbc not readable)" 26 "(dbc not readable)" 27 "(dbc not readable)" 28 "(dbc not readable)" 29 "(dbc not readable)" 30 "(dbc not readable)" 31 "(dbc not readable)" 32 "(dbc not readable)" 33 "(dbc not readable)" 34 "(dbc not readable)" 35 "(dbc not readable)" 36 "(dbc not readable)" 37 "(dbc not readable)" 38 "(dbc not readable)" 39 "(dbc not readable)" 40 "(dbc not readable)" 41 "(dbc not readable)" 42 "(dbc not readable)" 43 "(dbc not readable)" 44 "(dbc not readable)" 45 "(dbc not readable)" 46 "(dbc not readable)" 47 "(dbc not readable)" 48 "(dbc not readable)" 49 "(dbc not readable)" 50 "(dbc not readable)" 51 "(dbc not readable)" 52 "(dbc not readable)" 53 "(dbc not readable)" 54 "(dbc not readable)" 55 "(dbc not readable)" 56 "(dbc not readable)" 57 "(dbc not readable)" 58 "(dbc not readable)" 59 "(dbc not readable)" 60 "(dbc not readable)" 61 "(dbc not readable)" 62 "(dbc not readable)" 63 "(dbc not readable)" 64 "(dbc not readable)" 65 "(dbc not readable)" 66 "(dbc not readable)" 67 "(dbc not readable)" 68 "(dbc not readable)" 69 "(dbc not readable)" 70 "(dbc not readable)" 71 "(dbc not readable)" 72 "(dbc not readable)" 73 "(dbc not readable)" 74 "(dbc not readable)" 75 "(dbc not readable)" 76 "(dbc not readable)" 77 "(dbc not readable)" 78 "(dbc not readable)" 79 "(dbc not readable)" 80 "(dbc not readable)" 81 "(dbc not readable)" 82 "(dbc not readable)" 83 "(dbc not readable)" 84 "(dbc not readable)" 85 "(dbc not readable)" 86 "(dbc not readable)" 87 "(dbc not readable)" 88 "(dbc not readable)" 89 "(dbc not readable)" 90 "(dbc not readable)" 91 "(dbc not readable)" 92 "(dbc not readable)" 93 "(dbc not readable)" 94 "(dbc not readable)" 95 "(dbc not readable)" 96 "(dbc not readable)" 97 "(dbc not readable)" 98 "(dbc not readable)" 99 "(dbc not readable)" 100 "(dbc not readable)" 101 "(dbc not readable)" 102 "(dbc not readable)" 103 "(dbc not readable)" 104 "(dbc not readable)" 105 "(dbc not readable)" 106 "(dbc not readable)" 107 "(dbc not readable)" 108 "(dbc not readable)" 109 "(dbc not readable)" 110 "(dbc not readable)" 111 "(dbc not readable)" 112 "(dbc not readable)" 113 "(dbc not readable)" 114 "(dbc not readable)" 115 "(dbc not readable)" 116 "(dbc not readable)" 117 "(dbc not readable)" 118 "(dbc not readable)" 119 "(dbc not readable)" 120 "(dbc not readable)" 121 "(dbc not readable)" 122 "(dbc not readable)" 123 "(dbc not readable)" 124 "(dbc not readable)" 125 "(dbc not readable)" 126 "(dbc not readable)" 127 "(dbc not readable)" 128 "(dbc not readable)" 129 "(dbc not readable)" 130 "(dbc not readable)" 131 "(dbc not readable)" 132 "(dbc not readable)" 133 "(dbc not readable)" 134 "(dbc not readable)" 135 "(dbc not readable)" 136 "(dbc not readable)" 137 "(dbc not readable)" 138 "(dbc not readable)" 139 "(dbc not readable)" 140 "(dbc not readable)" 141 "(dbc not readable)" 142 "(dbc not readable)" 143 "(dbc not readable)" 144 "(dbc not readable)" 145 "(dbc not readable)" 146 "(dbc not readable)" 147 "(dbc not readable)" 148 "(dbc not readable)" 149 "(dbc not readable)" 150 "(dbc not readable)" 151 "(dbc not readable)" 152 "(dbc not readable)" 153 "(dbc not readable)" 154 "(dbc not readable)" 155 "(dbc not readable)" 156 "(dbc not readable)" 157 "(dbc not readable)" 158 "(dbc not readable)" 159 "(dbc not readable)" 160 "(dbc not readable)" 161 "(dbc not readable)" 162 "(dbc not readable)" 163 "(dbc not readable)" 164 "(dbc not readable)" 165 "(dbc not readable)" 166 "(dbc not readable)" 167 "(dbc not readable)" 168 "(dbc not readable)" 169 "(dbc not readable)" 170 "(dbc not readable)" 171 "(dbc not readable)" 172 "(dbc not readable)" 173 "(dbc not readable)" 174 "(dbc not readable)" 175 "(dbc not readable)" 176 "(dbc not readable)" 177 "(dbc not readable)" 178 "(dbc not readable)" 179 "(dbc not readable)" 180 "(dbc not readable)" 181 "(dbc not readable)" 182 "(dbc not readable)" 183 "(dbc not readable)" 184 "(dbc not readable)" 185 "(dbc not readable)" 186 "(dbc not readable)" 187 "(dbc not readable)" 188 "(dbc not readable)" 189 "(dbc not readable)" 190 "(dbc not readable)" 191 "(dbc not readable)" 192 "(dbc not readable)" 193 "(dbc not readable)" 194 "(dbc not readable)" 195 "(dbc not readable)" 196 "(dbc not readable)" 197 "(dbc not readable)" 198 "(dbc not readable)" 199 "(dbc not readable)" 200 "(dbc not readable)" 201 "(dbc not readable)" 202 "(dbc not readable)" 203 "(dbc not readable)" 204 "(dbc not readable)" 205 "(dbc not readable)" 206 "(dbc not readable)" 207 "(dbc not readable)" 208 "(dbc not readable)" 209 "(dbc not readable)" 210 "(dbc not readable)" 211 "(dbc not readable)" 212 "(dbc not readable)" 213 "(dbc not readable)" 214 "(dbc not readable)" 215 "(dbc not readable)" 216 "(dbc not readable)" 217 "(dbc not readable)" 218 "(dbc not readable)" 219 "(dbc not readable)" 220 "(dbc not readable)" 221 "(dbc not readable)" 222 "(dbc not readable)" 223 "(dbc not readable)" 224 "(dbc not readable)" 225 "(dbc not readable)" 226 "(dbc not readable)" 227 "(dbc not readable)" 228 "(dbc not readable)" 229 "(dbc not readable)" 230 "(dbc not readable)" 231 "(dbc not readable)" 232 "(dbc not readable)" 233 "(dbc not readable)" 234 "(dbc not readable)" 235 "(dbc not readable)" 236 "(dbc not readable)" 237 "(dbc not readable)" 238 "(dbc not readable)" 239 "(dbc not readable)" 240 "(dbc not readable)" 241 "(dbc not readable)" 242 "(dbc not readable)" 243 "(dbc not readable)" 244 "(dbc not readable)" 245 "(dbc not readable)" 246 "(dbc not readable)" 247 "(dbc not readable)" 248 "(dbc not readable)" 249 "(dbc not readable)" 250 "(dbc not readable)" 251 "(dbc not readable)" 252 "(dbc not readable)" 253 "(dbc not readable)" 254 "(dbc not readable)" 255 "(dbc not readable)" ;
VAL_ 839 ADAS_Sts_ACC_ICC 0 "Off" 1 "Passive" 2 "Standby" 3 "Active_Control" 4 "Brake Only" 5 "Override" 6 "Stand Active" 7 "Stand Wait" 8 "REVERSIBLE_FAILURE" 9 "IRREVERSIBLE_FAILURE" 10 "ACTIVE_INTERVAL" 11 "Reserved" 12 "Reserved" 13 "Reserved" 14 "Reserved" 15 "Reserved" ;
VAL_ 839 ADAS_SpdLimUnit_ASL 0 "Unknown" 1 "KMH" 2 "MPH" 3 "Reserved" ;
VAL_ 839 ADAS_SpdLim_ASL 255 "(dbc not readable)" ;
VAL_ 839 ADAS_SpdLimSts_ASL 0 "OFF" 1 "STANDBY" 2 "ACTIVE" 3 "OVERRIDE" 4 "REVERSIBLE_FAILURE" 5 "IREVERSIBLE_FAILURE" 6 "Reserved" 7 "Reserved" ;
VAL_ 819 PEPS_PwrMod 0 "Off" 1 "ACC (Reserved)" 2 "IGN On" 3 "Crank Pending" 4 "Run" 5 "Crank Off (Reserved)" 6 "Reserved" 7 "Reserved" ;
VAL_ 819 PEPS_PwrModVld 0 "Initializing" 1 "Valid" 2 "Invalid" 3 "Reserved" ;
VAL_ 1137 PLG_TrSwtStsIndcn 0 "Trunk Closed" 1 "Trunk Open Fully" 2 "Trunk Halt" 3 "Trunk Opening" 4 "Trunk Closing" 5 "Reserved" 6 "Reserved" 7 "Reserved" ;
VAL_ 1052 DriverRqPtFxDominant 0 "no override" 1 "override by driver" ;
VAL_ 1052 PtFxRequested 65534 "Init" 65535 "Fehler" ;
VAL_ 1052 PtFxActual 65534 "Init" 65535 "Fehler" ;
VAL_ 1052 PtFxMax 65534 "Init" 65535 "Fehler" ;
VAL_ 1052 PtFxMin 65534 "Init" 65535 "Fehler" ;
VAL_ 1764 RBFMain11_ParkBrakeSupportReq 0 "ParkSupport_NoRequest" 1 "ParkSupport_ActiveRequest" ;
VAL_ 1764 RBFMain11_ParkBrakeState 0 "ParkBrakeState_Unknown" 1 "ParkBrakeState_Applying" 2 "ParkBrakeState_Applied" 3 "ParkBrakeState_Releasing" 4 "ParkBrakeState_Released" ;
VAL_ 1764 RBFMain11_ParkBrakeAvl 0 "NotInitialized" 1 "Fault" 2 "FullNoDriverRelease" 3 "Full" ;
VAL_ 1764 RBFMain11_ParkBrakeCapability 0 "None" 1 "Reduced" 2 "Full" ;
VAL_ 1764 RBFMain11_YawRateStabActivity 0 "StabilizationActivity_None" 1 "StabilizationActivity_Active" ;
VAL_ 1764 RBFMain11_YawRateStabAvl 0 "NotInitialized" 1 "Fault" 2 "Full" ;
VAL_ 1764 RBFMain11_AccStabActivity 0 "StabilizationActivity_None" 1 "StabilizationActivity_Active" ;
VAL_ 1764 RBFMain11_AccStabAvail 0 "NotInitialized" 1 "Fault" 2 "Full" ;
VAL_ 1764 RBFMain11_DecStabActivity 0 "DecelerationStabilizationActivity_None" 1 "DecelerationStabilizationActivity_AtLeastOneWheel" 2 "DecelerationStabilizationActivity_AtAllWheels" ;
VAL_ 1764 RBFMain11_DecStabCpbltyForDrvr 0 "None" 1 "Reduced" 2 "NoDragTorqueControl" 3 "Full" ;
VAL_ 1764 RBFMain11_DecStabAvlForDriver 0 "NotInitialized" 1 "Fault" 2 "Full" ;
VAL_ 1764 RBFMain11_DecStabCpblty 0 "None" 1 "Reduced" 2 "NoDragTorqueControl" 3 "Full" ;
VAL_ 1764 RBFMain11_DecStabAvail 0 "NotInitialized" 1 "Fault" 2 "Full" ;
VAL_ 1764 RBFMain11_BrakeFxAvailability 0 "NotInitialized" 1 "Fault" 2 "Full" ;
VAL_ 1764 RBFMain11_BrakeFxCapability 0 "BrakeFx_None" 1 "BrakeFx_ReducedPerformance" 2 "BrakeFx_FullPerformance" ;
VAL_ 1764 RBFMain11_usedChannel 0 "usedChannel_Instance1Com1" 1 "usedChannel_Instance1Com2" 2 "usedChannel_Instance2Com1" 3 "usedChannel_Instance2Com2" ;
VAL_ 1765 RBFMain12_BrkBckStgyVehStopAvl 0 "NotInitialized" 1 "None" 2 "Fault" 3 "TestPending" 4 "Full" ;
VAL_ 1765 RBFMain12_BrkBckStratFxCtrlAvl 0 "NotInitialized" 1 "None" 2 "Fault" 3 "TestPending" 4 "Full" ;
VAL_ 1765 RBFMain12_BrakeBckpStratState 0 "BrakeBackup_None" 1 "BrakeBackup_VehicleStopAutomated" 2 "BrakeBackup_FxControlAutomated" ;
VAL_ 1765 RBFMain12_BrkDiscTempStatusAvl 0 "NotInitialized" 1 "Fault" 2 "Full" ;
VAL_ 1765 RBFMain12_BrkDiscTempStatus 0 "BrakeDiscTemp_NormalRange" 1 "BrakeDiscTemp_WarningLevel1" 2 "BrakeDiscTemp_WarningLevel2" 3 "BrakeDiscTemp_WarningLevel3" ;
VAL_ 1765 RBFMain12_DriverReqParkBrake 0 "ParkBrake_NoRequest" 1 "ParkBrake_Release" 2 "ParkBrake_Apply" ;
VAL_ 1765 RBFMain12_DrvReqParkBrakeAvail 0 "NotInitialized" 1 "Fault" 2 "Full" ;
VAL_ 1765 RBFMain12_DrvReqFxBrkDomAvail 0 "NotInitialized" 1 "Fault" 2 "Full" ;
VAL_ 1765 RBFMain12_DrvPressBrkPedalAvl 0 "NotInitialized" 1 "Fault" 2 "Full" ;
VAL_ 1765 RBFMain12_DrvReqTarFxBrakeAvl 0 "NotInitialized" 1 "Fault" 2 "Full" ;
VAL_ 793 SDM_AirBagSysAlrmLampSts 0 "Lamp Off" 1 "Lamp Flash" 2 "Lamp On" 3 "Reserved" ;
VAL_ 793 SDM_DrverSecuBltAlrmSts 0 "Lamp Off(Safety Belt Tied)" 1 "Fault(Reserved)" 2 "Lamp On(Safety Belt Not Tied)" 3 "Reserved" ;
VAL_ 793 SDM_PassSecuBltAlrmSts 0 "Lamp Off(Safety Belt Tied)" 1 "Fault(Reserved)" 2 "Lamp On(Safety Belt Not Tied)" 3 "Reserved" ;
VAL_ 793 SDM_CllsnSig 0 "No Crash" 1 "Crash" ;
VAL_ 793 SDM_FrntCllsn 0 "(dbc not readable)" 1 "(dbc not readable)" ;
VAL_ 793 SDM_LeSideCllsn 0 "(dbc not readable)" 1 "(dbc not readable)" ;
VAL_ 793 SDM_RiSideCllsn 0 "(dbc not readable)" 1 "(dbc not readable)" ;
VAL_ 793 SDM_ReCllsn 0 "(dbc not readable)" 1 "(dbc not readable)" ;
VAL_ 1583 TBOX_CrtTi_Day 0 "Day1" 30 "Day31" ;
VAL_ 1583 TBOX_CrtTi_Hr 0 "Hour 0" 23 "Hour 23" ;
VAL_ 1583 TBOX_CrtTi_Mins 0 "Mintue 0" 59 "Mintue 59" ;
VAL_ 1583 TBOX_CrtTi_Yr 0 "Year 2015" 255 "Year2270" ;
VAL_ 1583 TBOX_CrtTi_Mth 0 "January" 11 "December" ;
VAL_ 1583 TBOX_CrtTi_Sec 0 "Second 0" 59 "Second 59" ;
VAL_ 1417 TPMS_TirePosn 0 "No Any Sensor" 1 "(dbc not readable)" 2 "(dbc not readable)" 3 "(dbc not readable)" 4 "(dbc not readable)" 5 "Reserved" 6 "Reserved" 7 "Reserved" ;
VAL_ 1417 TPMS_SngTirePSts 0 "(dbc not readable)" 1 "(dbc not readable)" 2 "(dbc not readable)" 3 "Reserved" ;
VAL_ 442 VCU_DrvrAPSPercVld 0 "Initializing" 1 "Valid" 2 "Invalid" 3 "Reserved" ;
VAL_ 442 VCU_WhlTqActVld 0 "Initializing" 1 "Valid" 2 "Invalid" 3 "Reserved" ;
VAL_ 532 VCU_RdyLamp 0 "(dbc not readable)" 1 "(dbc not readable)" ;
VAL_ 532 VCU_GearSigVld 0 "Initializing" 1 "Valid" 2 "Invalid" 3 "Reserved" ;
VAL_ 532 VCU_GearSig 0 "Undefined" 1 "P" 2 "N" 3 "R" 4 "D" 5 "Reserved" 6 "E" 7 "S" 8 "Reserved" 9 "Reserved" 10 "Reserved" 11 "Reserved" 12 "Reserved" 13 "Reserved" 14 "Reserved" 15 "Reserved" ;
VAL_ 532 VCU_DrvModSig 0 "(dbc not readable)" 1 "(dbc not readable)" 2 "(dbc not readable)" 3 "(dbc not readable)" 4 "Reserved" 5 "Reserved" 6 "Reserved" 7 "Reserved" ;
VAL_ 549 VCU_OverMod 0 "No Override" 1 "Driver Override" ;
VAL_ 549 VCU_MotChkACCFltFbFlg 0 "No Error" 1 "Reversible Error" 2 "Irreversible Error(Reserved)" 3 "Reserved" ;
VAL_ 549 VCU_VehTqFltSts 0 "No Failure" 1 "Failure" ;
VAL_ 1768 VMCMain11_ParkBrakeRequest 0 "ParkBrake_NoRequest" 1 "ParkBrake_Release" 2 "ParkBrake_Apply" ;
VAL_ 1768 VMCMain11_VehMotionCtrlAvl 0 "NotInitialized" 1 "Fault" 2 "Full" ;
VAL_ 1768 VMCMain11_WarningJerkRequest 0 "JerkRequest_None" 1 "JerkRequest_Level1" 2 "JerkRequest_Level2" 3 "JerkRequest_Level3" ;
VAL_ 1768 VMCMain11_BrakePrepReq 0 "BrakePreparation_NoRequest" 1 "BrakePreparation_Request" ;
VAL_ 1768 VMCMain11_BrakeFxActuationType 0 "BrakeFxActuationType_None" 1 "BrakeFxActuationType_Comfort" 2 "BrakeFxActuationType_Dynamic" 3 "BrakeFxActuationType_Emergency" ;
VAL_ 1768 VMCMain11_BrakeBackupStgyReq 0 "BrakeBackup_None" 1 "BrakeBackup_VehicleStopAutomated" 2 "BrakeBackup_FxControlAutomated" ;
VAL_ 1770 VMCMain12_BrkSrvReqStandstill 0 "StandstillService_None" 1 "StandstillService_ParkBrakeRelease" 2 "StandstillService_DriverControl" 3 "StandstillService_BrakeForceBuildUp" ;
VAL_ 578 YRS_YawRateCalSts 0 "Sensor Not Calibrated" 1 "Sensor Calibrated" ;
VAL_ 578 YRS_YawRateSnsrSts 0 "Initializing" 1 "Valid" 2 "Invalid" 3 "Reserved" ;
VAL_ 578 YRS_LatSnsrSts 0 "Initializing" 1 "Valid" 2 "Invalid" 3 "Reserved" ;
VAL_ 582 YRS_LgtSnsrSts 0 "Initializing" 1 "Valid" 2 "Invalid" 3 "Reserved" ;
